VERSION ""

NS_ :

BS_:

BU_: VSIM TTPM TCM SGW SCCM RF_HUB PTS PCM ORC ITBM IRCM IC FTM FDCM ETM ESM ESC ECM DTCM DIAGNOST CBC ATMM ASCM AFLS 4 _ 0 C I w E 6 S A V Vector__XXX T

BO_ 999 BU_NET_CFG_PT: 8 RF_HUB
 SG_ BU_NET_CFG_STAT_PT : 0|2@1+ (1,0) [0|0] "" SGW,CBC
 SG_ BU_NetCfg_ACC : 2|1@1+ (1,0) [0|0] "" SGW,CBC
 SG_ BU_NetCfg_ADCM : 3|1@1+ (1,0) [0|0] "" SGW,CBC
 SG_ BU_NetCfg_AHLM : 4|1@1+ (1,0) [0|0] "" SGW,CBC
 SG_ BU_NetCfg_VSIM_C : 5|1@1+ (1,0) [0|0] "" SGW,CBC
 SG_ BU_NetCfg_ASCM : 6|1@1+ (1,0) [0|0] "" SGW,CBC
 SG_ BU_NetCfg_CBC_PT : 7|1@1+ (1,0) [0|0] "" SGW,CBC
 SG_ BU_NetCfg_DTCM : 8|1@1+ (1,0) [0|0] "" SGW,CBC
 SG_ BU_NetCfg_ECM : 9|1@1+ (1,0) [0|0] "" SGW,CBC
 SG_ BU_NetCfg_EPS : 10|1@1+ (1,0) [0|0] "" SGW,CBC
 SG_ BU_NetCfg_ESM : 11|1@1+ (1,0) [0|0] "" SGW,CBC
 SG_ BU_NetCfg_ESC : 12|1@1+ (1,0) [0|0] "" SGW,CBC
 SG_ BU_NetCfg_EPB : 13|1@1+ (1,0) [0|0] "" SGW,CBC
 SG_ BU_NetCfg_RF_HUB : 14|1@1+ (1,0) [0|0] "" SGW,CBC
 SG_ BU_NetCfg_IC : 15|1@1+ (1,0) [0|0] "" SGW,CBC
 SG_ BU_NetCfg_DASM : 16|1@1+ (1,0) [0|0] "" SGW,CBC
 SG_ BU_NetCfg_FDCM : 17|1@1+ (1,0) [0|0] "" SGW,CBC
 SG_ BU_NetCfg_EPPM : 18|1@1+ (1,0) [0|0] "" SGW,CBC
 SG_ BU_NetCfg_ORC : 19|1@1+ (1,0) [0|0] "" SGW,CBC
 SG_ BU_NetCfg_PTS : 20|1@1+ (1,0) [0|0] "" SGW,CBC
 SG_ BU_NetCfg_SCCM : 23|1@1+ (1,0) [0|0] "" SGW,CBC
 SG_ BU_NetCfg_ELSD : 24|1@1+ (1,0) [0|0] "" SGW,CBC
 SG_ BU_NetCfg_TCM : 25|1@1+ (1,0) [0|0] "" SGW,CBC
 SG_ BU_NetCfg_TPM : 26|1@1+ (1,0) [0|0] "" SGW,CBC
 SG_ BU_NetCfg_PASS_PT : 27|1@1+ (1,0) [0|0] "" SGW,CBC
 SG_ BU_NetCfg_AFLS : 28|1@1+ (1,0) [0|0] "" SGW,CBC
 SG_ BU_NetCfg_ITBM : 29|1@1+ (1,0) [0|0] "" SGW,CBC
 SG_ BU_NetCfg_OCM : 30|1@1+ (1,0) [0|0] "" SGW,CBC
 SG_ BU_NetCfg_HaLF : 31|1@1+ (1,0) [0|0] "" SGW,CBC
 SG_ BU_NetCfg_ANC : 39|1@1+ (1,0) [0|0] "" SGW,CBC
 SG_ BU_NetCfg_HCP : 38|1@1+ (1,0) [0|0] "" SGW,CBC
 SG_ BU_NetCfg_ESL : 37|1@1+ (1,0) [0|0] "" SGW,CBC
 SG_ BU_NetCfg_BSMO : 36|1@1+ (1,0) [0|0] "" SGW,CBC
 SG_ BU_NetCfg_SGW : 34|1@1+ (1,0) [0|0] "" SGW,CBC
 SG_ BU_NetCfg_DPDM : 33|1@1+ (1,0) [0|0] "" SGW,CBC
 SG_ BU_NetCfg_ASBS : 35|1@1+ (1,0) [0|0] "" SGW,CBC
 SG_ BU_NetCfg_ATMM : 32|1@1+ (1,0) [0|0] "" SGW,CBC
 SG_ BU_NetCfg_SWSM : 57|1@1+ (1,0) [0|0] "" SGW,CBC
 SG_ BU_NetCfg_MSBD : 56|1@1+ (1,0) [0|0] "" SGW,CBC

BO_ 1000 VehCfg1: 8 CBC
 SG_ VC_VehCfg1_Stat : 0|2@1+ (1,0) [0|0] "" TTPM,ATMM,IRCM,SGW,ITBM,FDCM,PCM,VSIM,TCM,SCCM,RF_HUB,PTS,ORC,IC,ETM,ESM,ESC,ECM,DTCM,ASCM,AFLS
 SG_ VC_MODEL_YEAR : 2|6@1+ (1,2000) [2000|2062] "model-year" TTPM,ATMM,IRCM,SGW,ITBM,FDCM,PCM,VSIM,TCM,SCCM,RF_HUB,PTS,ORC,IC,ETM,ESM,ESC,ECM,DTCM,ASCM,AFLS
 SG_ VC_VEH_LINE : 8|8@1+ (1,0) [0|0] "" TTPM,ATMM,IRCM,SGW,ITBM,FDCM,PCM,VSIM,TCM,SCCM,RF_HUB,PTS,ORC,IC,ETM,ESM,ESC,ECM,DTCM,ASCM,AFLS
 SG_ VC_COUNTRY : 16|5@1+ (1,0) [0|0] "" TTPM,ATMM,IRCM,SGW,ITBM,FDCM,PCM,VSIM,TCM,SCCM,RF_HUB,PTS,ORC,IC,ETM,ESM,ESC,ECM,DTCM,ASCM,AFLS
 SG_ VC_LHD_RHD : 21|2@1+ (1,0) [0|0] "" IRCM,SGW,RF_HUB,ORC,IC,ETM,DTCM
 SG_ VC_RemStPrsnt : 23|1@1+ (1,0) [0|0] "" SGW,TCM,RF_HUB,IC
 SG_ VC_XWD : 24|2@1+ (1,0) [0|0] "" ATMM,IRCM,SGW,PCM,TCM,RF_HUB,ESC,ECM,DTCM,ASCM
 SG_ VC_EmodePrsnt : 26|1@1+ (1,0) [0|0] "" SGW,RF_HUB
 SG_ VC_AUTO_HB : 27|1@1+ (1,0) [0|0] "" IRCM,SGW,RF_HUB
 SG_ VC_BODY_STYLE : 28|4@1+ (1,0) [0|0] "" TTPM,ATMM,IRCM,SGW,ITBM,FDCM,PCM,VSIM,TCM,SCCM,RF_HUB,PTS,ORC,IC,ETM,ESM,ESC,ECM,DTCM,ASCM,AFLS
 SG_ VC_MAX_VEH_SPD : 32|8@1+ (2,0) [0|506] "kph" SGW,RF_HUB
 SG_ VC_ShftrTyp : 40|4@1+ (1,0) [0|0] "" SGW,TCM,RF_HUB,IC
 SG_ VC_PTS_DispTyp : 44|3@1+ (1,0) [0|0] "" SGW,RF_HUB
 SG_ VC_PP_Prsnt : 47|1@1+ (1,0) [0|0] "" SGW,RF_HUB
 SG_ VC_SpecialPKG : 48|8@1+ (1,0) [1|254] "" SGW,RF_HUB
 SG_ VC_HdRstPrsnt : 56|1@1+ (1,0) [0|0] "" SGW,RF_HUB
 SG_ VC_SCR_Prsnt : 57|1@1+ (1,0) [0|0] "" SGW,PCM,RF_HUB,IC,ECM
 SG_ VC_PTS_Config : 58|2@1+ (1,0) [0|0] "" SGW,RF_HUB,IC
 SG_ VC_RVCM_Prsnt : 60|1@1+ (1,0) [0|0] "" SGW,RF_HUB
 SG_ VC_CHMCM_Prsnt : 61|1@1+ (1,0) [0|0] "" SGW,RF_HUB
 SG_ VC_HDC_Prsnt : 62|1@1+ (1,0) [0|0] "" IRCM,SGW,PCM,TCM,RF_HUB,IC,ESC
 SG_ VC_SSC_Prsnt : 63|1@1+ (1,0) [0|0] "" SGW,RF_HUB

BO_ 1001 VehCfg2: 8 CBC
 SG_ VC_VehCfg2_Stat : 0|2@1+ (1,0) [0|0] "" IRCM,SGW,PCM,TCM,SCCM,RF_HUB,ORC,IC,ESM,ESC,ECM,ASCM
 SG_ VC_PwrIvtrTyp : 2|2@1+ (1,0) [0|0] "" SGW,RF_HUB
 SG_ VC_ThatchamPrsnt : 4|1@1+ (1,0) [0|0] "" SGW,RF_HUB
 SG_ VC_RunFlatTirePrsnt : 5|1@1+ (1,0) [0|0] "" SGW,RF_HUB
 SG_ VC_MaseratiMd : 6|2@1+ (1,0) [0|0] "" SGW,RF_HUB
 SG_ VC_PADS_Prsnt : 8|1@1+ (1,0) [0|0] "" SGW,RF_HUB
 SG_ VC_RainSnsPrsnt : 9|1@1+ (1,0) [0|0] "" SGW,RF_HUB
 SG_ VC_SKIM_PRSNT : 10|1@1+ (1,0) [0|0] "" SGW,RF_HUB
 SG_ VC_AC_Prsnt : 11|1@1+ (1,0) [0|0] "" SGW,RF_HUB
 SG_ VC_CRUISE_PRSNT : 12|1@1+ (1,0) [0|0] "" IRCM,SGW,PCM,TCM,SCCM,RF_HUB,IC,ECM
 SG_ VC_FG_PRSNT : 13|1@1+ (1,0) [0|0] "" SGW,RF_HUB
 SG_ VC_FULL_SPARE : 14|1@1+ (1,0) [0|0] "" SGW,RF_HUB
 SG_ VC_OffRoad : 15|1@1+ (1,0) [0|0] "" SGW,RF_HUB
 SG_ VC_SpecialPKG_IC : 16|8@1+ (1,0) [0|0] "" SGW,RF_HUB,IC
 SG_ VC_ECO_Indicator : 24|1@1+ (1,0) [0|0] "" SGW,RF_HUB
 SG_ VC_DRVMD_Prsnt : 25|1@1+ (1,0) [0|0] "" SGW,RF_HUB
 SG_ VC_MemoryDRVMD_Prsnt : 26|1@1+ (1,0) [0|0] "" SGW,RF_HUB
 SG_ VC_ESCDrvMd_Prsnt : 27|1@1+ (1,0) [0|0] "" SGW,RF_HUB
 SG_ VC_EngPowerDrvMd_Prsnt : 28|1@1+ (1,0) [0|0] "" SGW,RF_HUB
 SG_ VC_SecPrkPrsnt : 29|1@1+ (1,0) [0|0] "" SGW,RF_HUB
 SG_ VC_ShftInd_Prsnt : 30|2@1+ (1,0) [0|0] "" SGW,RF_HUB
 SG_ VC_MaxLdPressRrTr : 32|8@1+ (1,0) [0|126] "psi" SGW,RF_HUB,IC
 SG_ VC_MaxLdPressFtTr : 40|8@1+ (1,0) [0|126] "psi" SGW,RF_HUB,IC
 SG_ VC_LgtLdPressRrTr : 48|8@1+ (1,0) [0|126] "psi" SGW,RF_HUB
 SG_ VC_LgtLdPressFtTr : 56|8@1+ (1,0) [0|126] "psi" SGW,RF_HUB

BO_ 1002 VehCfg3: 8 CBC
 SG_ VC_VehCfg3_Stat : 0|2@1+ (1,0) [0|0] "" IRCM,SGW,PCM,VSIM,TCM,SCCM,RF_HUB,PTS,ORC,IC,ESM,ESC,ECM,DTCM
 SG_ VC_POLICE : 2|1@1+ (1,0) [0|0] "" SGW,RF_HUB
 SG_ VC_PWR_LFT_GT : 3|1@1+ (1,0) [0|0] "" SGW,RF_HUB
 SG_ VC_PWR_RT_SLDR : 4|1@1+ (1,0) [0|0] "" SGW,RF_HUB
 SG_ VC_PWR_LT_SLDR : 5|1@1+ (1,0) [0|0] "" SGW,RF_HUB
 SG_ VC_RKE_PRSNT : 6|1@1+ (1,0) [0|0] "" SGW,RF_HUB
 SG_ VC_SunShade_Present : 7|1@1+ (1,0) [0|0] "" SGW,RF_HUB
 SG_ VC_TcaseTyp : 8|4@1+ (1,0) [0|0] "" SGW,RF_HUB,ESC,ECM,DTCM
 SG_ VC_WHL_BASE : 12|2@1+ (1,0) [0|0] "" IRCM,SGW,RF_HUB,IC
 SG_ VC_FOBIKsafeENBL : 14|1@1+ (1,0) [0|0] "" SGW,RF_HUB
 SG_ VC_ELV_Prsnt : 15|1@1+ (1,0) [0|0] "" SGW,RF_HUB
 SG_ VC_FUEL_CAP : 16|8@1+ (1,36) [36|290] "liters" SGW,VSIM,RF_HUB,IC
 SG_ VC_WIN_EXPR_FEAT : 24|2@1+ (1,0) [0|0] "" SGW,RF_HUB
 SG_ VC_ADJ_PDL_PRSNT : 26|1@1+ (1,0) [0|0] "" SGW,RF_HUB
 SG_ VC_AUTO_HL : 27|1@1+ (1,0) [0|0] "" SGW,RF_HUB
 SG_ VC_DrAlrPrsnt : 28|1@1+ (1,0) [0|0] "" SGW,RF_HUB
 SG_ VC_DualFuelSens : 29|1@1+ (1,0) [0|0] "" SGW,PCM,RF_HUB,IC,ECM
 SG_ VC_SRT_PRSNT : 30|1@1+ (1,0) [0|0] "" SGW,RF_HUB
 SG_ VC_DSBL_CLK_DISP : 31|1@1+ (1,0) [0|0] "" SGW,RF_HUB
 SG_ VC_ChassisType : 32|7@1+ (1,0) [0|126] "" SGW,RF_HUB,ORC,ESC,DTCM
 SG_ VC_TEMP_DISP : 39|1@1+ (1,0) [0|0] "" SGW,RF_HUB,IC
 SG_ VC_HVAC_Config : 40|4@1+ (1,0) [0|0] "" SGW,RF_HUB
 SG_ VC_VEH_BRAND : 44|4@1+ (1,0) [0|0] "" SGW,RF_HUB,PTS
 SG_ VC_CMP_DISP : 48|1@1+ (1,0) [0|0] "" SGW,RF_HUB,IC
 SG_ VC_IntEC_MIRR : 49|1@1+ (1,0) [0|0] "" SGW,RF_HUB
 SG_ VC_ESCL_PRSNT : 50|1@1+ (1,0) [0|0] "" SGW,RF_HUB
 SG_ VC_HID_HL : 51|1@1+ (1,0) [0|0] "" SGW,RF_HUB
 SG_ VC_SecLkPrsnt : 52|1@1+ (1,0) [0|0] "" SGW,RF_HUB
 SG_ VC_Liftgate_Trunk : 53|2@1+ (1,0) [0|0] "" SGW,RF_HUB
 SG_ VC_CMS : 55|1@1+ (1,0) [0|0] "" IRCM,SGW,RF_HUB,ESC
 SG_ VC_FCW : 56|1@1+ (1,0) [0|0] "" IRCM,SGW,RF_HUB,ESC
 SG_ VC_Base_TPM : 57|1@1+ (1,0) [0|0] "" SGW,RF_HUB,IC
 SG_ VC_Prem_TPM : 58|1@1+ (1,0) [0|0] "" SGW,RF_HUB,IC
 SG_ VC_PDDL_PRSNT : 59|1@1+ (1,0) [0|0] "" SGW,TCM,RF_HUB
 SG_ VC_SPORT_PRSNT : 60|1@1+ (1,0) [0|0] "" SGW,RF_HUB
 SG_ VC_AutoParkPrsnt : 61|1@1+ (1,0) [0|0] "" SGW,RF_HUB
 SG_ VC_PE_Prsnt : 62|1@1+ (1,0) [0|0] "" SGW,RF_HUB
 SG_ VC_KG_Prsnt : 63|1@1+ (1,0) [0|0] "" SGW,TCM,RF_HUB,IC

BO_ 1003 VehCfg4: 8 CBC
 SG_ VC_TCASE_HI_RATIO : 5|14@0+ (0.001,0) [0|16.382] "" SGW,TCM,RF_HUB,ESC
 SG_ VC_VehCfg4_Stat : 6|2@1+ (1,0) [0|0] "" IRCM,SGW,FDCM,PCM,TCM,RF_HUB,PTS,ORC,ESC,ECM,DTCM
 SG_ VC_AXLE_RATIO : 23|16@0+ (0.001,0) [0|65.534] "" IRCM,SGW,TCM,RF_HUB,ESC,DTCM
 SG_ VC_TCASE_LO_RATIO : 39|16@0+ (0.001,0) [0|65.534] "" SGW,TCM,RF_HUB,ESC
 SG_ VC_TIRE_CIRCUMF : 55|16@0+ (1,0) [0|65534] "mm" IRCM,SGW,TCM,RF_HUB,ORC,ESC,DTCM

BO_ 1004 VehCfgBu1: 8 RF_HUB
 SG_ VC_BU_VehCfg1_Stat : 0|2@1+ (1,0) [0|0] "" SGW,CBC
 SG_ VC_BU_MODEL_YEAR : 2|6@1+ (1,2000) [2000|2062] "model-year" SGW,CBC
 SG_ VC_BU_VEH_LINE : 8|8@1+ (1,0) [0|0] "" SGW,CBC
 SG_ VC_BU_COUNTRY : 16|5@1+ (1,0) [0|0] "" SGW,CBC
 SG_ VC_BU_LHD_RHD : 21|2@1+ (1,0) [0|0] "" SGW,CBC
 SG_ VC_BU_RemStPrsnt : 23|1@1+ (1,0) [0|0] "" SGW,CBC
 SG_ VC_BU_XWD : 24|2@1+ (1,0) [0|0] "" SGW,CBC
 SG_ VC_BU_EmodePrsnt : 26|1@1+ (1,0) [0|0] "" SGW,CBC
 SG_ VC_BU_AUTO_HB : 27|1@1+ (1,0) [0|0] "" SGW,CBC
 SG_ VC_BU_BODY_STYLE : 28|4@1+ (1,0) [0|0] "" SGW,CBC
 SG_ VC_BU_MAX_VEH_SPD : 32|8@1+ (2,0) [0|506] "kph" SGW,CBC
 SG_ VC_BU_ShftrTyp : 40|4@1+ (1,0) [0|0] "" SGW,CBC
 SG_ VC_BU_PTS_DispTyp : 44|3@1+ (1,0) [0|0] "" SGW,CBC
 SG_ VC_BU_PP_Prsnt : 47|1@1+ (1,0) [0|0] "" SGW,CBC
 SG_ VC_BU_SpecialPKG : 48|8@1+ (1,0) [1|254] "" SGW,CBC
 SG_ VC_BU_HdRstPrsnt : 56|1@1+ (1,0) [0|0] "" SGW,CBC
 SG_ VC_BU_SCR_Prsnt : 57|1@1+ (1,0) [0|0] "" SGW,CBC
 SG_ VC_BU_PTS_Config : 58|2@1+ (1,0) [0|0] "" SGW,CBC
 SG_ VC_BU_RVCM_Prsnt : 60|1@1+ (1,0) [0|0] "" SGW,CBC
 SG_ VC_BU_CHMCM_Prsnt : 61|1@1+ (1,0) [0|0] "" SGW,CBC
 SG_ VC_BU_HDC_Prsnt : 62|1@1+ (1,0) [0|0] "" SGW,CBC
 SG_ VC_BU_SSC_Prsnt : 63|1@1+ (1,0) [0|0] "" SGW,CBC

BO_ 1005 VehCfgBu2: 8 RF_HUB
 SG_ VC_BU_VehCfg2_Stat : 0|2@1+ (1,0) [0|0] "" SGW,CBC
 SG_ VC_BU_PwrIvtrTyp : 2|2@1+ (1,0) [0|0] "" SGW,CBC
 SG_ VC_BU_ThatchamPrsnt : 4|1@1+ (1,0) [0|0] "" SGW,CBC
 SG_ VC_BU_RunFlatTirePrsnt : 5|1@1+ (1,0) [0|0] "" SGW,CBC
 SG_ VC_BU_MaseratiMd : 6|2@1+ (1,0) [0|0] "" SGW,CBC
 SG_ VC_BU_PADS_Prsnt : 8|1@1+ (1,0) [0|0] "" SGW,CBC
 SG_ VC_BU_RainSnsPrsnt : 9|1@1+ (1,0) [0|0] "" SGW,CBC
 SG_ VC_BU_SKIM_PRSNT : 10|1@1+ (1,0) [0|0] "" SGW,CBC
 SG_ VC_BU_AC_Prsnt : 11|1@1+ (1,0) [0|0] "" SGW,CBC
 SG_ VC_BU_CRUISE_PRSNT : 12|1@1+ (1,0) [0|0] "" SGW,CBC
 SG_ VC_BU_FG_PRSNT : 13|1@1+ (1,0) [0|0] "" SGW,CBC
 SG_ VC_BU_FULL_SPARE : 14|1@1+ (1,0) [0|0] "" SGW,CBC
 SG_ VC_BU_OffRoad : 15|1@1+ (1,0) [0|0] "" SGW,CBC
 SG_ VC_BU_SpecialPKG_IC : 16|8@1+ (1,0) [0|0] "" SGW,CBC
 SG_ VC_BU_ECO_Indicator : 24|1@1+ (1,0) [0|0] "" SGW,CBC
 SG_ VC_BU_DRVMD_Prsnt : 25|1@1+ (1,0) [0|0] "" SGW,CBC
 SG_ VC_BU_MemoryDRVMD_Prsnt : 26|1@1+ (1,0) [0|0] "" SGW,CBC
 SG_ VC_BU_ESCDrvMd_Prsnt : 27|1@1+ (1,0) [0|0] "" SGW,CBC
 SG_ VC_BU_EngPowerDrvMd_Prsnt : 28|1@1+ (1,0) [0|0] "" SGW,CBC
 SG_ VC_BU_SecPrkPrsnt : 29|1@1+ (1,0) [0|0] "" SGW,CBC
 SG_ VC_BU_ShftInd_Prsnt : 30|2@1+ (1,0) [0|0] "" SGW,CBC
 SG_ VC_BU_MaxLdPressRrTr : 32|8@1+ (1,0) [0|126] "psi" SGW,CBC
 SG_ VC_BU_MaxLdPressFtTr : 40|8@1+ (1,0) [0|126] "psi" SGW,CBC
 SG_ VC_BU_LgtLdPressRrTr : 48|8@1+ (1,0) [0|126] "psi" SGW,CBC
 SG_ VC_BU_LgtLdPressFtTr : 56|8@1+ (1,0) [0|126] "psi" SGW,CBC

BO_ 1006 VehCfgBu3: 8 RF_HUB
 SG_ VC_BU_VehCfg3_Stat : 0|2@1+ (1,0) [0|0] "" SGW,CBC
 SG_ VC_BU_POLICE : 2|1@1+ (1,0) [0|0] "" SGW,CBC
 SG_ VC_BU_PWR_LFT_GT : 3|1@1+ (1,0) [0|0] "" SGW,CBC
 SG_ VC_BU_PWR_RT_SLDR : 4|1@1+ (1,0) [0|0] "" SGW,CBC
 SG_ VC_BU_PWR_LT_SLDR : 5|1@1+ (1,0) [0|0] "" SGW,CBC
 SG_ VC_BU_RKE_PRSNT : 6|1@1+ (1,0) [0|0] "" SGW,CBC
 SG_ VC_BU_SunShade_Present : 7|1@1+ (1,0) [0|0] "" SGW,CBC
 SG_ VC_BU_TcaseTyp : 8|4@1+ (1,0) [0|0] "" SGW,CBC
 SG_ VC_BU_WHL_BASE : 12|2@1+ (1,0) [0|0] "" SGW,CBC
 SG_ VC_BU_FOBIKsafeENBL : 14|1@1+ (1,0) [0|0] "" SGW,CBC
 SG_ VC_BU_ELV_PRSNT : 15|1@1+ (1,0) [0|0] "" SGW,CBC
 SG_ VC_BU_FUEL_CAP : 16|8@1+ (1,36) [36|290] "liters" SGW,CBC
 SG_ VC_BU_WIN_EXPR_FEAT : 24|2@1+ (1,0) [0|0] "" SGW,CBC
 SG_ VC_BU_ADJ_PDL_PRSNT : 26|1@1+ (1,0) [0|0] "" SGW,CBC
 SG_ VC_BU_AUTO_HL : 27|1@1+ (1,0) [0|0] "" SGW,CBC
 SG_ VC_BU_DrAlrPrsnt : 28|1@1+ (1,0) [0|0] "" SGW,CBC
 SG_ VC_BU_DualFuelSens : 29|1@1+ (1,0) [0|0] "" SGW,CBC
 SG_ VC_BU_SRT_PRSNT : 30|1@1+ (1,0) [0|0] "" SGW,CBC
 SG_ VC_BU_DSBL_CLK_DISP : 31|1@1+ (1,0) [0|0] "" SGW,CBC
 SG_ VC_BU_ChassisType : 32|7@1+ (1,0) [0|126] "" SGW,CBC
 SG_ VC_BU_TEMP_DISP : 39|1@1+ (1,0) [0|0] "" SGW,CBC
 SG_ VC_BU_HVAC_Config : 40|4@1+ (1,0) [0|0] "" SGW,CBC
 SG_ VC_BU_VEH_BRAND : 44|4@1+ (1,0) [0|0] "" SGW,CBC
 SG_ VC_BU_CMP_DISP : 48|1@1+ (1,0) [0|0] "" SGW,CBC
 SG_ VC_BU_IntEC_MIRR : 49|1@1+ (1,0) [0|0] "" SGW,CBC
 SG_ VC_BU_ESCL_Prsnt : 50|1@1+ (1,0) [0|0] "" SGW,CBC
 SG_ VC_BU_HID_HL : 51|1@1+ (1,0) [0|0] "" SGW,CBC
 SG_ VC_BU_SecLkPrsnt : 52|1@1+ (1,0) [0|0] "" SGW,CBC
 SG_ VC_BU_Liftgate_Trunk : 53|2@1+ (1,0) [0|0] "" SGW,CBC
 SG_ VC_BU_CMS : 55|1@1+ (1,0) [0|0] "" SGW,CBC
 SG_ VC_BU_FCW : 56|1@1+ (1,0) [0|0] "" SGW,CBC
 SG_ VC_BU_Base_TPM : 57|1@1+ (1,0) [0|0] "" SGW,CBC
 SG_ VC_BU_Prem_TPM : 58|1@1+ (1,0) [0|0] "" SGW,CBC
 SG_ VC_BU_PDDL_PRSNT : 59|1@1+ (1,0) [0|0] "" SGW,CBC
 SG_ VC_BU_SPORT_PRSNT : 60|1@1+ (1,0) [0|0] "" SGW,CBC
 SG_ VC_BU_AutoParkPrsnt : 61|1@1+ (1,0) [0|0] "" SGW,CBC
 SG_ VC_BU_PE_Prsnt : 62|1@1+ (1,0) [0|0] "" SGW,CBC
 SG_ VC_BU_KG_Prsnt : 63|1@1+ (1,0) [0|0] "" SGW,CBC

BO_ 1007 VehCfgBu4: 8 RF_HUB
 SG_ VC_BU_TCASE_HI_RATIO : 5|14@0+ (0.001,0) [0|16.382] "" SGW,CBC
 SG_ VC_BU_VehCfg4_Stat : 6|2@1+ (1,0) [0|0] "" SGW,CBC
 SG_ VC_BU_AXLE_RATIO : 23|16@0+ (0.001,0) [0|65.534] "" SGW,CBC
 SG_ VC_BU_TCASE_LO_RATIO : 39|16@0+ (0.001,0) [0|65.534] "" SGW,CBC
 SG_ VC_BU_TIRE_CIRCUMF : 55|16@0+ (1,0) [0|65534] "mm" SGW,CBC

BO_ 1008 EcuCfg1: 8 CBC
 SG_ EC_ECUCfg1_Stat : 0|2@1+ (1,0) [0|0] "" SGW,RF_HUB
 SG_ EC_CBC1A : 2|6@1+ (1,0) [0|0] "" SGW,RF_HUB
 SG_ EC_CBC1B : 15|24@0+ (1,0) [0|0] "" SGW,RF_HUB
 SG_ EC_CBC2 : 39|32@0+ (1,0) [0|0] "" SGW,RF_HUB

BO_ 1009 EcuCfg2: 8 CBC
 SG_ EC_ECUCfg2_Stat : 0|2@1+ (1,0) [0|0] "" SGW,RF_HUB
 SG_ EC_CBC3A : 2|6@1+ (1,0) [0|0] "" SGW,RF_HUB
 SG_ EC_CBC3B : 15|24@0+ (1,0) [0|0] "" SGW,RF_HUB
 SG_ EC_CBC4 : 39|32@0+ (1,0) [0|0] "" SGW,RF_HUB

BO_ 1010 EcuCfg3: 8 CBC
 SG_ EC_ECUCfg3_Stat : 0|2@1+ (1,0) [0|0] "" SGW,RF_HUB
 SG_ EC_AudTel1A : 2|6@1+ (1,0) [0|0] "" SGW,RF_HUB
 SG_ EC_AudTel1B : 15|24@0+ (1,0) [0|0] "" SGW,RF_HUB
 SG_ EC_AudTel2 : 39|32@0+ (1,0) [0|0] "" SGW,RF_HUB

BO_ 1011 EcuCfg4: 8 CBC
 SG_ EC_ECUCfg4_Stat : 0|2@1+ (1,0) [0|0] "" SGW,RF_HUB,IC
 SG_ EC_Cluster1A : 2|6@1+ (1,0) [0|0] "" SGW,RF_HUB,IC
 SG_ EC_Cluster1B : 15|24@0+ (1,0) [0|0] "" SGW,RF_HUB,IC
 SG_ EC_Cluster2 : 39|32@0+ (1,0) [0|0] "" SGW,RF_HUB,IC

BO_ 1012 EcuCfg5: 8 CBC
 SG_ EC_ECUCfg5_Stat : 0|2@1+ (1,0) [0|0] "" SGW,RF_HUB
 SG_ EC_WirelessA : 2|6@1+ (1,0) [0|0] "" SGW,RF_HUB
 SG_ EC_WirelessB : 15|16@0+ (1,0) [0|0] "" SGW,RF_HUB
 SG_ EC_Doors : 31|24@0+ (1,0) [0|0] "" SGW,RF_HUB
 SG_ EC_Memory : 55|16@0+ (1,0) [0|0] "" SGW,RF_HUB

BO_ 1013 EcuCfg6: 8 CBC
 SG_ EC_ECUCfg6_Stat : 0|2@1+ (1,0) [0|0] "" SGW,PCM,TCM,RF_HUB,PTS,ORC,ESC,ECM
 SG_ EC_BrakesA : 2|6@1+ (1,0) [0|0] "" SGW,RF_HUB,ESC
 SG_ EC_BrakesB : 8|8@1+ (1,0) [0|0] "" SGW,RF_HUB,ESC
 SG_ EC_Steering : 23|16@0+ (1,0) [0|0] "" SGW,RF_HUB,ESC
 SG_ EC_Powertrain : 39|16@0+ (1,0) [0|0] "" SGW,PCM,RF_HUB,ECM
 SG_ EC_Safety : 55|16@0+ (1,0) [0|0] "" SGW,RF_HUB,ORC

BO_ 1014 EcuCfg7: 8 CBC
 SG_ EC_ECUCfg7_Stat : 0|2@1+ (1,0) [0|0] "" SGW,RF_HUB
 SG_ EC_CBC5A : 2|6@1+ (1,0) [0|0] "" SGW,RF_HUB
 SG_ EC_CBC5B : 15|24@0+ (1,0) [0|0] "" SGW,RF_HUB
 SG_ EC_CBC6 : 39|32@0+ (1,0) [0|0] "" SGW,RF_HUB

BO_ 1015 EcuCfg8: 8 CBC
 SG_ EC_ECUCfg8_Stat : 0|2@1+ (1,0) [0|0] "" SGW,RF_HUB
 SG_ EC_CBC7A : 2|6@1+ (1,0) [0|0] "" SGW,RF_HUB
 SG_ EC_CBC7B : 15|24@0+ (1,0) [0|0] "" SGW,RF_HUB
 SG_ EC_CBC8 : 39|32@0+ (1,0) [0|0] "" SGW,RF_HUB

BO_ 1016 EcuBuCfg1: 8 RF_HUB
 SG_ EC_BU_ECUCfg1_Stat : 0|2@1+ (1,0) [0|0] "" SGW,CBC
 SG_ EC_BU_CBC1A : 2|6@1+ (1,0) [0|0] "" SGW,CBC
 SG_ EC_BU_CBC1B : 15|24@0+ (1,0) [0|0] "" SGW,CBC
 SG_ EC_BU_CBC2 : 39|32@0+ (1,0) [0|0] "" SGW,CBC

BO_ 1017 EcuBuCfg2: 8 RF_HUB
 SG_ EC_BU_ECUCfg2_Stat : 0|2@1+ (1,0) [0|0] "" SGW,CBC
 SG_ EC_BU_CBC3A : 2|6@1+ (1,0) [0|0] "" SGW,CBC
 SG_ EC_BU_CBC3B : 15|24@0+ (1,0) [0|0] "" SGW,CBC
 SG_ EC_BU_CBC4 : 39|32@0+ (1,0) [0|0] "" SGW,CBC

BO_ 1018 EcuBuCfg3: 8 RF_HUB
 SG_ EC_BU_ECUCfg3_Stat : 0|2@1+ (1,0) [0|0] "" SGW,CBC
 SG_ EC_BU_AudTel1A : 2|6@1+ (1,0) [0|0] "" SGW,CBC
 SG_ EC_BU_AudTel1B : 15|24@0+ (1,0) [0|0] "" SGW,CBC
 SG_ EC_BU_AudTel2 : 39|32@0+ (1,0) [0|0] "" SGW,CBC

BO_ 1019 EcuBuCfg4: 8 RF_HUB
 SG_ EC_BU_ECUCfg4_Stat : 0|2@1+ (1,0) [0|0] "" SGW,CBC
 SG_ EC_BU_Cluster1A : 2|6@1+ (1,0) [0|0] "" SGW,CBC
 SG_ EC_BU_Cluster1B : 15|24@0+ (1,0) [0|0] "" SGW,CBC
 SG_ EC_BU_Cluster2 : 39|32@0+ (1,0) [0|0] "" SGW,CBC

BO_ 1020 EcuBuCfg5: 8 RF_HUB
 SG_ EC_BU_ECUCfg5_Stat : 0|2@1+ (1,0) [0|0] "" SGW,CBC
 SG_ EC_BU_WirelessA : 2|6@1+ (1,0) [0|0] "" SGW,CBC
 SG_ EC_BU_WirelessB : 15|16@0+ (1,0) [0|0] "" SGW,CBC
 SG_ EC_BU_Doors : 31|24@0+ (1,0) [0|0] "" SGW,CBC
 SG_ EC_BU_Memory : 55|16@0+ (1,0) [0|0] "" SGW,CBC

BO_ 1021 EcuBuCfg6: 8 RF_HUB
 SG_ EC_BU_ECUCfg6_Stat : 0|2@1+ (1,0) [0|0] "" SGW,CBC
 SG_ EC_BU_BrakesA : 2|6@1+ (1,0) [0|0] "" SGW,CBC
 SG_ EC_BU_BrakesB : 8|8@1+ (1,0) [0|0] "" SGW,CBC
 SG_ EC_BU_Steering : 23|16@0+ (1,0) [0|0] "" SGW,CBC
 SG_ EC_BU_Powertrain : 39|16@0+ (1,0) [0|0] "" SGW,CBC
 SG_ EC_BU_Safety : 55|16@0+ (1,0) [0|0] "" SGW,CBC

BO_ 1022 EcuBuCfg7: 8 RF_HUB
 SG_ EC_BU_ECUCfg7_Stat : 0|2@1+ (1,0) [0|0] "" SGW,CBC
 SG_ EC_BU_CBC5A : 2|6@1+ (1,0) [0|0] "" SGW,CBC
 SG_ EC_BU_CBC5B : 15|24@0+ (1,0) [0|0] "" SGW,CBC
 SG_ EC_BU_CBC6 : 39|32@0+ (1,0) [0|0] "" SGW,CBC

BO_ 1023 EcuBuCfg8: 8 RF_HUB
 SG_ EC_BU_ECUCfg8_Stat : 0|2@1+ (1,0) [0|0] "" SGW,CBC
 SG_ EC_BU_CBC7A : 2|6@1+ (1,0) [0|0] "" SGW,CBC
 SG_ EC_BU_CBC7B : 15|24@0+ (1,0) [0|0] "" SGW,CBC
 SG_ EC_BU_CBC8 : 39|32@0+ (1,0) [0|0] "" SGW,CBC

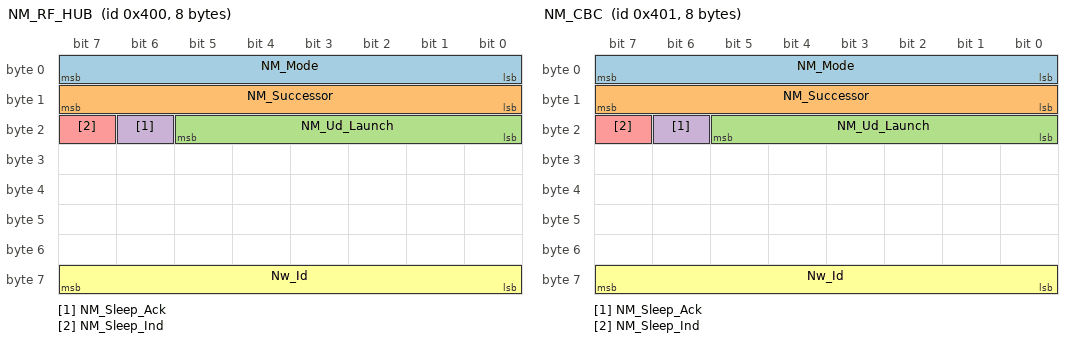
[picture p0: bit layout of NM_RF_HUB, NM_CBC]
BO_ 1024 NM_RF_HUB: 8 RF_HUB
 SG_ NM_Mode : 0|8@1+ (1,0) [0|0] "" TTPM,SGW,VSIM,SCCM,RF_HUB,IC,ESM,ESC,CBC,ASCM
 SG_ NM_Successor : 8|8@1+ (1,0) [0|63] "" TTPM,SGW,VSIM,SCCM,RF_HUB,IC,ESM,ESC,CBC,ASCM
 SG_ NM_Ud_Launch : 16|6@1+ (1,0) [0|0] "" TTPM,SGW,VSIM,SCCM,RF_HUB,IC,ESM,ESC,CBC,ASCM
 SG_ NM_Sleep_Ack : 22|1@1+ (1,0) [0|0] "" TTPM,SGW,VSIM,SCCM,RF_HUB,IC,ESM,ESC,CBC,ASCM
 SG_ NM_Sleep_Ind : 23|1@1+ (1,0) [0|0] "" TTPM,SGW,VSIM,SCCM,RF_HUB,IC,ESM,ESC,CBC,ASCM
 SG_ N : NaN|NaN@0+ (NaN,NaN) [NaN|NaN] "2" 4
 SG_ A : NaN|NaN@0+ (NaN,NaN) [NaN|NaN] "g" _
 SG_ W : NaN|NaN@0+ (NaN,NaN) [NaN|NaN] "4" 0
 SG_ Nw_Id : 56|8@1+ (1,0) [0|0] "" TTPM,SGW,VSIM,SCCM,RF_HUB,IC,ESM,ESC,CBC,ASCM

BO_ 1025 NM_CBC: 8 CBC
 SG_ NM_Mode : 0|8@1+ (1,0) [0|0] "" TTPM,SGW,VSIM,SCCM,RF_HUB,IC,ESM,ESC,CBC,ASCM
 SG_ NM_Successor : 8|8@1+ (1,0) [0|63] "" TTPM,SGW,VSIM,SCCM,RF_HUB,IC,ESM,ESC,CBC,ASCM
 SG_ NM_Ud_Launch : 16|6@1+ (1,0) [0|0] "" TTPM,SGW,VSIM,SCCM,RF_HUB,IC,ESM,ESC,CBC,ASCM
 SG_ NM_Sleep_Ack : 22|1@1+ (1,0) [0|0] "" TTPM,SGW,VSIM,SCCM,RF_HUB,IC,ESM,ESC,CBC,ASCM
 SG_ NM_Sleep_Ind : 23|1@1+ (1,0) [0|0] "" TTPM,SGW,VSIM,SCCM,RF_HUB,IC,ESM,ESC,CBC,ASCM
 SG_ N : NaN|NaN@0+ (NaN,NaN) [NaN|NaN] "2" 4
 SG_ A : NaN|NaN@0+ (NaN,NaN) [NaN|NaN] "g" _
 SG_ W : NaN|NaN@0+ (NaN,NaN) [NaN|NaN] "_" C
 SG_ Nw_Id : 56|8@1+ (1,0) [0|0] "" TTPM,SGW,VSIM,SCCM,RF_HUB,IC,ESM,ESC,CBC,ASCM

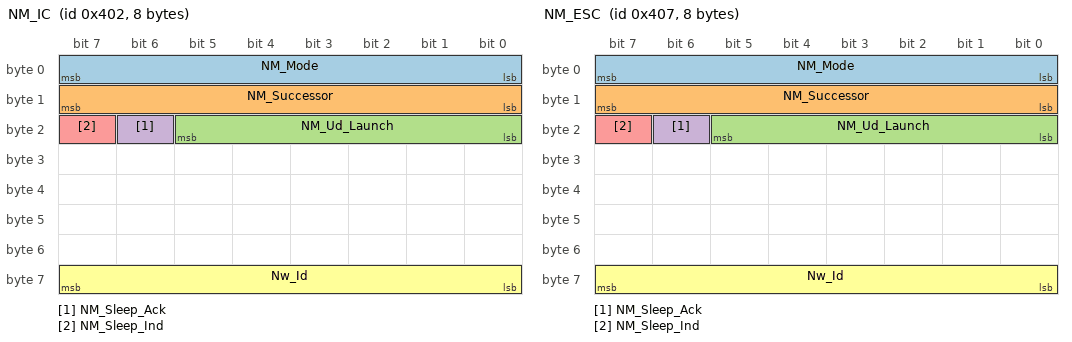
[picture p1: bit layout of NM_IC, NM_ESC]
BO_ 1026 NM_IC: 8 IC
 SG_ NM_Mode : 0|8@1+ (1,0) [0|0] "" TTPM,SGW,VSIM,SCCM,RF_HUB,IC,ESM,ESC,CBC,ASCM
 SG_ NM_Successor : 8|8@1+ (1,0) [0|63] "" TTPM,SGW,VSIM,SCCM,RF_HUB,IC,ESM,ESC,CBC,ASCM
 SG_ NM_Ud_Launch : 16|6@1+ (1,0) [0|0] "" TTPM,SGW,VSIM,SCCM,RF_HUB,IC,ESM,ESC,CBC,ASCM
 SG_ NM_Sleep_Ack : 22|1@1+ (1,0) [0|0] "" TTPM,SGW,VSIM,SCCM,RF_HUB,IC,ESM,ESC,CBC,ASCM
 SG_ NM_Sleep_Ind : 23|1@1+ (1,0) [0|0] "" TTPM,SGW,VSIM,SCCM,RF_HUB,IC,ESM,ESC,CBC,ASCM
 SG_ N : NaN|NaN@0+ (NaN,NaN) [NaN|NaN] "2" 4
 SG_ A : NaN|NaN@0+ (NaN,NaN) [NaN|NaN] "g" _
 SG_ W : NaN|NaN@0+ (NaN,NaN) [NaN|NaN] "_" I
 SG_ Nw_Id : 56|8@1+ (1,0) [0|0] "" TTPM,SGW,VSIM,SCCM,RF_HUB,IC,ESM,ESC,CBC,ASCM

BO_ 1031 NM_ESC: 8 ESC
 SG_ NM_Mode : 0|8@1+ (1,0) [0|0] "" TTPM,SGW,VSIM,SCCM,RF_HUB,IC,ESM,ESC,CBC,ASCM
 SG_ NM_Successor : 8|8@1+ (1,0) [0|63] "" TTPM,SGW,VSIM,SCCM,RF_HUB,IC,ESM,ESC,CBC,ASCM
 SG_ NM_Ud_Launch : 16|6@1+ (1,0) [0|0] "" TTPM,SGW,VSIM,SCCM,RF_HUB,IC,ESM,ESC,CBC,ASCM
 SG_ NM_Sleep_Ack : 22|1@1+ (1,0) [0|0] "" TTPM,SGW,VSIM,SCCM,RF_HUB,IC,ESM,ESC,CBC,ASCM
 SG_ NM_Sleep_Ind : 23|1@1+ (1,0) [0|0] "" TTPM,SGW,VSIM,SCCM,RF_HUB,IC,ESM,ESC,CBC,ASCM
 SG_ N : NaN|NaN@0+ (NaN,NaN) [NaN|NaN] "2" 4
 SG_ A : NaN|NaN@0+ (NaN,NaN) [NaN|NaN] "d" w
 SG_ W : NaN|NaN@0+ (NaN,NaN) [NaN|NaN] "_" E
 SG_ Nw_Id : 56|8@1+ (1,0) [0|0] "" TTPM,SGW,VSIM,SCCM,RF_HUB,IC,ESM,ESC,CBC,ASCM

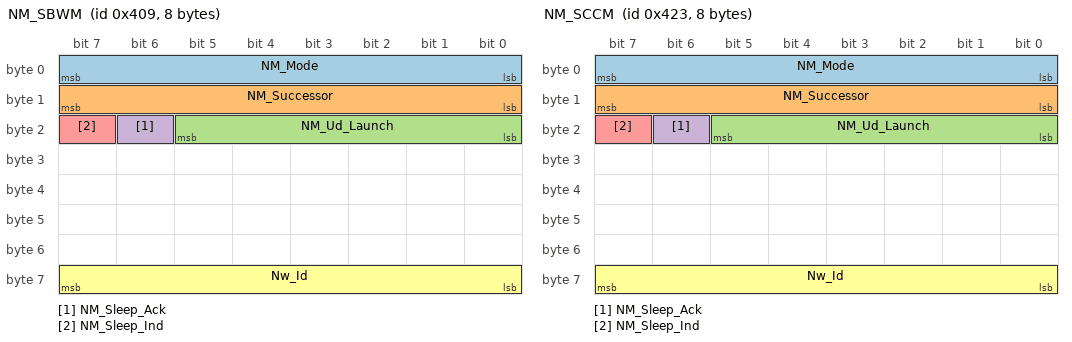
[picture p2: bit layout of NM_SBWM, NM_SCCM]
BO_ 1033 NM_SBWM: 8 ESM
 SG_ NM_Mode : 0|8@1+ (1,0) [0|0] "" TTPM,SGW,VSIM,SCCM,RF_HUB,IC,ESM,ESC,CBC,ASCM
 SG_ NM_Successor : 8|8@1+ (1,0) [0|63] "" TTPM,SGW,VSIM,SCCM,RF_HUB,IC,ESM,ESC,CBC,ASCM
 SG_ NM_Ud_Launch : 16|6@1+ (1,0) [0|0] "" TTPM,SGW,VSIM,SCCM,RF_HUB,IC,ESM,ESC,CBC,ASCM
 SG_ NM_Sleep_Ack : 22|1@1+ (1,0) [0|0] "" TTPM,SGW,VSIM,SCCM,RF_HUB,IC,ESM,ESC,CBC,ASCM
 SG_ NM_Sleep_Ind : 23|1@1+ (1,0) [0|0] "" TTPM,SGW,VSIM,SCCM,RF_HUB,IC,ESM,ESC,CBC,ASCM
 SG_ N : NaN|NaN@0+ (NaN,NaN) [NaN|NaN] "2" 4
 SG_ A : NaN|NaN@0+ (NaN,NaN) [NaN|NaN] "3" 6
 SG_ W : NaN|NaN@0+ (NaN,NaN) [NaN|NaN] "_" S
 SG_ Nw_Id : 56|8@1+ (1,0) [0|0] "" TTPM,SGW,VSIM,SCCM,RF_HUB,IC,ESM,ESC,CBC,ASCM

BO_ 1059 NM_SCCM: 8 SCCM
 SG_ NM_Mode : 0|8@1+ (1,0) [0|0] "" TTPM,SGW,VSIM,SCCM,RF_HUB,IC,ESM,ESC,CBC,ASCM
 SG_ NM_Successor : 8|8@1+ (1,0) [0|63] "" TTPM,SGW,VSIM,SCCM,RF_HUB,IC,ESM,ESC,CBC,ASCM
 SG_ NM_Ud_Launch : 16|6@1+ (1,0) [0|0] "" TTPM,SGW,VSIM,SCCM,RF_HUB,IC,ESM,ESC,CBC,ASCM
 SG_ NM_Sleep_Ack : 22|1@1+ (1,0) [0|0] "" TTPM,SGW,VSIM,SCCM,RF_HUB,IC,ESM,ESC,CBC,ASCM
 SG_ NM_Sleep_Ind : 23|1@1+ (1,0) [0|0] "" TTPM,SGW,VSIM,SCCM,RF_HUB,IC,ESM,ESC,CBC,ASCM
 SG_ N : NaN|NaN@0+ (NaN,NaN) [NaN|NaN] "2" 4
 SG_ A : NaN|NaN@0+ (NaN,NaN) [NaN|NaN] "S" w
 SG_ W : NaN|NaN@0+ (NaN,NaN) [NaN|NaN] "_" S
 SG_ Nw_Id : 56|8@1+ (1,0) [0|0] "" TTPM,SGW,VSIM,SCCM,RF_HUB,IC,ESM,ESC,CBC,ASCM

BO_ 1089 DG_RQ_GLOBAL_UDS: 8 DIAGNOST
 SG_ DG_RQ_GLOBAL_UDS : 7|64@0+ (1,0) [0|0] "" TTPM,ATMM,IRCM,ITBM,FDCM,PCM,VSIM,TCM,SCCM,RF_HUB,PTS,ORC,IC,ETM,ESM,ESC,ECM,DTCM,CBC,ASCM,AFLS

BO_ 1098 VehCfg5: 8 CBC
 SG_ VC_VehCfg5_Stat : 0|2@1+ (1,0) [0|0] "" IRCM,SGW,PCM,SCCM,RF_HUB,PTS,ORC,IC,ESC,ECM
 SG_ VC_LUCI_PRSNT : 2|1@1+ (1,0) [0|0] "" SGW,RF_HUB
 SG_ VC_RR_DuallyPrsnt : 3|1@1+ (1,0) [0|0] "" SGW,TCM,RF_HUB,PTS,IC,ESC
 SG_ VC_NonReg_TPIS : 4|1@1+ (1,0) [0|0] "" SGW,RF_HUB,IC
 SG_ VC_WTS_Prsnt : 5|1@1+ (1,0) [0|0] "" SGW,RF_HUB
 SG_ VC_AmbTempLct : 6|2@1+ (1,0) [0|0] "" SGW,RF_HUB
 SG_ VC_Strng_Rt_0 : 8|8@1+ (0.1,0) [0|25.4] "" SGW,RF_HUB,ESC
 SG_ VC_Strng_Rt_pls1 : 16|8@1+ (0.1,0) [0|25.4] "" SGW,RF_HUB,ESC
 SG_ VC_Strng_Rt_pls2 : 24|8@1+ (0.1,0) [0|25.4] "" SGW,RF_HUB,ESC
 SG_ VC_Strng_Rt_pls3 : 32|8@1+ (0.1,0) [0|25.4] "" SGW,RF_HUB,ESC
 SG_ VC_Strng_Rt_pls4 : 40|8@1+ (0.1,0) [0|25.4] "" SGW,RF_HUB,ESC
 SG_ VC_Strng_Rt_pls5 : 48|8@1+ (0.1,0) [0|25.4] "" SGW,RF_HUB,ESC
 SG_ VC_RearDoorLocks2DCM : 56|1@1+ (1,0) [0|0] "" SGW,RF_HUB
 SG_ VC_SpdLmt_PRSNT : 57|1@1+ (1,0) [0|0] "" SGW,PCM,SCCM,RF_HUB,ECM
 SG_ VC_SBR_Prsnt : 58|1@1+ (1,0) [0|0] "" SGW,RF_HUB
 SG_ VC_ChildDisp_Prsnt : 59|1@1+ (1,0) [0|0] "" SGW,RF_HUB
 SG_ VC_OffRoadPg : 60|1@1+ (1,0) [0|0] "" SGW,RF_HUB
 SG_ VC_AmbLtgPrsnt : 61|1@1+ (1,0) [0|0] "" SGW,RF_HUB
 SG_ VC_PPPA_Prsnt : 62|1@1+ (1,0) [0|0] "" SGW,PCM,RF_HUB,ECM
 SG_ VC_ParkStopPrsnt : 63|1@1+ (1,0) [0|0] "" SGW,RF_HUB,ESC

BO_ 1099 VehCfgBu5: 8 RF_HUB
 SG_ VC_BU_VehCfg5_Stat : 0|2@1+ (1,0) [0|0] "" SGW,CBC
 SG_ VC_BU_LUCI_PRSNT : 2|1@1+ (1,0) [0|0] "" SGW,CBC
 SG_ VC_BU_RR_DuallyPrsnt : 3|1@1+ (1,0) [0|0] "" SGW,CBC
 SG_ VC_BU_NonReg_TPIS : 4|1@1+ (1,0) [0|0] "" SGW,CBC
 SG_ VC_BU_WTS_Prsnt : 5|1@1+ (1,0) [0|0] "" SGW,CBC
 SG_ VC_BU_AmbTempLct : 6|2@1+ (1,0) [0|0] "" SGW,CBC
 SG_ VC_BU_Strng_Rt_0 : 8|8@1+ (0.1,0) [0|25.4] "" SGW,CBC
 SG_ VC_BU_Strng_Rt_pls1 : 16|8@1+ (0.1,0) [0|25.4] "" SGW,CBC
 SG_ VC_BU_Strng_Rt_pls2 : 24|8@1+ (0.1,0) [0|25.4] "" SGW,CBC
 SG_ VC_BU_Strng_Rt_pls3 : 32|8@1+ (0.1,0) [0|25.4] "" SGW,CBC
 SG_ VC_BU_Strng_Rt_pls4 : 40|8@1+ (0.1,0) [0|25.4] "" SGW,CBC
 SG_ VC_BU_Strng_Rt_pls5 : 48|8@1+ (0.1,0) [0|25.4] "" SGW,CBC
 SG_ VC_BU_RearDoorLocks2DCM : 56|1@1+ (1,0) [0|0] "" SGW,CBC
 SG_ VC_BU_SpdLmt_PRSNT : 57|1@1+ (1,0) [0|0] "" SGW,CBC
 SG_ VC_BU_SBR_Prsnt : 58|1@1+ (1,0) [0|0] "" SGW,CBC
 SG_ VC_BU_ChildDisp_Prsnt : 59|1@1+ (1,0) [0|0] "" SGW,CBC
 SG_ VC_BU_OffRoadPg : 60|1@1+ (1,0) [0|0] "" SGW,CBC
 SG_ VC_BU_AmbLtgPrsnt : 61|1@1+ (1,0) [0|0] "" SGW,CBC
 SG_ VC_BU_PPPA_Prsnt : 62|1@1+ (1,0) [0|0] "" SGW,CBC
 SG_ VC_BU_ParkStopPrsnt : 63|1@1+ (1,0) [0|0] "" SGW,CBC

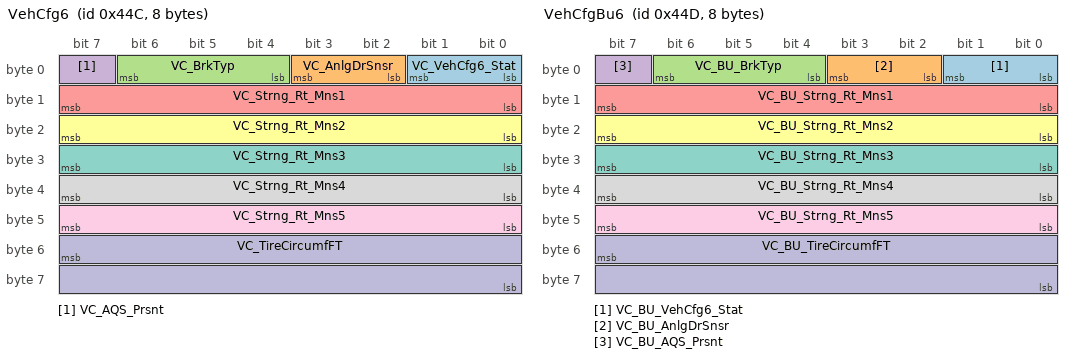
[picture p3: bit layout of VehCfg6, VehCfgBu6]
BO_ 1100 VehCfg6: 8 CBC
 SG_ VC_VehCfg6_Stat : 0|2@1+ (1,0) [0|0] "" IRCM,SGW,PCM,TCM,RF_HUB,ORC,IC,ESC,ECM
 SG_ VC_AnlgDrSnsr : 2|2@1+ (1,0) [0|0] "" SGW,RF_HUB
 SG_ VC_BrkTyp : 4|3@1+ (1,0) [0|0] "" SGW,TCM,RF_HUB
 SG_ VC_AQS_Prsnt : 7|1@1+ (1,0) [0|0] "" SGW,RF_HUB
 SG_ VC_Strng_Rt_Mns1 : 8|8@1+ (0.1,0) [0|25.4] "" SGW,RF_HUB,ESC
 SG_ VC_Strng_Rt_Mns2 : 16|8@1+ (0.1,0) [0|25.4] "" SGW,RF_HUB,ESC
 SG_ VC_Strng_Rt_Mns3 : 24|8@1+ (0.1,0) [0|25.4] "" SGW,RF_HUB,ESC
 SG_ VC_Strng_Rt_Mns4 : 32|8@1+ (0.1,0) [0|25.4] "" SGW,RF_HUB,ESC
 SG_ VC_Strng_Rt_Mns5 : 40|8@1+ (0.1,0) [0|25.4] "" SGW,RF_HUB,ESC
 SG_ VC_TireCircumfFT : 55|16@0+ (1,0) [0|65534] "mm" SGW,TCM,RF_HUB,ORC,ESC

BO_ 1101 VehCfgBu6: 8 RF_HUB
 SG_ VC_BU_VehCfg6_Stat : 0|2@1+ (1,0) [0|0] "" SGW,CBC
 SG_ VC_BU_AnlgDrSnsr : 2|2@1+ (1,0) [0|0] "" SGW,CBC
 SG_ VC_BU_BrkTyp : 4|3@1+ (1,0) [0|0] "" SGW,CBC
 SG_ VC_BU_AQS_Prsnt : 7|1@1+ (1,0) [0|0] "" SGW,CBC
 SG_ VC_BU_Strng_Rt_Mns1 : 8|8@1+ (0.1,0) [0|25.4] "" SGW,CBC
 SG_ VC_BU_Strng_Rt_Mns2 : 16|8@1+ (0.1,0) [0|25.4] "" SGW,CBC
 SG_ VC_BU_Strng_Rt_Mns3 : 24|8@1+ (0.1,0) [0|25.4] "" SGW,CBC
 SG_ VC_BU_Strng_Rt_Mns4 : 32|8@1+ (0.1,0) [0|25.4] "" SGW,CBC
 SG_ VC_BU_Strng_Rt_Mns5 : 40|8@1+ (0.1,0) [0|25.4] "" SGW,CBC
 SG_ VC_BU_TireCircumfFT : 55|16@0+ (1,0) [0|65534] "mm" SGW,CBC

BO_ 1216 D_RS_RF_HUB: 8 RF_HUB
 SG_ D_RS_RF_HUB : 7|64@0+ (1,0) [0|0] "" FTM,SGW,ETM,DIAGNOST

BO_ 1218 D_RS_IC: 8 IC
 SG_ D_RS_IC : 7|64@0+ (1,0) [0|0] "" FTM,SGW,ETM,DIAGNOST

BO_ 1220 D_RS_ORC: 8 ORC
 SG_ D_RS_ORC : 7|64@0+ (1,0) [0|0] "" FTM,SGW,ETM,DIAGNOST

BO_ 1223 D_RS_ESC: 8 ESC
 SG_ D_RS_ESC : 7|64@0+ (1,0) [0|0] "" FTM,SGW,ETM,DIAGNOST

BO_ 1225 D_RS_ESM: 8 ESM
 SG_ D_RS_ESM : 7|64@0+ (1,0) [0|0] "" FTM,SGW,ETM,DIAGNOST

BO_ 1235 D_RS_DASM: 8 IRCM
 SG_ D_RS_DASM : 7|64@0+ (1,0) [0|0] "" FTM,SGW,ETM,DIAGNOST

BO_ 1250 D_RS_PTS: 8 PTS
 SG_ D_RS_PTS : 7|64@0+ (1,0) [0|0] "" FTM,SGW,ETM

BO_ 1251 D_RS_SCCM: 8 SCCM
 SG_ D_RS_SCCM : 7|64@0+ (1,0) [0|0] "" FTM,SGW,ETM,DIAGNOST

BO_ 1284 D_RS_CBC: 8 CBC
 SG_ D_RS_CBC : 7|64@0+ (1,0) [0|0] "" FTM,SGW,ETM,DIAGNOST

BO_ 1408 ECU_APPL_RF_HUB: 8 RF_HUB
 SG_ ECU_APPL_RF_HUB : 7|64@0+ (1,0) [0|0] "" SGW,DIAGNOST

BO_ 1409 ECU_APPL_CBC: 8 CBC
 SG_ ECU_APPL_CBC : 7|64@0+ (1,0) [0|0] "" SGW,DIAGNOST

BO_ 1410 ECU_APPL_IC: 8 IC
 SG_ ECU_APPL_IC : 7|64@0+ (1,0) [0|0] "" SGW,DIAGNOST

BO_ 1412 ECU_APPL_ORC: 8 ORC
 SG_ ECU_APPL_ORC : 7|64@0+ (1,0) [0|0] "" SGW,DIAGNOST

BO_ 1415 ECU_APPL_ESC: 8 ESC
 SG_ ECU_APPL_ESC : 7|64@0+ (1,0) [0|0] "" SGW,DIAGNOST

BO_ 1417 ECU_APPL_ESM: 8 ESM
 SG_ ECU_APPL_ESM : 7|64@0+ (1,0) [0|0] "" SGW,DIAGNOST

BO_ 1427 ECU_APPL_DASM: 8 IRCM
 SG_ ECU_APPL_DASM : 7|64@0+ (1,0) [0|0] "" SGW,DIAGNOST

BO_ 1442 ECU_APPL_PTS: 8 PTS
 SG_ ECU_APPL_PTS : 7|64@0+ (1,0) [0|0] "" SGW,DIAGNOST

BO_ 1443 ECU_APPL_SCCM: 8 SCCM
 SG_ ECU_APPL_SCCM : 7|64@0+ (1,0) [0|0] "" SGW,DIAGNOST

BO_ 1464 ECU_APPL_ECM: 8 ECM
 SG_ ECU_APPL_ECM : 7|64@0+ (1,0) [0|0] "" SGW,DIAGNOST

BO_ 1465 ECU_APPL_TCM: 8 TCM
 SG_ ECU_APPL_TCM : 7|64@0+ (1,0) [0|0] "" SGW,DIAGNOST

BO_ 1536 SD_RS_RF_HUB: 8 RF_HUB
 SG_ SD_RS_RF_HUB : 7|64@0+ (1,0) [0|0] "" FTM,SGW,ETM,DIAGNOST

BO_ 1537 SD_RS_CBC: 8 CBC
 SG_ SD_RS_CBC : 7|64@0+ (1,0) [0|0] "" FTM,SGW,ETM,DIAGNOST

BO_ 1538 SD_RS_IC: 8 IC
 SG_ SD_RS_IC : 7|64@0+ (1,0) [0|0] "" FTM,SGW,ETM,DIAGNOST

BO_ 1540 SD_RS_ORC: 8 ORC
 SG_ SD_RS_ORC : 7|64@0+ (1,0) [0|0] "" FTM,SGW,ETM,DIAGNOST

BO_ 1543 SD_RS_ESC: 8 ESC
 SG_ SD_RS_ESC : 7|64@0+ (1,0) [0|0] "" FTM,SGW,ETM,DIAGNOST

BO_ 1545 SD_RS_ESM: 8 ESM
 SG_ SD_RS_ESM : 7|64@0+ (1,0) [0|0] "" FTM,SGW,ETM,DIAGNOST

BO_ 1555 SD_RS_DASM: 8 IRCM
 SG_ SD_RS_DASM : 7|64@0+ (1,0) [0|0] "" FTM,SGW,ETM,DIAGNOST

BO_ 1568 D_RQ_CBC: 8 DIAGNOST
 SG_ D_RQ_CBC : 7|64@0+ (1,0) [0|0] "" CBC

BO_ 1570 SD_RS_PTS: 8 PTS
 SG_ SD_RS_PTS : 7|64@0+ (1,0) [0|0] "" FTM,SGW,ETM,DIAGNOST

BO_ 1571 SD_RS_SCCM: 8 SCCM
 SG_ SD_RS_SCCM : 7|64@0+ (1,0) [0|0] "" FTM,SGW,ETM,DIAGNOST

BO_ 1592 SD_RS_ECM: 8 ECM
 SG_ SD_RS_ECM : 7|64@0+ (1,0) [0|0] "" FTM,SGW,ETM,DIAGNOST

BO_ 1593 SD_RS_TCM: 8 TCM
 SG_ SD_RS_TCM : 7|64@0+ (1,0) [0|0] "" FTM,SGW,ETM,DIAGNOST

BO_ 1728 APPL_ECU_RF_HUB: 8 DIAGNOST
 SG_ APPL_ECU_RF_HUB : 7|64@0+ (1,0) [0|0] "" RF_HUB

BO_ 1729 APPL_ECU_CBC: 8 DIAGNOST
 SG_ APPL_ECU_CBC : 7|64@0+ (1,0) [0|0] "" CBC

BO_ 1730 APPL_ECU_IC: 8 DIAGNOST
 SG_ APPL_ECU_IC : 7|64@0+ (1,0) [0|0] "" IC

BO_ 1732 APPL_ECU_ORC: 8 DIAGNOST
 SG_ APPL_ECU_ORC : 7|64@0+ (1,0) [0|0] "" ORC

BO_ 1735 APPL_ECU_ESC: 8 DIAGNOST
 SG_ APPL_ECU_ESC : 7|64@0+ (1,0) [0|0] "" ESC

BO_ 1737 APPL_ECU_ESM: 8 DIAGNOST
 SG_ APPL_ECU_ESM : 7|64@0+ (1,0) [0|0] "" ESM

BO_ 1747 APPL_ECU_DASM: 8 DIAGNOST
 SG_ APPL_ECU_DASM : 7|64@0+ (1,0) [0|0] "" IRCM

BO_ 1762 APPL_ECU_PTS: 8 DIAGNOST
 SG_ APPL_ECU_PTS : 7|64@0+ (1,0) [0|0] "" PTS

BO_ 1763 APPL_ECU_SCCM: 8 DIAGNOST
 SG_ APPL_ECU_SCCM : 7|64@0+ (1,0) [0|0] "" SCCM

BO_ 1784 APPL_ECU_ECM: 8 DIAGNOST
 SG_ APPL_ECU_ECM : 7|64@0+ (1,0) [0|0] "" PCM,ECM

BO_ 1785 APPL_ECU_TCM: 8 DIAGNOST
 SG_ APPL_ECU_TCM : 7|64@0+ (1,0) [0|0] "" TCM

BO_ 1856 D_RQ_RF_HUB: 8 DIAGNOST
 SG_ D_RQ_RF_HUB : 7|64@0+ (1,0) [0|0] "" RF_HUB

BO_ 1858 D_RQ_IC: 8 DIAGNOST
 SG_ D_RQ_IC : 7|64@0+ (1,0) [0|0] "" IC

BO_ 1860 D_RQ_ORC: 8 DIAGNOST
 SG_ D_RQ_ORC : 7|64@0+ (1,0) [0|0] "" ORC

BO_ 1863 D_RQ_ESC: 8 DIAGNOST
 SG_ D_RQ_ESC : 7|64@0+ (1,0) [0|0] "" ESC

BO_ 1865 D_RQ_ESM: 8 DIAGNOST
 SG_ D_RQ_ESM : 7|64@0+ (1,0) [0|0] "" ESM

BO_ 1875 D_RQ_DASM: 8 DIAGNOST
 SG_ D_RQ_DASM : 7|64@0+ (1,0) [0|0] "" IRCM,DIAGNOST

BO_ 1890 D_RQ_PTS: 8 DIAGNOST
 SG_ D_RQ_PTS : 7|64@0+ (1,0) [0|0] "" PTS

BO_ 1891 D_RQ_SCCM: 8 DIAGNOST
 SG_ D_RQ_SCCM : 7|64@0+ (1,0) [0|0] "" SCCM

BO_ 2015 DG_RQ_GLOBAL: 8 DIAGNOST
 SG_ DG_RQ_GLOBAL : 7|64@0+ (1,0) [0|0] "" PCM,ECM

BO_ 2016 D_RQ_ECM: 8 DIAGNOST
 SG_ D_RQ_ECM : 7|64@0+ (1,0) [0|0] "" PCM,ECM

BO_ 2017 D_RQ_TCM: 8 DIAGNOST
 SG_ D_RQ_TCM : 7|64@0+ (1,0) [0|0] "" TCM

BO_ 2024 D_RS_ECM: 8 ECM
 SG_ D_RS_ECM : 7|64@0+ (1,0) [0|0] "" FTM,SGW,ETM,DIAGNOST

BO_ 2025 D_RS_TCM: 8 TCM
 SG_ D_RS_TCM : 7|64@0+ (1,0) [0|0] "" FTM,SGW,ETM,DIAGNOST

BO_ 362 DTCM_A2: 8 DTCM
 SG_ CRC_DTCM_A2 : 56|8@1+ (1,0) [0|0] "" SGW,PCM,ECM
 SG_ DrvLnMinTrqMd : 7|1@1+ (1,0) [0|0] "" SGW,PCM,ECM
 SG_ DrvLnTrqRq : 0|9@0+ (2,0) [0|1020] "Nm" SGW,PCM,ECM
 SG_ MC_DTCM_A2 : 52|4@1+ (1,0) [0|15] "" SGW,PCM,ECM

BO_ 640 MEM_D_POS: 1 CBC
 SG_ Mem_D_Pos_Rq : 0|2@1+ (1,0) [0|0] "" SGW,IC
 SG_ Mem_D_Rc_Rq : 2|1@1+ (1,0) [0|0] "" SGW,IC
 SG_ Mem_D_Sv_Rq : 3|1@1+ (1,0) [0|0] "" SGW,IC

BO_ 752 MSM_A1: 2 CBC
 SG_ MEM_RC_STAT : 3|3@1+ (1,0) [0|0] "" SGW,IC
 SG_ MSMD_PDL_LKOUT : 8|3@1+ (1,0) [0|0] "" SGW,IC
 SG_ EASY_EXIT : 1|2@1+ (1,0) [0|0] "" SGW,IC
 SG_ RKE_MEM : 0|1@1+ (1,0) [0|0] "" SGW,IC

BO_ 847 RFHUB_A4: 1 RF_HUB
 SG_ RF_FobNum : 1|4@1+ (1,0) [0|0] "" SGW,CBC
 SG_ RFMemRq : 0|1@1+ (1,0) [0|0] "" SGW,CBC

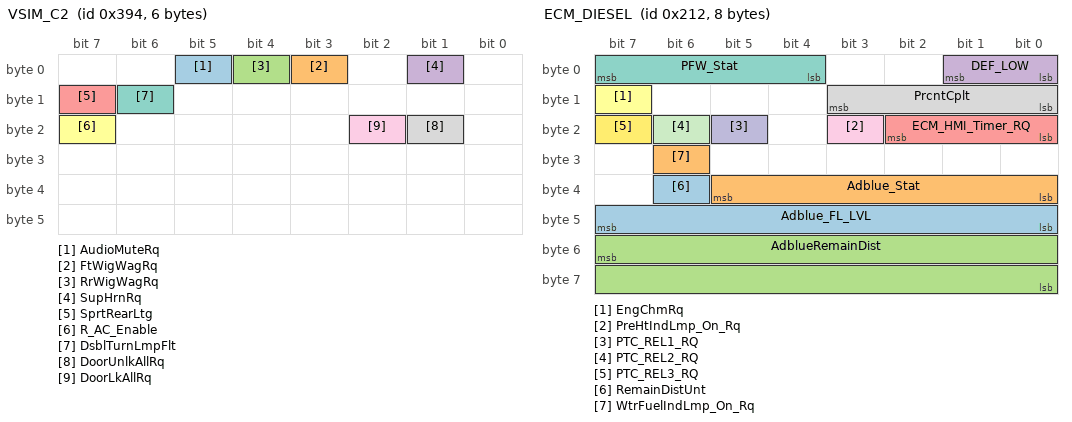
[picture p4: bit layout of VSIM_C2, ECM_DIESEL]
BO_ 916 VSIM_C2: 6 VSIM
 SG_ AudioMuteRq : 5|1@1+ (1,0) [0|0] "" SGW
 SG_ FtWigWagRq : 3|1@1+ (1,0) [0|0] "" SGW,CBC
 SG_ RrWigWagRq : 4|1@1+ (1,0) [0|0] "" SGW,CBC
 SG_ SupHrnRq : 1|1@1+ (1,0) [0|0] "" SGW,CBC
 SG_ SprtRearLtg : 15|1@1+ (1,0) [0|0] "" SGW
 SG_ R_AC_Enable : 23|1@1+ (1,0) [0|0] "" SGW,CBC
 SG_ DsblTurnLmpFlt : 14|1@1+ (1,0) [0|0] "" SGW
 SG_ DoorUnlkAllRq : 17|1@1+ (1,0) [0|0] "" SGW,CBC
 SG_ DoorLkAllRq : 18|1@1+ (1,0) [0|0] "" SGW,CBC

BO_ 1227 D_RS_DTCM: 8 DTCM
 SG_ D_RS_DTCM : 7|64@0+ (1,0) [0|0] "" FTM,SGW,ETM,DIAGNOST

BO_ 1265 D_RS_VSIM: 8 VSIM
 SG_ D_RS_VSIM : 7|64@0+ (1,0) [0|0] "" FTM,SGW,ETM,DIAGNOST

BO_ 1419 ECU_APPL_DTCM: 8 DTCM
 SG_ ECU_APPL_DTCM : 7|64@0+ (1,0) [0|0] "" SGW,DIAGNOST

BO_ 1457 ECU_APPL_VSIM: 8 VSIM
 SG_ ECU_APPL_VSIM : 7|64@0+ (1,0) [0|0] "" SGW,DIAGNOST

BO_ 1547 SD_RS_DTCM: 8 DTCM
 SG_ SD_RS_DTCM : 7|64@0+ (1,0) [0|0] "" FTM,SGW,ETM,DIAGNOST

BO_ 1585 SD_RS_VSIM: 8 VSIM
 SG_ SD_RS_VSIM : 7|64@0+ (1,0) [0|0] "" FTM,SGW,ETM,DIAGNOST

BO_ 1739 APPL_ECU_DTCM: 8 DIAGNOST
 SG_ APPL_ECU_DTCM : 7|64@0+ (1,0) [0|0] "" DTCM

BO_ 1777 APPL_ECU_VSIM: 8 DIAGNOST
 SG_ APPL_ECU_VSIM : 7|64@0+ (1,0) [0|0] "" VSIM

BO_ 1867 D_RQ_DTCM: 8 DIAGNOST
 SG_ D_RQ_DTCM : 7|64@0+ (1,0) [0|0] "" DTCM

BO_ 1905 D_RQ_VSIM: 8 DIAGNOST
 SG_ D_RQ_VSIM : 7|64@0+ (1,0) [0|0] "" VSIM

BO_ 806 AFLS_A1: 2 AFLS
 SG_ AFLS_ENBL : 0|1@1+ (1,0) [0|0] "" SGW,IC,CBC
 SG_ AFLS_Stat : 1|2@1+ (1,0) [0|0] "" SGW,IC

BO_ 1256 D_RS_AFLS: 8 AFLS
 SG_ D_RS_AFLS : 7|64@0+ (1,0) [0|0] "" FTM,SGW,ETM,DIAGNOST

BO_ 1448 ECU_APPL_AFLS: 8 AFLS
 SG_ ECU_APPL_AFLS : 7|64@0+ (1,0) [0|0] "" SGW,DIAGNOST

BO_ 1768 APPL_ECU_AFLS: 8 DIAGNOST
 SG_ APPL_ECU_AFLS : 7|64@0+ (1,0) [0|0] "" AFLS

BO_ 1896 D_RQ_AFLS: 8 DIAGNOST
 SG_ D_RQ_AFLS : 7|64@0+ (1,0) [0|0] "" AFLS

BO_ 530 ECM_DIESEL: 8 ECM
 SG_ Adblue_FL_LVL : 40|8@1+ (1,0) [0|100] "%" FTM,SGW,VSIM,IC,ETM
 SG_ Adblue_Stat : 32|6@1+ (1,0) [0|0] "" FTM,SGW,IC,ETM
 SG_ AdblueRemainDist : 55|16@0+ (1,0) [0|65534] "" SGW,IC
 SG_ DEF_LOW : 0|2@1+ (1,0) [0|0] "" FTM,SGW,IC
 SG_ ECM_HMI_Timer_RQ : 16|3@1+ (1,0) [0|0] "" SGW,IC
 SG_ EngChmRq : 15|1@1+ (1,0) [0|0] "" SGW,IC
 SG_ PFW_Stat : 4|4@1+ (1,0) [0|0] "" FTM,SGW,IC,ETM
 SG_ PrcntCplt : 8|4@1+ (10,0) [0|100] "%" FTM,SGW,IC
 SG_ PreHtIndLmp_On_Rq : 19|1@1+ (1,0) [0|0] "" FTM,SGW,IC,ETM
 SG_ PTC_REL1_RQ : 21|1@1+ (1,0) [0|0] "" SGW,CBC
 SG_ PTC_REL2_RQ : 22|1@1+ (1,0) [0|0] "" SGW,CBC
 SG_ PTC_REL3_RQ : 23|1@1+ (1,0) [0|0] "" SGW,CBC
 SG_ RemainDistUnt : 38|1@1+ (1,0) [0|0] "" SGW,IC
 SG_ WtrFuelIndLmp_On_Rq : 30|1@1+ (1,0) [0|0] "" FTM,SGW,IC,ETM

BO_ 625 DAS_A5: 8 IRCM
 SG_ DsrSpeed_KPH : 24|8@1+ (1,0) [0|250] "km/h" SGW,PCM,TCM
 SG_ FCWSetting : 3|2@1+ (1,0) [0|0] "" SGW,ORC,IC,CBC
 SG_ FCWState : 2|1@1+ (1,0) [0|0] "" SGW,ORC,IC,CBC

BO_ 671 PTS_StrCtrl: 8 PTS
 SG_ CRC_29Fh : 56|8@1+ (1,0) [0|0] "" SGW
 SG_ MC_29Fh : 52|4@1+ (1,0) [0|15] "" SGW

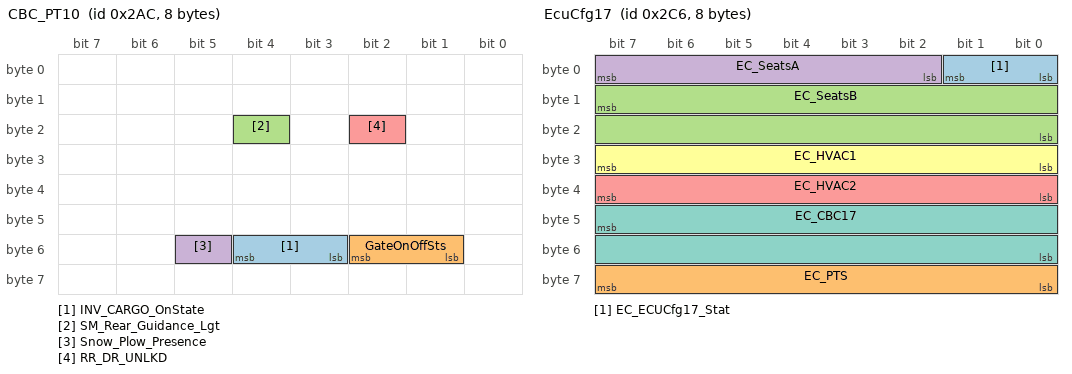
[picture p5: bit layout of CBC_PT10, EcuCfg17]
BO_ 684 CBC_PT10: 8 CBC
 SG_ INV_CARGO_OnState : 51|2@1+ (1,0) [0|0] "" SGW,IC
 SG_ GateOnOffSts : 49|2@1+ (1,0) [0|0] "" SGW
 SG_ SM_Rear_Guidance_Lgt : 20|1@1+ (1,0) [0|0] "" SGW,IC
 SG_ Snow_Plow_Presence : 53|1@1+ (1,0) [0|0] "" IRCM,SGW,PTS,IC
 SG_ RR_DR_UNLKD : 18|1@1+ (1,0) [0|0] "" SGW,VSIM

BO_ 705 GW_LIN_I_C5: 8 CBC
 SG_ VEH_INT_TEMP : 31|16@0+ (0.01,-40) [-40|85] "°C" SGW
 SG_ SwayBarBtnRq : 14|2@1+ (1,0) [0|0] "" SGW,FDCM

BO_ 709 EcuCfg16: 8 CBC
 SG_ EC_AudTel3B : 15|56@0+ (1,0) [0|0] "" SGW,RF_HUB
 SG_ EC_ECUCfg16_Stat : 0|2@1+ (1,0) [0|0] "" SGW,RF_HUB
 SG_ EC_AudTel3A : 2|6@1+ (1,0) [0|0] "" SGW,RF_HUB

BO_ 710 EcuCfg17: 8 CBC
 SG_ EC_ECUCfg17_Stat : 0|2@1+ (1,0) [0|0] "" SGW,RF_HUB,PTS
 SG_ EC_PTS : 56|8@1+ (1,0) [0|0] "" SGW,RF_HUB,PTS
 SG_ EC_SeatsB : 15|16@0+ (1,0) [0|0] "" SGW,RF_HUB
 SG_ EC_SeatsA : 2|6@1+ (1,0) [0|0] "" SGW,RF_HUB
 SG_ EC_HVAC2 : 32|8@1+ (1,0) [0|0] "" SGW,RF_HUB
 SG_ EC_HVAC1 : 24|8@1+ (1,0) [0|0] "" SGW,RF_HUB
 SG_ EC_CBC17 : 47|16@0+ (1,0) [0|0] "" SGW,RF_HUB

BO_ 714 EcuBuCfg16: 8 RF_HUB
 SG_ EC_BU_AudTel3B : 15|56@0+ (1,0) [0|0] "" SGW,CBC
 SG_ EC_BU_ECUCfg16_Stat : 0|2@1+ (1,0) [0|0] "" SGW,CBC
 SG_ EC_BU_AudTel3A : 2|6@1+ (1,0) [0|0] "" SGW,CBC

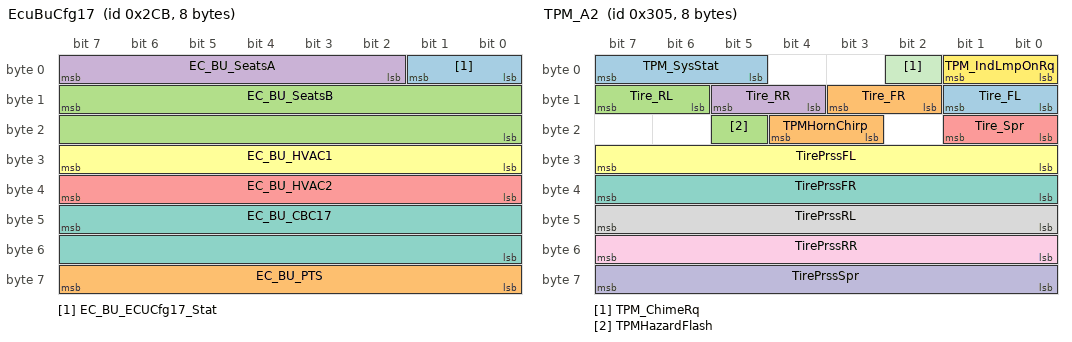
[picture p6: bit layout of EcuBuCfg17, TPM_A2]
BO_ 715 EcuBuCfg17: 8 RF_HUB
 SG_ EC_BU_ECUCfg17_Stat : 0|2@1+ (1,0) [0|0] "" SGW,CBC
 SG_ EC_BU_PTS : 56|8@1+ (1,0) [0|0] "" SGW,CBC
 SG_ EC_BU_SeatsB : 15|16@0+ (1,0) [0|0] "" SGW,CBC
 SG_ EC_BU_SeatsA : 2|6@1+ (1,0) [0|0] "" SGW,CBC
 SG_ EC_BU_HVAC2 : 32|8@1+ (1,0) [0|0] "" SGW,CBC
 SG_ EC_BU_HVAC1 : 24|8@1+ (1,0) [0|0] "" SGW,CBC
 SG_ EC_BU_CBC17 : 47|16@0+ (1,0) [0|0] "" SGW,CBC

BO_ 773 TPM_A2: 8 RF_HUB
 SG_ Tire_FL : 8|2@1+ (1,0) [0|0] "" FTM,SGW,ORC,IC,ETM
 SG_ Tire_FR : 10|2@1+ (1,0) [0|0] "" FTM,SGW,ORC,IC,ETM
 SG_ Tire_RL : 14|2@1+ (1,0) [0|0] "" FTM,SGW,ORC,IC,ETM
 SG_ Tire_RR : 12|2@1+ (1,0) [0|0] "" FTM,SGW,ORC,IC,ETM
 SG_ Tire_Spr : 16|2@1+ (1,0) [0|0] "" SGW,IC
 SG_ TirePrssFL : 24|8@1+ (1,0) [0|126] "psi" FTM,SGW,ORC,IC,ETM
 SG_ TirePrssFR : 32|8@1+ (1,0) [0|126] "psi" FTM,SGW,ORC,IC,ETM
 SG_ TirePrssRL : 40|8@1+ (1,0) [0|126] "psi" FTM,SGW,ORC,IC,ETM
 SG_ TirePrssRR : 48|8@1+ (1,0) [0|126] "psi" FTM,SGW,ORC,IC,ETM
 SG_ TirePrssSpr : 56|8@1+ (1,0) [0|126] "psi" SGW,IC,ETM
 SG_ TPM_ChimeRq : 2|1@1+ (1,0) [0|0] "" SGW,IC
 SG_ TPM_IndLmpOnRq : 0|2@1+ (1,0) [0|0] "" FTM,SGW,ORC,IC,ETM
 SG_ TPM_SysStat : 5|3@1+ (1,0) [0|0] "" SGW,IC
 SG_ TPMHornChirp : 19|2@1+ (1,0) [0|0] "" SGW,CBC
 SG_ TPMHazardFlash : 21|1@1+ (1,0) [0|0] "" SGW,IC,CBC

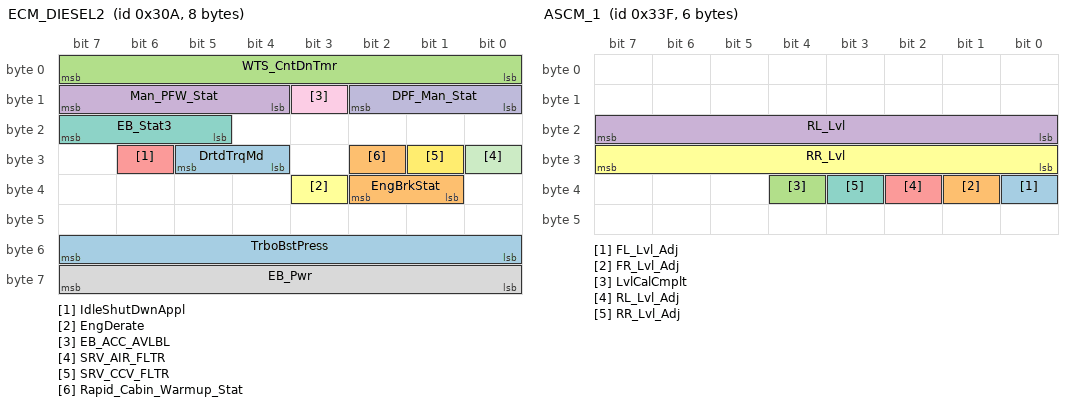
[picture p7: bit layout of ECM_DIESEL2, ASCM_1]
BO_ 778 ECM_DIESEL2: 8 ECM
 SG_ TrboBstPress : 48|8@1+ (1,0) [0|250] "kPaG" SGW,IC
 SG_ EngBrkStat : 33|2@1+ (1,0) [0|0] "" SGW,TCM
 SG_ WTS_CntDnTmr : 0|8@1+ (1,0) [0|254] "sec" SGW,IC
 SG_ Man_PFW_Stat : 12|4@1+ (1,0) [0|0] "" SGW,IC
 SG_ IdleShutDwnAppl : 30|1@1+ (1,0) [0|0] "" SGW,IC
 SG_ EngDerate : 35|1@1+ (1,0) [0|0] "" SGW,TCM
 SG_ EB_Stat3 : 21|3@1+ (1,0) [0|0] "" FTM,SGW,IC,CBC
 SG_ EB_Pwr : 56|8@1+ (1,0) [0|250] "kW" SGW,IC
 SG_ EB_ACC_AVLBL : 11|1@1+ (1,0) [0|0] "" IRCM,SGW
 SG_ DPF_Man_Stat : 8|3@1+ (1,0) [0|0] "" SGW,IC
 SG_ SRV_AIR_FLTR : 24|1@1+ (1,0) [0|0] "" SGW,IC
 SG_ SRV_CCV_FLTR : 25|1@1+ (1,0) [0|0] "" SGW,IC
 SG_ DrtdTrqMd : 28|2@1+ (1,0) [0|0] "" SGW,IC
 SG_ Rapid_Cabin_Warmup_Stat : 26|1@1+ (1,0) [0|0] "" SGW,IC

BO_ 831 ASCM_1: 6 ASCM
 SG_ FL_Lvl_Adj : 32|1@1+ (1,0) [0|0] "" IRCM,SGW,CBC
 SG_ FR_Lvl_Adj : 33|1@1+ (1,0) [0|0] "" IRCM,SGW,CBC
 SG_ LvlCalCmplt : 36|1@1+ (1,0) [0|0] "" IRCM,SGW
 SG_ RL_Lvl : 16|8@1+ (1,-100) [-100|153] "mm" IRCM,SGW,IC,CBC
 SG_ RL_Lvl_Adj : 34|1@1+ (1,0) [0|0] "" IRCM,SGW
 SG_ RR_Lvl : 24|8@1+ (1,-100) [-100|153] "mm" IRCM,SGW,IC,CBC
 SG_ RR_Lvl_Adj : 35|1@1+ (1,0) [0|0] "" IRCM,SGW

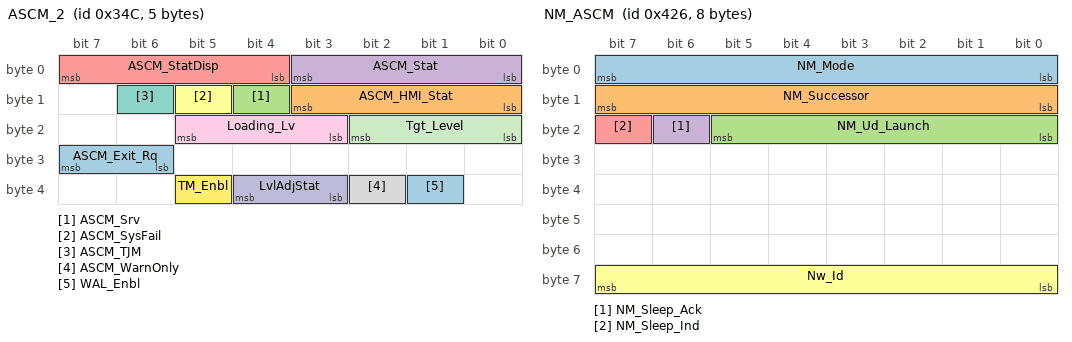
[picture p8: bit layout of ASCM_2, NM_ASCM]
BO_ 844 ASCM_2: 5 ASCM
 SG_ ASCM_Exit_Rq : 30|2@1+ (1,0) [0|0] "" SGW,IC,CBC
 SG_ ASCM_HMI_Stat : 8|4@1+ (1,0) [0|0] "" SGW,IC
 SG_ ASCM_Srv : 12|1@1+ (1,0) [0|0] "" SGW,ORC,IC,CBC
 SG_ ASCM_Stat : 0|4@1+ (1,0) [0|0] "" FTM,IRCM,SGW,ORC,IC,ESC,CBC
 SG_ ASCM_StatDisp : 4|4@1+ (1,0) [0|0] "" SGW,IC
 SG_ ASCM_SysFail : 13|1@1+ (1,0) [0|0] "" SGW,ORC,IC,CBC
 SG_ ASCM_TJM : 14|1@1+ (1,0) [0|0] "" SGW,IC,CBC
 SG_ ASCM_WarnOnly : 34|1@1+ (1,0) [0|0] "" SGW,IC,CBC
 SG_ Loading_Lv : 19|3@1+ (1,0) [0|0] "" SGW,IC,ESC
 SG_ LvlAdjStat : 35|2@1+ (1,0) [0|0] "" SGW,IC
 SG_ Tgt_Level : 16|3@1+ (1,0) [0|0] "" SGW,IC
 SG_ TM_Enbl : 37|1@1+ (1,0) [0|0] "" SGW,IC,CBC
 SG_ WAL_Enbl : 33|1@1+ (1,0) [0|0] "" SGW,IC,CBC

BO_ 1062 NM_ASCM: 8 ASCM
 SG_ NM_Mode : 0|8@1+ (1,0) [0|0] "" TTPM,SGW,VSIM,SCCM,RF_HUB,IC,ESM,ESC,CBC,ASCM
 SG_ NM_Successor : 8|8@1+ (1,0) [0|63] "" TTPM,SGW,VSIM,SCCM,RF_HUB,IC,ESM,ESC,CBC,ASCM
 SG_ NM_Ud_Launch : 16|6@1+ (1,0) [0|0] "" TTPM,SGW,VSIM,SCCM,RF_HUB,IC,ESM,ESC,CBC,ASCM
 SG_ NM_Sleep_Ack : 22|1@1+ (1,0) [0|0] "" TTPM,SGW,VSIM,SCCM,RF_HUB,IC,ESM,ESC,CBC,ASCM
 SG_ NM_Sleep_Ind : 23|1@1+ (1,0) [0|0] "" TTPM,SGW,VSIM,SCCM,RF_HUB,IC,ESM,ESC,CBC,ASCM
 SG_ N : NaN|NaN@0+ (NaN,NaN) [NaN|NaN] "2" 4
 SG_ A : NaN|NaN@0+ (NaN,NaN) [NaN|NaN] "g" _
 SG_ W : NaN|NaN@0+ (NaN,NaN) [NaN|NaN] "_" A
 SG_ Nw_Id : 56|8@1+ (1,0) [0|0] "" TTPM,SGW,VSIM,SCCM,RF_HUB,IC,ESM,ESC,CBC,ASCM

BO_ 1254 D_RS_ASCM: 8 ASCM
 SG_ D_RS_ASCM : 7|64@0+ (1,0) [0|0] "" FTM,SGW,ETM,DIAGNOST

BO_ 1446 ECU_APPL_ASCM: 8 ASCM
 SG_ ECU_APPL_ASCM : 7|64@0+ (1,0) [0|0] "" SGW,DIAGNOST

BO_ 1574 SD_RS_ASCM: 8 ASCM
 SG_ SD_RS_ASCM : 7|64@0+ (1,0) [0|0] "" FTM,SGW,ETM,DIAGNOST

BO_ 1576 SD_RS_AFLS: 8 AFLS
 SG_ SD_RS_AFLS : 7|64@0+ (1,0) [0|0] "" FTM,SGW,ETM,DIAGNOST

BO_ 1766 APPL_ECU_ASCM: 8 DIAGNOST
 SG_ APPL_ECU_ASCM : 7|64@0+ (1,0) [0|0] "" ASCM

BO_ 1894 D_RQ_ASCM: 8 DIAGNOST
 SG_ D_RQ_ASCM : 7|64@0+ (1,0) [0|0] "" ASCM

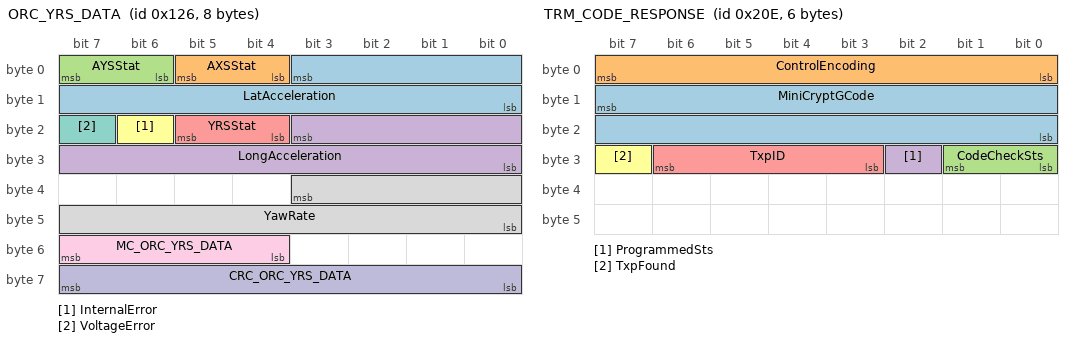
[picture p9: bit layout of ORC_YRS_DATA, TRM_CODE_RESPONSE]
BO_ 294 ORC_YRS_DATA: 8 ORC
 SG_ LatAcceleration : 3|12@0+ (0.02,-40.96) [-40.96|40.92] "m/s²" SGW,ETM,ESC
 SG_ AXSStat : 4|2@1+ (1,0) [0|0] "" SGW,ESC
 SG_ AYSStat : 6|2@1+ (1,0) [0|0] "" SGW,ESC
 SG_ LongAcceleration : 19|12@0+ (0.02,-40.96) [-40.96|40.92] "m/s²" SGW,ITBM,ETM,ESC
 SG_ YRSStat : 20|2@1+ (1,0) [0|0] "" SGW,ESC
 SG_ InternalError : 22|1@1+ (1,0) [0|0] "" SGW,ESC
 SG_ VoltageError : 23|1@1+ (1,0) [0|0] "" SGW,ESC
 SG_ YawRate : 35|12@0+ (0.08,-163.84) [-163.84|163.68] "°/s" SGW,ESC
 SG_ MC_ORC_YRS_DATA : 52|4@1+ (1,0) [0|15] "" SGW,ESC
 SG_ CRC_ORC_YRS_DATA : 56|8@1+ (1,0) [0|0] "" SGW,ESC

BO_ 516 IMMO_CODE_RESPONSE: 7 CBC
 SG_ ControlEncodingRsp : 0|8@1+ (1,0) [0|0] "" SGW,PCM,ECM
 SG_ MKKey1org21 : 8|8@1+ (1,0) [0|255] "" SGW,PCM,ECM
 SG_ MKKey2org22 : 16|8@1+ (1,0) [0|255] "" SGW,PCM,ECM
 SG_ MKKey_3 : 24|8@1+ (1,0) [0|255] "" SGW,PCM,ECM
 SG_ MKKey_4 : 32|8@1+ (1,0) [0|255] "" SGW,PCM,ECM
 SG_ MKKey_5 : 40|8@1+ (1,0) [0|255] "" SGW,PCM,ECM
 SG_ MKKey_6 : 48|8@1+ (1,0) [0|255] "" SGW,PCM,ECM

BO_ 517 IMMO_CODE_REQUEST: 7 ECM
 SG_ ControlEncodingRq : 0|8@1+ (1,0) [0|0] "" SGW,CBC
 SG_ rnd_1 : 8|8@1+ (1,0) [0|255] "" SGW,CBC
 SG_ rnd_2 : 16|8@1+ (1,0) [0|255] "" SGW,CBC
 SG_ rnd_3 : 24|8@1+ (1,0) [0|255] "" SGW,CBC
 SG_ rnd_4 : 32|8@1+ (1,0) [0|255] "" SGW,CBC
 SG_ f1_1 : 40|8@1+ (1,0) [0|255] "" SGW,CBC
 SG_ f1_2 : 48|8@1+ (1,0) [0|255] "" SGW,CBC

BO_ 524 BCM_CODE_TRM_REQUEST: 8 CBC
 SG_ ControlEncodingBCM : 0|8@1+ (1,0) [0|0] "" SGW,RF_HUB
 SG_ MiniCryptFCode : 15|16@0+ (1,0) [0|0] "" SGW,RF_HUB
 SG_ MiniCrypt_Rnd : 31|32@0+ (1,0) [0|0] "" SGW,RF_HUB
 SG_ TxpReadRequest : 62|1@1+ (1,0) [0|0] "" SGW,RF_HUB
 SG_ TxpAuthRequest : 63|1@1+ (1,0) [0|0] "" SGW,RF_HUB

BO_ 525 BCM_MINICRYPT_ACK: 1 CBC
 SG_ MinicryptReceptionSts : 7|1@1+ (1,0) [0|0] "" SGW,RF_HUB

BO_ 526 TRM_CODE_RESPONSE: 6 RF_HUB
 SG_ MiniCryptGCode : 15|16@0+ (1,0) [0|0] "" SGW,CBC
 SG_ ControlEncoding : 0|8@1+ (1,0) [0|0] "" SGW,CBC
 SG_ CodeCheckSts : 24|2@1+ (1,0) [0|0] "" SGW,CBC
 SG_ ProgrammedSts : 26|1@1+ (1,0) [0|0] "" SGW,CBC
 SG_ TxpID : 27|4@1+ (1,0) [0|0] "" SGW,CBC
 SG_ TxpFound : 31|1@1+ (1,0) [0|0] "" SGW,CBC

BO_ 527 TRM_MKP_KEY: 8 RF_HUB
 SG_ FrameNumber : 0|4@1+ (1,0) [0|0] "" SGW,CBC
 SG_ TotalFrameNumber : 4|4@1+ (1,0) [0|0] "" SGW,CBC
 SG_ DATA1 : 8|8@1+ (1,0) [0|0] "" SGW,CBC
 SG_ DATA2 : 16|8@1+ (1,0) [0|0] "" SGW,CBC
 SG_ DATA3 : 24|8@1+ (1,0) [0|0] "" SGW,CBC
 SG_ DATA4 : 32|8@1+ (1,0) [0|0] "" SGW,CBC
 SG_ DATA5 : 40|8@1+ (1,0) [0|0] "" SGW,CBC
 SG_ DATA6 : 48|8@1+ (1,0) [0|0] "" SGW,CBC
 SG_ DATA7 : 56|8@1+ (1,0) [0|0] "" SGW,CBC

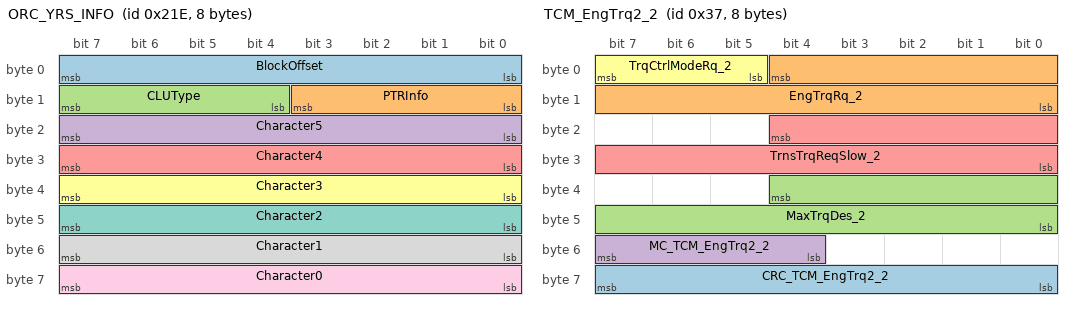
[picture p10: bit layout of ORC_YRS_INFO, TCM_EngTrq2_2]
BO_ 542 ORC_YRS_INFO: 8 ORC
 SG_ BlockOffset : 0|8@1+ (1,0) [0|0] "" SGW,ESC
 SG_ PTRInfo : 8|4@1+ (1,0) [0|0] "" SGW,ESC
 SG_ CLUType : 12|4@1+ (1,0) [0|0] "" SGW,ESC
 SG_ Character5 : 16|8@1+ (1,0) [0|0] "" SGW,ESC
 SG_ Character4 : 24|8@1+ (1,0) [0|0] "" SGW,ESC
 SG_ Character3 : 32|8@1+ (1,0) [0|0] "" SGW,ESC
 SG_ Character2 : 40|8@1+ (1,0) [0|0] "" SGW,ESC
 SG_ Character1 : 48|8@1+ (1,0) [0|0] "" SGW,ESC
 SG_ Character0 : 56|8@1+ (1,0) [0|0] "" SGW,ESC

BO_ 669 EPB_A1: 3 ESC
 SG_ MC_EPB_A1 : 12|4@1+ (1,0) [0|15] "" IRCM,SGW,PCM,TCM,PTS,ECM
 SG_ CRC_EPB_A1 : 16|8@1+ (1,0) [0|0] "" IRCM,SGW,PCM,TCM,PTS,ECM

BO_ 770 EPB_1: 8 ESC
 SG_ MC_EPB_1 : 52|4@1+ (1,0) [0|15] "" IRCM,SGW,IC
 SG_ CRC_EPB_1 : 56|8@1+ (1,0) [0|0] "" IRCM,SGW,IC

BO_ 782 IC_A5: 8 IC
 SG_ Gas_Range : 1|10@0+ (1,0) [0|1022] "km" FTM,SGW,ETM
 SG_ EngHour : 39|16@0+ (1,0) [0|65535] "Hours" SGW,VSIM
 SG_ CFG_Manual_DPF : 3|2@1+ (1,0) [0|0] "" SGW,ECM

BO_ 938 IC_TripData_1: 8 IC
 SG_ A_MPG : 1|10@0+ (0.1,0) [0|99.9] "MPG" FTM,SGW,ETM

BO_ 939 IC_TripData_2: 8 IC
 SG_ A_KMpL : 1|10@0+ (0.1,0) [0|99.9] "kmpl" FTM,SGW,ETM

BO_ 940 IC_TripData_3: 8 IC
 SG_ A_Total_Dist_Miles : 23|24@0+ (0.1,0) [0|9999.9] "Mile" FTM,SGW,ETM
 SG_ A_Total_Dist_Kilometers : 47|24@0+ (0.1,0) [0|16093.3] "km" FTM,SGW,ETM

BO_ 941 IC_TripData_4: 8 IC
 SG_ B_MPG : 1|10@0+ (0.1,0) [0|99.9] "MPG" FTM,SGW,ETM

BO_ 942 IC_TripData_5: 8 IC
 SG_ B_KMpL : 1|10@0+ (0.1,0) [0|99.9] "kmpl" FTM,SGW,ETM

BO_ 943 IC_TripData_6: 8 IC
 SG_ B_Total_Dist_Miles : 23|24@0+ (0.1,0) [0|9999.9] "Mile" FTM,SGW,ETM
 SG_ B_Total_Dist_Kilometers : 47|24@0+ (0.1,0) [0|16093.3] "km" FTM,SGW,ETM

BO_ 55 TCM_EngTrq2_2: 8 TCM
 SG_ CRC_TCM_EngTrq2_2 : 56|8@1+ (1,0) [0|0] "" SGW,ECM
 SG_ EngTrqRq_2 : 4|13@0+ (0.25,-500) [-500|1547.5] "Nm" SGW,ESC,ECM
 SG_ MaxTrqDes_2 : 36|13@0+ (0.25,-500) [-500|1547.5] "Nm" SGW,ECM
 SG_ MC_TCM_EngTrq2_2 : 52|4@1+ (1,0) [0|15] "" SGW,ECM
 SG_ TrnsTrqReqSlow_2 : 20|13@0+ (0.25,-500) [-500|1547.5] "Nm" FTM,SGW,ETM
 SG_ TrqCtrlModeRq_2 : 5|3@1+ (1,0) [0|0] "" SGW,ESC,ECM

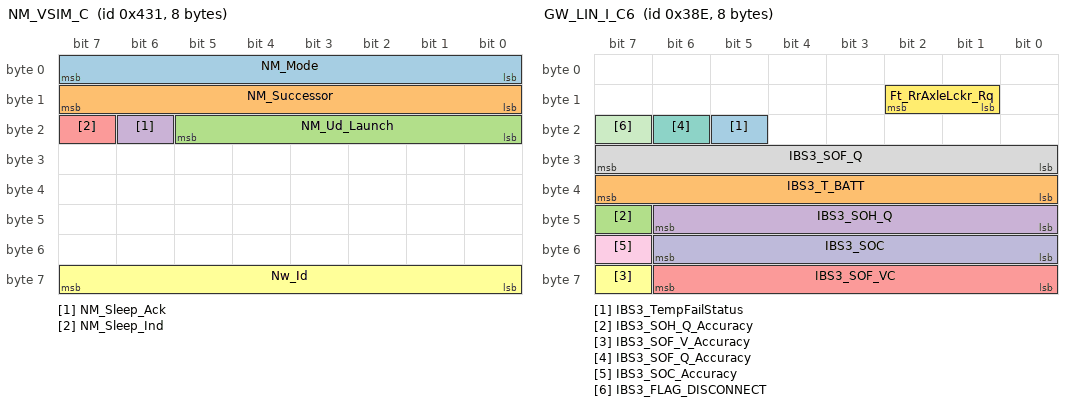
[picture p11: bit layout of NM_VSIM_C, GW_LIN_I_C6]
BO_ 1073 NM_VSIM_C: 8 VSIM
 SG_ NM_Mode : 0|8@1+ (1,0) [0|0] "" TTPM,SGW,VSIM,SCCM,RF_HUB,IC,ESM,ESC,CBC,ASCM
 SG_ NM_Successor : 8|8@1+ (1,0) [0|63] "" TTPM,SGW,VSIM,SCCM,RF_HUB,IC,ESM,ESC,CBC,ASCM
 SG_ NM_Ud_Launch : 16|6@1+ (1,0) [0|0] "" TTPM,SGW,VSIM,SCCM,RF_HUB,IC,ESM,ESC,CBC,ASCM
 SG_ NM_Sleep_Ack : 22|1@1+ (1,0) [0|0] "" TTPM,SGW,VSIM,SCCM,RF_HUB,IC,ESM,ESC,CBC,ASCM
 SG_ NM_Sleep_Ind : 23|1@1+ (1,0) [0|0] "" TTPM,SGW,VSIM,SCCM,RF_HUB,IC,ESM,ESC,CBC,ASCM
 SG_ N : NaN|NaN@0+ (NaN,NaN) [NaN|NaN] "2" 4
 SG_ A : NaN|NaN@0+ (NaN,NaN) [NaN|NaN] "g" _
 SG_ W : NaN|NaN@0+ (NaN,NaN) [NaN|NaN] "_" V
 SG_ Nw_Id : 56|8@1+ (1,0) [0|0] "" TTPM,SGW,VSIM,SCCM,RF_HUB,IC,ESM,ESC,CBC,ASCM

BO_ 973 IPC_LMPS: 8 IC
 SG_ WATER_IN_FUEL_STAT : 28|2@1+ (1,0) [0|0] "" SGW,CBC
 SG_ TIRE_PRESSURE_STAT : 12|2@1+ (1,0) [0|0] "" SGW,CBC
 SG_ STOP_START_STAT : 20|2@1+ (1,0) [0|0] "" SGW,CBC
 SG_ SERVICE_STAT : 34|2@1+ (1,0) [0|0] "" SGW,CBC
 SG_ SERVICE_ACC_STAT : 26|2@1+ (1,0) [0|0] "" SGW,CBC
 SG_ OVER_TEMP_STAT : 18|2@1+ (1,0) [0|0] "" SGW,CBC
 SG_ OIL_TEMP_STAT : 32|2@1+ (1,0) [0|0] "" SGW,CBC
 SG_ OIL_PRESSURE_STAT : 4|2@1+ (1,0) [0|0] "" SGW,CBC
 SG_ LANE_SENSE_STAT : 42|2@1+ (1,0) [0|0] "" SGW,CBC
 SG_ FOUR_WD_SERVICE_STAT : 40|2@1+ (1,0) [0|0] "" SGW,CBC
 SG_ FCW_SYSTEM_STAT : 24|2@1+ (1,0) [0|0] "" SGW,CBC
 SG_ ETC_CONTROL_STAT : 14|2@1+ (1,0) [0|0] "" SGW,CBC
 SG_ EPS_STAT : 22|2@1+ (1,0) [0|0] "" SGW,CBC
 SG_ EPB_WARN_STAT : 46|2@1+ (1,0) [0|0] "" SGW,CBC
 SG_ ENGINE_TEMP_STAT : 0|2@1+ (1,0) [0|0] "" SGW,CBC
 SG_ ENGINE_MIL_STAT : 10|2@1+ (1,0) [0|0] "" SGW,CBC
 SG_ ELEC_STAB_STAT : 16|2@1+ (1,0) [0|0] "" SGW,CBC
 SG_ DEF_STAT : 30|2@1+ (1,0) [0|0] "" SGW,CBC
 SG_ DAMPING_SYSTEM_STAT : 36|2@1+ (1,0) [0|0] "" SGW,CBC
 SG_ BRK_IND_STAT : 6|2@1+ (1,0) [0|0] "" SGW,CBC
 SG_ BRAKE_PAD_STAT : 38|2@1+ (1,0) [0|0] "" SGW,CBC
 SG_ BATTERY_CHARGE_STAT : 2|2@1+ (1,0) [0|0] "" SGW,CBC
 SG_ AWD_SERVICE_STAT : 44|2@1+ (1,0) [0|0] "" SGW,CBC
 SG_ ABS_IND_STAT : 8|2@1+ (1,0) [0|0] "" SGW,CBC
 SG_ WINDSHIELD_FLUID_STAT : 52|2@1+ (1,0) [0|0] "" SGW,CBC
 SG_ OIL_LEVEL_STAT : 56|2@1+ (1,0) [0|0] "" SGW,CBC
 SG_ FUEL_CAP_STAT : 50|2@1+ (1,0) [0|0] "" SGW,CBC
 SG_ COOLENT_LEVEL_STAT : 54|2@1+ (1,0) [0|0] "" SGW,CBC
 SG_ TORQUE_STAT : 60|2@1+ (1,0) [0|0] "" SGW,CBC
 SG_ ELECTRIC_WRENCH_STAT : 58|2@1+ (1,0) [0|0] "" SGW,CBC
 SG_ CATALYST_TEMP_STAT : 48|2@1+ (1,0) [0|0] "" SGW,CBC

BO_ 754 IC_A6: 8 IC
 SG_ Inst_Fuel_Econ : 49|10@0+ (0.05,0) [0|50] "kmpl" SGW,VSIM,CBC
 SG_ Avg_Fuel_Econ : 33|10@0+ (0.05,0) [0|50] "kmpl" SGW,CBC

BO_ 910 GW_LIN_I_C6: 8 CBC
 SG_ IBS3_TempFailStatus : 21|1@1+ (1,0) [0|0] "" SGW,PCM,ECM
 SG_ IBS3_T_BATT : 32|8@1+ (1,-40) [-40|105] "°C" FTM,SGW,PCM,ETM,ECM
 SG_ IBS3_SOH_Q_Accuracy : 47|1@1+ (1,0) [0|0] "" SGW
 SG_ IBS3_SOH_Q : 40|7@1+ (2,0) [0|252] "Ah" SGW
 SG_ IBS3_SOF_VC : 56|7@1+ (0.05,5) [5|11.3] "V" SGW
 SG_ IBS3_SOF_V_Accuracy : 63|1@1+ (1,0) [0|0] "" SGW
 SG_ IBS3_SOF_Q_Accuracy : 22|1@1+ (1,0) [0|0] "" SGW
 SG_ IBS3_SOF_Q : 24|8@1+ (1,0) [0|254] "Ah" SGW
 SG_ IBS3_SOC_Accuracy : 55|1@1+ (1,0) [0|0] "" SGW,ETM
 SG_ IBS3_SOC : 48|7@1+ (1,0) [0|100] "%" FTM,SGW,ORC,ETM
 SG_ IBS3_FLAG_DISCONNECT : 23|1@1+ (1,0) [0|0] "" SGW
 SG_ Ft_RrAxleLckr_Rq : 9|2@1+ (1,0) [0|0] "" SGW,FDCM

BO_ 579 GW_LIN_I_C4: 8 CBC
 SG_ AxleLckrOFF_SW : 6|2@1+ (1,0) [0|0] "" SGW,FDCM
 SG_ TGW_AUD_MD2_CAB_DR : 24|6@1+ (1,0) [0|0] "" SGW,IC
 SG_ Phone_Popup_setting_active : 55|1@1+ (1,0) [0|0] "" SGW,IC

BO_ 1151 D_RS_SGW: 8 SGW
 SG_ D_RS_SGW : 7|64@0+ (1,0) [0|0] "" FTM,ETM,DIAGNOST

BO_ 1150 D_RQ_SGW: 8 DIAGNOST
 SG_ D_RQ_SGW : 7|64@0+ (1,0) [0|0] "" SGW

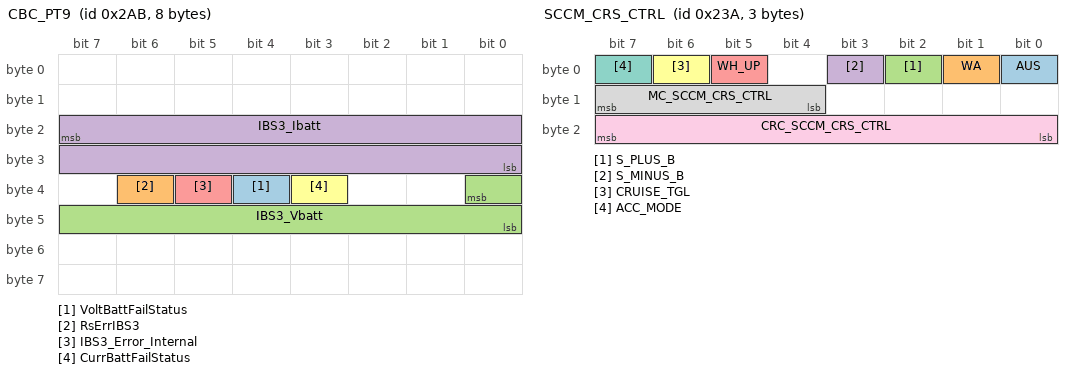
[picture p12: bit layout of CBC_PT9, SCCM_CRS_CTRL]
BO_ 683 CBC_PT9: 8 CBC
 SG_ VoltBattFailStatus : 36|1@1+ (1,0) [0|0] "" SGW,PCM,ECM
 SG_ RsErrIBS3 : 38|1@1+ (1,0) [0|0] "" SGW
 SG_ IBS3_Vbatt : 32|9@0+ (0.025,5) [5|17.75] "V" FTM,SGW,PCM,ORC,ETM,ECM,ASCM
 SG_ IBS3_Ibatt : 23|16@0+ (0.02,-1000) [-1000|310.68] "A" FTM,SGW,ETM
 SG_ IBS3_Error_Internal : 37|1@1+ (1,0) [0|0] "" SGW
 SG_ CurrBattFailStatus : 35|1@1+ (1,0) [0|0] "" SGW

BO_ 685 CBC_CFG2: 8 CBC
 SG_ Cfg_Aux_PTO : 16|3@1+ (1,0) [0|0] "" SGW
 SG_ CBC_AUX4_Type : 3|1@1+ (1,0) [0|0] "" SGW,IC
 SG_ CBC_AUX4_PWRMD : 8|1@1+ (1,0) [0|0] "" SGW,IC
 SG_ CBC_AUX4_HLEnbl : 13|1@1+ (1,0) [0|0] "" SGW,IC
 SG_ CBC_AUX3_Type : 2|1@1+ (1,0) [0|0] "" SGW,IC
 SG_ CBC_AUX3_PWRMD : 7|1@1+ (1,0) [0|0] "" SGW,IC
 SG_ CBC_AUX3_HLEnbl : 12|1@1+ (1,0) [0|0] "" SGW,IC
 SG_ CBC_AUX2_Type : 1|1@1+ (1,0) [0|0] "" SGW,IC
 SG_ CBC_AUX2_PWRMD : 6|1@1+ (1,0) [0|0] "" SGW,IC
 SG_ CBC_AUX2_HLEnbl : 11|1@1+ (1,0) [0|0] "" SGW,IC
 SG_ CBC_AUX1_Type : 0|1@1+ (1,0) [0|0] "" SGW,IC
 SG_ CBC_AUX1_PWRMD : 5|1@1+ (1,0) [0|0] "" SGW,IC
 SG_ CBC_AUX1_HLEnbl : 10|1@1+ (1,0) [0|0] "" SGW,IC
 SG_ CBC_AUX5_Type : 4|1@1+ (1,0) [0|0] "" SGW,IC
 SG_ CBC_AUX5_PWRMD : 9|1@1+ (1,0) [0|0] "" SGW,IC
 SG_ CBC_AUX5_HLEnbl : 14|1@1+ (1,0) [0|0] "" SGW,IC
 SG_ CBC_AUX6_Type : 39|1@1+ (1,0) [0|0] "" SGW,IC
 SG_ CBC_AUX6_PWRMD : 23|1@1+ (1,0) [0|0] "" SGW,IC
 SG_ CBC_AUX6_HLEnbl : 38|1@1+ (1,0) [0|0] "" SGW,IC

BO_ 881 ASBS_1: 8 FDCM
 SG_ SwayBarEVICDisplay : 4|4@1+ (1,0) [0|0] "" SGW,IC
 SG_ SwayBar_Sts : 0|2@1+ (1,0) [0|0] "" SGW
 SG_ SwayBar_LEDRq : 8|2@1+ (1,0) [0|0] "" SGW,CBC

BO_ 739 ECM_CNG1: 8 ECM
 SG_ CNG_GaLvl : 0|8@1+ (1,0) [0|100] "%" SGW,ETM
 SG_ CNG_LO : 8|1@1+ (1,0) [0|0] "" SGW,ETM
 SG_ EngRunFuelTyp : 9|3@1+ (1,0) [0|0] "" SGW,ETM

BO_ 570 SCCM_CRS_CTRL: 3 SCCM
 SG_ AUS : 0|1@1+ (1,0) [0|0] "" IRCM,SGW,PCM,ESC,ECM
 SG_ WA : 1|1@1+ (1,0) [0|0] "" IRCM,SGW,PCM,ECM
 SG_ S_PLUS_B : 2|1@1+ (1,0) [0|0] "" IRCM,SGW,PCM,VSIM,ESC,ECM
 SG_ S_MINUS_B : 3|1@1+ (1,0) [0|0] "" IRCM,SGW,PCM,VSIM,ESC,ECM
 SG_ WH_UP : 5|1@1+ (1,0) [0|0] "" IRCM,SGW,PCM,ESC,ECM
 SG_ CRUISE_TGL : 6|1@1+ (1,0) [0|0] "" IRCM,SGW,PCM,VSIM,ESC,ECM
 SG_ ACC_MODE : 7|1@1+ (1,0) [0|0] "" IRCM,SGW,PCM,ESC,ECM
 SG_ MC_SCCM_CRS_CTRL : 12|4@1+ (1,0) [0|15] "" IRCM,SGW,PCM,ESC,ECM
 SG_ CRC_SCCM_CRS_CTRL : 16|8@1+ (1,0) [0|0] "" IRCM,SGW,PCM,ESC,ECM

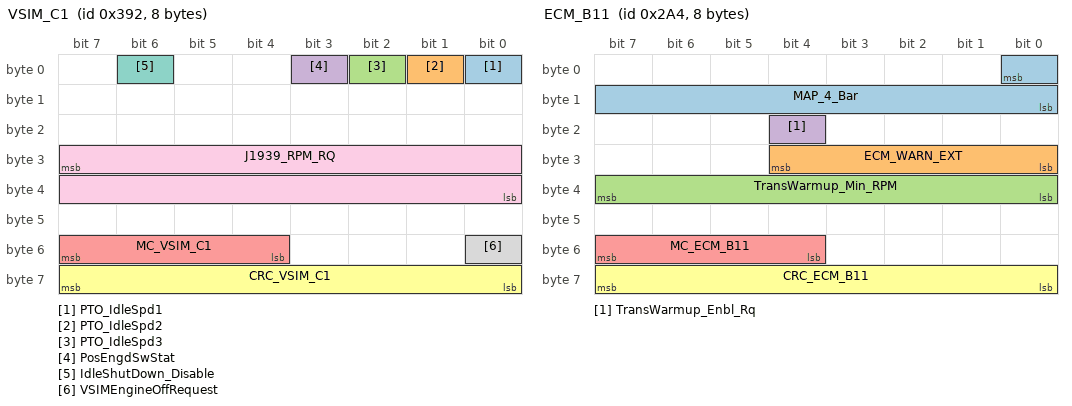
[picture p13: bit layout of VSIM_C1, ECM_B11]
BO_ 914 VSIM_C1: 8 VSIM
 SG_ PTO_IdleSpd1 : 0|1@1+ (1,0) [0|0] "" SGW,ECM
 SG_ PTO_IdleSpd2 : 1|1@1+ (1,0) [0|0] "" SGW,ECM
 SG_ PTO_IdleSpd3 : 2|1@1+ (1,0) [0|0] "" SGW,ECM
 SG_ PosEngdSwStat : 3|1@1+ (1,0) [0|0] "" SGW,TCM,ECM
 SG_ MC_VSIM_C1 : 52|4@1+ (1,0) [0|15] "" SGW,PCM,TCM,ECM
 SG_ CRC_VSIM_C1 : 56|8@1+ (1,0) [0|0] "" SGW,PCM,TCM,ECM
 SG_ IdleShutDown_Disable : 6|1@1+ (1,0) [0|0] "" SGW,ECM
 SG_ VSIMEngineOffRequest : 48|1@1+ (1,0) [0|0] "" SGW,RF_HUB
 SG_ J1939_RPM_RQ : 31|16@0+ (1,0) [0|0] "" SGW,ECM

BO_ 676 ECM_B11: 8 ECM
 SG_ MAP_4_Bar : 0|9@0+ (0.8,0) [0|408] "kPa" FTM,SGW,ORC,ETM
 SG_ ECM_WARN_EXT : 24|5@1+ (1,0) [0|0] "" SGW,IC
 SG_ TransWarmup_Min_RPM : 32|8@1+ (25,0) [0|6350] "rpm" SGW,TCM
 SG_ TransWarmup_Enbl_Rq : 20|1@1+ (1,0) [0|0] "" SGW,TCM
 SG_ MC_ECM_B11 : 52|4@1+ (1,0) [0|15] "" SGW,TCM
 SG_ CRC_ECM_B11 : 56|8@1+ (1,0) [0|0] "" SGW,TCM

BO_ 2047 WAKE_SGW: 1 SGW
 SG_ WAKE_SGW_Signal : 0|8@1+ (1,0) [0|0] "" Vector__XXX

BO_ 963 VehCfgCSM3_BU: 8 RF_HUB
 SG_ VC_BU_VehCfgCSO3_Stat : 0|2@1+ (1,0) [0|0] "" SGW,CBC
 SG_ VC_BU_TIRE_FILL_ALERT_CSO : 60|1@1+ (1,0) [0|0] "" SGW,CBC
 SG_ VC_BU_POWER_SIDE_STEP_CSO : 61|1@1+ (1,0) [0|0] "" SGW,CBC
 SG_ VC_BU_TRAILER_LENGTH_BLIND_SPOT_ : 62|1@1+ (1,0) [0|0] "" SGW,CBC
 SG_ VC_BU_TSI_CSO : 59|1@1+ (1,0) [0|0] "" SGW,CBC
 SG_ VC_BU_TRUNK_UNLOCK_ENABLE_CSO : 55|1@1+ (1,0) [0|0] "" SGW,CBC
 SG_ VC_BU_SPEED_THRESHOLD_CSO : 52|1@1+ (1,0) [0|0] "" SGW,CBC
 SG_ VC_BU_SEIU_RPM_CSO : 6|1@1+ (1,0) [0|0] "" SGW,CBC
 SG_ VC_BU_SEIU_INPUT_WIRE_CSO : 5|1@1+ (1,0) [0|0] "" SGW,CBC
 SG_ VC_BU_RVC_CVPM_SGRID_CSO : 50|1@1+ (1,0) [0|0] "" SGW,CBC
 SG_ VC_BU_RVC_CVPM_DGRID_CSO : 49|1@1+ (1,0) [0|0] "" SGW,CBC
 SG_ VC_BU_RR_CARGO_GUIDE_LGT_CSO : 3|1@1+ (1,0) [0|0] "" SGW,CBC
 SG_ VC_BU_PEB_CSO : 51|1@1+ (1,0) [0|0] "" SGW,CBC
 SG_ VC_BU_LKA_WARNING_CSO : 56|1@1+ (1,0) [0|0] "" SGW,CBC
 SG_ VC_BU_LKA_STRN_CSO : 58|1@1+ (1,0) [0|0] "" SGW,CBC
 SG_ VC_BU_LKA_SENS_CSO : 57|1@1+ (1,0) [0|0] "" SGW,CBC
 SG_ VC_BU_FFC_GRIDLINES_CSO : 48|1@1+ (1,0) [0|0] "" SGW,CBC
 SG_ VC_BU_EXTERNAL_LIGHT_SENSOR_CSO : 53|1@1+ (1,0) [0|0] "" SGW,CBC
 SG_ VC_BU_BUZZER_VOLUME_LEVEL_CSO : 54|1@1+ (1,0) [0|0] "" SGW,CBC
 SG_ VC_BU_BACKUP_ALARM_CSO : 2|1@1+ (1,0) [0|0] "" SGW,CBC
 SG_ VC_BU_AUTO_STOP_START_CSO : 63|1@1+ (1,0) [0|0] "" SGW,CBC
 SG_ VC_BU_AL_OR_PLUS_CSO : 41|1@1+ (1,0) [0|0] "" SGW,CBC
 SG_ VC_BU_AL_FFC_OR_PLUS_CSO : 40|1@1+ (1,0) [0|0] "" SGW,CBC
 SG_ VC_BU_TSR_WARNING_MODE_CSO : 42|1@1+ (1,0) [0|0] "" SGW,CBC
 SG_ VC_BU_RR_PK_LOOSE_SHIP_CSO : 9|1@1+ (1,0) [0|0] "" SGW,CBC
 SG_ VC_BU_HWRSS_CSO : 4|1@1+ (1,0) [0|0] "" SGW,CBC
 SG_ VC_BU_FT_PK_LOOSE_SHIP_CSO : 8|1@1+ (1,0) [0|0] "" SGW,CBC
 SG_ VC_BU_CHMSL_DYN_CNTR_CSO : 7|1@1+ (1,0) [0|0] "" SGW,CBC
 SG_ VC_BU_TSR_WARNING_MODE_OFFSET_CS : 43|1@1+ (1,0) [0|0] "" SGW,CBC

BO_ 962 VehCfgCSM3: 8 CBC
 SG_ VC_VehCfgCSO3_Stat : 0|2@1+ (1,0) [0|0] "" SGW,RF_HUB,IC
 SG_ VC_TRAILER_LENGTH_BLIND_SPOT_CSO : 62|1@1+ (1,0) [0|0] "" SGW,RF_HUB
 SG_ VC_TIRE_FILL_ALERT_CSO : 60|1@1+ (1,0) [0|0] "" SGW,RF_HUB
 SG_ VC_POWER_SIDE_STEP_CSO : 61|1@1+ (1,0) [0|0] "" SGW,RF_HUB
 SG_ VC_TSI_CSO : 59|1@1+ (1,0) [0|0] "" SGW,RF_HUB
 SG_ VC_TRUNK_UNLOCK_ENABLE_CSO : 55|1@1+ (1,0) [0|0] "" SGW,RF_HUB
 SG_ VC_SPEED_THRESHOLD_CSO : 52|1@1+ (1,0) [0|0] "" SGW,RF_HUB
 SG_ VC_SEIU_RPM_CSO : 6|1@1+ (1,0) [0|0] "" SGW,RF_HUB,IC
 SG_ VC_SEIU_INPUT_WIRE_CSO : 5|1@1+ (1,0) [0|0] "" SGW,RF_HUB,IC
 SG_ VC_RVC_CVPM_SGRID_CSO : 50|1@1+ (1,0) [0|0] "" SGW,RF_HUB
 SG_ VC_RVC_CVPM_DGRID_CSO : 49|1@1+ (1,0) [0|0] "" SGW,RF_HUB
 SG_ VC_RR_CARGO_GUIDE_LGT_CSO : 3|1@1+ (1,0) [0|0] "" SGW,RF_HUB,IC
 SG_ VC_PEB_CSO : 51|1@1+ (1,0) [0|0] "" SGW,RF_HUB
 SG_ VC_LKA_WARNING_CSO : 56|1@1+ (1,0) [0|0] "" SGW,RF_HUB
 SG_ VC_LKA_STRN_CSO : 58|1@1+ (1,0) [0|0] "" SGW,RF_HUB
 SG_ VC_LKA_SENS_CSO : 57|1@1+ (1,0) [0|0] "" SGW,RF_HUB
 SG_ VC_FFC_GRIDLINES_CSO : 48|1@1+ (1,0) [0|0] "" SGW,RF_HUB
 SG_ VC_EXTERNAL_LIGHT_SENSOR_CSO : 53|1@1+ (1,0) [0|0] "" SGW,RF_HUB
 SG_ VC_BUZZER_VOLUME_LEVEL_CSO : 54|1@1+ (1,0) [0|0] "" SGW,RF_HUB
 SG_ VC_BACKUP_ALARM_CSO : 2|1@1+ (1,0) [0|0] "" SGW,RF_HUB,IC
 SG_ VC_AUTO_STOP_START_CSO : 63|1@1+ (1,0) [0|0] "" SGW,RF_HUB
 SG_ VC_AL_OR_PLUS_CSO : 41|1@1+ (1,0) [0|0] "" SGW,RF_HUB
 SG_ VC_AL_FFC_OR_PLUS_CSO : 40|1@1+ (1,0) [0|0] "" SGW,RF_HUB
 SG_ VC_TSR_WARNING_MODE_OFFSET_CSO : 43|1@1+ (1,0) [0|0] "" SGW,RF_HUB
 SG_ VC_TSR_WARNING_MODE_CSO : 42|1@1+ (1,0) [0|0] "" SGW,RF_HUB
 SG_ VC_RR_PK_LOOSE_SHIP_CSO : 9|1@1+ (1,0) [0|0] "" SGW,RF_HUB
 SG_ VC_HWRSS_CSO : 4|1@1+ (1,0) [0|0] "" SGW,RF_HUB,IC
 SG_ VC_FT_PK_LOOSE_SHIP_CSO : 8|1@1+ (1,0) [0|0] "" SGW,RF_HUB
 SG_ VC_CHMSL_DYN_CNTR_CSO : 7|1@1+ (1,0) [0|0] "" SGW,RF_HUB

BO_ 907 VehCfgBu8: 8 RF_HUB
 SG_ VC_BU_VehCfg8_Stat : 0|2@1+ (1,0) [0|0] "" SGW,CBC
 SG_ VC_BU_Steering_Cfactor : 2|2@1+ (1,0) [0|0] "" SGW,CBC
 SG_ VC_BU_Trans_Brake_PRSNT : 8|1@1+ (1,0) [0|0] "" SGW,CBC
 SG_ VC_BU_LineLock_PRSNT : 4|1@1+ (1,0) [0|0] "" SGW,CBC
 SG_ VC_BU_HighOctane_PRSNT : 7|1@1+ (1,0) [0|0] "" SGW,CBC
 SG_ VC_BU_CHILLER_PRSNT : 6|1@1+ (1,0) [0|0] "" SGW,CBC
 SG_ VC_BU_ARC_PRSNT : 5|1@1+ (1,0) [0|0] "" SGW,CBC
 SG_ VC_BU_Speedometer_Tolerance : 9|4@1+ (1,0) [0|0] "" SGW,CBC
 SG_ VC_BU_Increasing_Speed_Constant : 13|3@1+ (1,0) [0|0] "" SGW,CBC
 SG_ VC_BU_WHL_BASE_LENGTH : 56|4@1+ (1,0) [0|0] "" SGW,CBC
 SG_ VC_BU_OHC_TYPE : 60|2@1+ (1,0) [0|0] "" SGW,CBC
 SG_ VC_BU_SBL_FBL_CORNERING_PRSNT : 17|2@1+ (1,0) [0|0] "" SGW,CBC
 SG_ VC_BU_PPPAHardBtn : 24|1@1+ (1,0) [0|0] "" SGW,CBC
 SG_ VC_BU_PEB_PRSNT : 62|1@1+ (1,0) [0|0] "" SGW,CBC
 SG_ VC_BU_OFFroad_Camera : 23|1@1+ (1,0) [0|0] "" SGW,CBC
 SG_ VC_BU_OFFRoadModePrsnt : 22|1@1+ (1,0) [0|0] "" SGW,CBC
 SG_ VC_BU_DBL_PRSNT : 20|1@1+ (1,0) [0|0] "" SGW,CBC
 SG_ VC_BU_BEAM_SHAPING_PRSNT : 19|1@1+ (1,0) [0|0] "" SGW,CBC
 SG_ VC_BU_AVAC_PRSNT : 21|1@1+ (1,0) [0|0] "" SGW,CBC
 SG_ VC_BU_OvertakingBan : 16|1@1+ (1,0) [0|0] "" SGW,CBC
 SG_ VC_BU_TrailerTPM_Prsnt : 52|1@1+ (1,0) [0|0] "" SGW,CBC
 SG_ VC_BU_TFA_Prsnt : 51|1@1+ (1,0) [0|0] "" SGW,CBC
 SG_ VC_BU_TACHO_TYPE : 54|2@1+ (1,0) [0|0] "" SGW,CBC
 SG_ VC_BU_STFA_Prsnt : 53|1@1+ (1,0) [0|0] "" SGW,CBC
 SG_ VC_BU_MARKET_HEADLAMP : 49|2@1+ (1,0) [0|0] "" SGW,CBC
 SG_ VC_BU_Dgtl_CHMSL_Cam_Prsnt : 25|1@1+ (1,0) [0|0] "" SGW,CBC
 SG_ VC_BU_WRSS_Prsnt : 29|1@1+ (1,0) [0|0] "" SGW,CBC
 SG_ VC_BU_Trlr_Rev_Guidance_Prsnt : 48|1@1+ (1,0) [0|0] "" SGW,CBC
 SG_ VC_BU_Box_Delete : 30|1@1+ (1,0) [0|0] "" SGW,CBC
 SG_ VC_BU_Aux_Trailer_Cam_Prsnt : 40|1@1+ (1,0) [0|0] "" SGW,CBC

BO_ 906 VehCfg8: 8 CBC
 SG_ VC_VehCfg8_Stat : 0|2@1+ (1,0) [0|0] "" ATMM,IRCM,SGW,PCM,RF_HUB,PTS,IC,ESC,ECM,AFLS
 SG_ VC_Steering_Cfactor : 2|2@1+ (1,0) [0|0] "" IRCM,SGW,RF_HUB,AFLS
 SG_ VC_Trans_Brake_PRSNT : 8|1@1+ (1,0) [0|0] "" SGW,RF_HUB
 SG_ VC_LineLock_PRSNT : 4|1@1+ (1,0) [0|0] "" SGW,RF_HUB
 SG_ VC_HighOctane_PRSNT : 7|1@1+ (1,0) [0|0] "" SGW,RF_HUB
 SG_ VC_CHILLER_PRSNT : 6|1@1+ (1,0) [0|0] "" SGW,RF_HUB
 SG_ VC_ARC_PRSNT : 5|1@1+ (1,0) [0|0] "" SGW,RF_HUB
 SG_ VC_Speedometer_Tolerance : 9|4@1+ (1,0) [0|0] "" IRCM,SGW,PCM,RF_HUB,IC,ECM
 SG_ VC_Increasing_Speed_Constant : 13|3@1+ (1,0) [0|0] "" IRCM,SGW,PCM,RF_HUB,IC,ECM
 SG_ VC_WHL_BASE_LENGTH : 56|4@1+ (1,0) [0|0] "" ATMM,IRCM,SGW,RF_HUB,PTS,AFLS
 SG_ VC_OHC_TYPE : 60|2@1+ (1,0) [0|0] "" SGW,RF_HUB
 SG_ VC_SBL_FBL_CORNERING_PRSNT : 17|2@1+ (1,0) [0|0] "" SGW,RF_HUB
 SG_ VC_PPPAHardBtn : 24|1@1+ (1,0) [0|0] "" SGW,RF_HUB
 SG_ VC_PEB_PRSNT : 62|1@1+ (1,0) [0|0] "" SGW,RF_HUB
 SG_ VC_OvertakingBan : 16|1@1+ (1,0) [0|0] "" SGW,RF_HUB
 SG_ VC_OFFroad_Camera : 23|1@1+ (1,0) [0|0] "" SGW,RF_HUB
 SG_ VC_OFFRoadModePrsnt : 22|1@1+ (1,0) [0|0] "" SGW,RF_HUB
 SG_ VC_DBL_PRSNT : 20|1@1+ (1,0) [0|0] "" SGW,RF_HUB
 SG_ VC_BEAM_SHAPING_PRSNT : 19|1@1+ (1,0) [0|0] "" SGW,RF_HUB
 SG_ VC_AVAC_PRSNT : 21|1@1+ (1,0) [0|0] "" SGW,RF_HUB
 SG_ VC_TrailerTPM_Prsnt : 52|1@1+ (1,0) [0|0] "" SGW,RF_HUB,IC
 SG_ VC_TFA_Prsnt : 51|1@1+ (1,0) [0|0] "" SGW,RF_HUB
 SG_ VC_TACHO_TYPE : 54|2@1+ (1,0) [0|0] "" SGW,PCM,RF_HUB,IC,ECM
 SG_ VC_STFA_Prsnt : 53|1@1+ (1,0) [0|0] "" SGW,RF_HUB
 SG_ VC_MARKET_HEADLAMP : 49|2@1+ (1,0) [0|0] "" SGW,RF_HUB
 SG_ VC_Dgtl_CHMSL_Cam_Prsnt : 25|1@1+ (1,0) [0|0] "" SGW,RF_HUB
 SG_ VC_WRSS_Prsnt : 29|1@1+ (1,0) [0|0] "" SGW,PCM,RF_HUB,ECM
 SG_ VC_Trlr_Rev_Guidance_Prsnt : 48|1@1+ (1,0) [0|0] "" SGW,RF_HUB
 SG_ VC_Box_Delete : 30|1@1+ (1,0) [0|0] "" SGW,RF_HUB
 SG_ VC_Aux_Trailer_Cam_Prsnt : 40|1@1+ (1,0) [0|0] "" SGW,RF_HUB

BO_ 1556 SD_RS_ITBM: 8 ITBM
 SG_ SD_RS_ITBM : 7|64@0+ (1,0) [0|0] "" FTM,SGW,ETM,DIAGNOST

BO_ 1590 SD_RS_ATMM: 8 ATMM
 SG_ SD_RS_ATMM : 7|64@0+ (1,0) [0|0] "" FTM,SGW,ETM,DIAGNOST

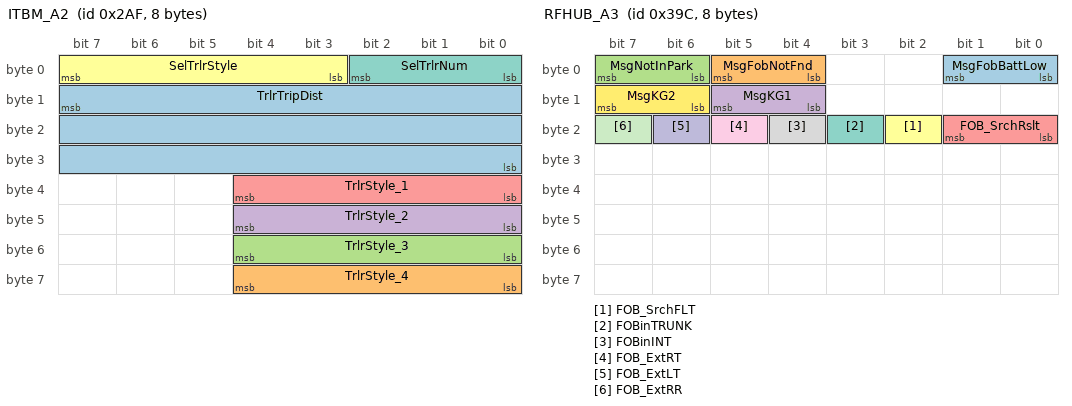
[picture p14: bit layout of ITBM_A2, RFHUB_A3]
BO_ 687 ITBM_A2: 8 ITBM
 SG_ TrlrTripDist : 15|24@0+ (0.1,0) [0|1677720] "km" SGW,IC
 SG_ TrlrStyle_4 : 56|5@1+ (1,0) [0|0] "" SGW,CBC
 SG_ TrlrStyle_3 : 48|5@1+ (1,0) [0|0] "" SGW,CBC
 SG_ TrlrStyle_2 : 40|5@1+ (1,0) [0|0] "" SGW,CBC
 SG_ TrlrStyle_1 : 32|5@1+ (1,0) [0|0] "" SGW,CBC
 SG_ SelTrlrStyle : 3|5@1+ (1,0) [0|0] "" SGW,IC,CBC
 SG_ SelTrlrNum : 0|3@1+ (1,0) [0|0] "" SGW,IC,CBC

BO_ 1428 ECU_APPL_ITBM: 8 ITBM
 SG_ ECU_APPL_ITBM : 7|64@0+ (1,0) [0|0] "" SGW,DIAGNOST

BO_ 1462 ECU_APPL_ATMM: 8 ATMM
 SG_ ECU_APPL_ATMM : 7|64@0+ (1,0) [0|0] "" SGW,DIAGNOST

BO_ 629 DAS_A6: 8 IRCM
 SG_ IRCM_AHB_On : 47|1@1+ (1,0) [0|0] "" SGW,CBC

BO_ 1236 D_RS_ITBM: 8 ITBM
 SG_ D_RS_ITBM : 7|64@0+ (1,0) [0|0] "" FTM,SGW,ETM,DIAGNOST

BO_ 1270 D_RS_ATMM: 8 ATMM
 SG_ D_RS_ATMM : 7|64@0+ (1,0) [0|0] "" FTM,SGW,ETM,DIAGNOST

BO_ 1876 D_RQ_ITBM: 8 DIAGNOST
 SG_ D_RQ_ITBM : 7|64@0+ (1,0) [0|0] "" ITBM

BO_ 1910 D_RQ_ATMM: 8 DIAGNOST
 SG_ D_RQ_ATMM : 7|64@0+ (1,0) [0|0] "" ATMM

BO_ 875 ATMM_1: 2 ATMM
 SG_ ATMM_PopUpRqst : 6|2@1+ (1,0) [0|0] "" SGW,IC

BO_ 1748 APPL_ECU_ITBM: 8 DIAGNOST
 SG_ APPL_ECU_ITBM : 7|64@0+ (1,0) [0|0] "" ITBM

BO_ 1782 APPL_ECU_ATMM: 8 DIAGNOST
 SG_ APPL_ECU_ATMM : 7|64@0+ (1,0) [0|0] "" ATMM

BO_ 924 RFHUB_A3: 8 RF_HUB
 SG_ MsgFobBattLow : 0|2@1+ (1,0) [0|0] "" SGW,IC
 SG_ MsgFobNotFnd : 4|2@1+ (1,0) [0|0] "" SGW,IC
 SG_ MsgNotInPark : 6|2@1+ (1,0) [0|0] "" SGW,IC
 SG_ MsgKG1 : 12|2@1+ (1,0) [0|0] "" SGW,IC
 SG_ FOB_SrchRslt : 16|2@1+ (1,0) [0|0] "" SGW,CBC
 SG_ FOB_SrchFLT : 18|1@1+ (1,0) [0|0] "" SGW,CBC
 SG_ FOBinTRUNK : 19|1@1+ (1,0) [0|0] "" SGW
 SG_ FOBinINT : 20|1@1+ (1,0) [0|0] "" SGW,CBC
 SG_ FOB_ExtRT : 21|1@1+ (1,0) [0|0] "" SGW,CBC
 SG_ FOB_ExtLT : 22|1@1+ (1,0) [0|0] "" SGW,CBC
 SG_ FOB_ExtRR : 23|1@1+ (1,0) [0|0] "" SGW,CBC
 SG_ MsgKG2 : 14|2@1+ (1,0) [0|0] "" SGW,IC

BO_ 818 HVAC_INFO: 8 CBC
 SG_ A2D_DRV_TEMP_DR_POS : 1|10@0+ (0.00489237,0) [0|5] "V" SGW,PCM,ECM
 SG_ Blower_Speed : 32|9@0+ (1,0) [0|350] "Hz" SGW,PCM,ECM
 SG_ Blower_Diagnostics : 49|10@0+ (0.1,0) [0|100] "%" SGW,PCM,ECM

BO_ 650 GW_I_C2: 8 CBC
 SG_ Radio_Theme : 48|8@1+ (1,0) [0|0] "" SGW,IC
 SG_ CSOPSSAutoStowSts : 58|1@1+ (1,0) [0|0] "" SGW,IC

BO_ 181 ECM_ENG_TRQ2: 8 ECM
 SG_ TrqRq_SlowFast : 2|11@0+ (1,-500) [-500|1546] "Nm" SGW,TCM
 SG_ EngRPM_Tach : 23|16@0+ (1,0) [0|65534] "RPM" SGW,IC
 SG_ CRC_ECM_ENG_TRQ2 : 56|8@1+ (1,0) [0|0] "" SGW,TCM
 SG_ MC_ECM_ENG_TRQ2 : 52|4@1+ (1,0) [0|15] "" SGW,TCM

BO_ 179 TCM_ENG_SPD: 8 TCM
 SG_ TargetTime : 1|10@0+ (10,0) [0|10230] "ms" SGW,ECM
 SG_ MC_TCM_ENG_SPD : 52|4@1+ (1,0) [0|15] "" SGW,ECM
 SG_ CRC_TCM_ENG_SPD : 56|8@1+ (1,0) [0|0] "" SGW,ECM
 SG_ TransLosses : 33|10@0+ (1,-500) [-500|500] "Nm" SGW,ECM
 SG_ OutputSpeed_2 : 23|16@0+ (1,0) [0|65534] "rpm" SGW,ECM

BO_ 774 TPM_A3: 4 RF_HUB
 SG_ Tire_RR2 : 0|2@1+ (1,0) [0|0] "" SGW,IC
 SG_ Tire_RL2 : 2|2@1+ (1,0) [0|0] "" SGW,IC
 SG_ TirePrssRR2 : 16|8@1+ (1,0) [0|126] "psi" SGW,ORC,IC,ETM
 SG_ TirePrssRL2 : 8|8@1+ (1,0) [0|126] "psi" SGW,ORC,IC,ETM

BO_ 960 TCM_500: 4 TCM
 SG_ TrqC_Temp : 0|8@1+ (1,-50) [-50|204] "°C" SGW,ECM

BO_ 1548 SD_RS_FDCM: 8 FDCM
 SG_ SD_RS_FDCM : 7|64@0+ (1,0) [0|0] "" FTM,SGW,ETM,DIAGNOST

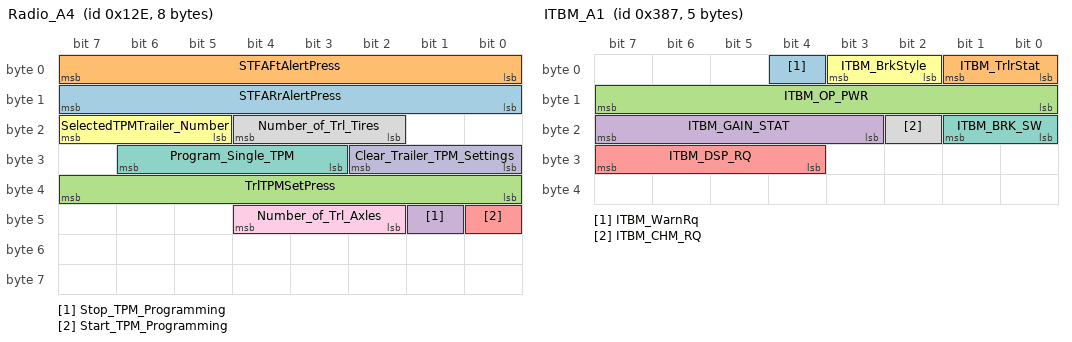
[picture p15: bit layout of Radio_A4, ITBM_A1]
BO_ 302 Radio_A4: 8 CBC
 SG_ STFARrAlertPress : 8|8@1+ (1,0) [0|126] "psi" SGW,RF_HUB
 SG_ STFAFtAlertPress : 0|8@1+ (1,0) [0|126] "psi" SGW,RF_HUB
 SG_ TrlTPMSetPress : 32|8@1+ (1,0) [0|254] "" TTPM,SGW
 SG_ Stop_TPM_Programming : 41|1@1+ (1,0) [0|0] "" TTPM,SGW
 SG_ Start_TPM_Programming : 40|1@1+ (1,0) [0|0] "" TTPM,SGW
 SG_ SelectedTPMTrailer_Number : 21|3@1+ (1,0) [0|0] "" TTPM,SGW
 SG_ Program_Single_TPM : 27|4@1+ (1,0) [0|0] "" TTPM,SGW
 SG_ Number_of_Trl_Tires : 18|3@1+ (1,0) [0|0] "" TTPM,SGW
 SG_ Number_of_Trl_Axles : 42|3@1+ (1,0) [0|0] "" TTPM,SGW
 SG_ Clear_Trailer_TPM_Settings : 24|3@1+ (1,0) [0|0] "" TTPM,SGW

BO_ 903 ITBM_A1: 5 ITBM
 SG_ ITBM_WarnRq : 4|1@1+ (1,0) [0|0] "" SGW,IC
 SG_ ITBM_TrlrStat : 0|2@1+ (1,0) [0|0] "" FTM,IRCM,SGW,PCM,PTS,IC,ECM,CBC
 SG_ ITBM_OP_PWR : 8|8@1+ (0.5,0) [0|100] "%" SGW,ORC,IC
 SG_ ITBM_GAIN_STAT : 19|5@1+ (0.5,0) [0|10] "" FTM,IRCM,SGW,ORC,IC
 SG_ ITBM_DSP_RQ : 28|4@1+ (1,0) [0|0] "" SGW,PCM,ORC,IC,ECM
 SG_ ITBM_BrkStyle : 2|2@1+ (1,0) [0|0] "" FTM,IRCM,SGW,ORC,IC,CBC
 SG_ ITBM_BRK_SW : 16|2@1+ (1,0) [0|0] "" IRCM,SGW,IC,ETM,CBC
 SG_ ITBM_CHM_RQ : 18|1@1+ (1,0) [0|0] "" SGW,IC

BO_ 1420 ECU_APPL_FDCM: 8 FDCM
 SG_ ECU_APPL_FDCM : 7|64@0+ (1,0) [0|0] "" SGW,DIAGNOST

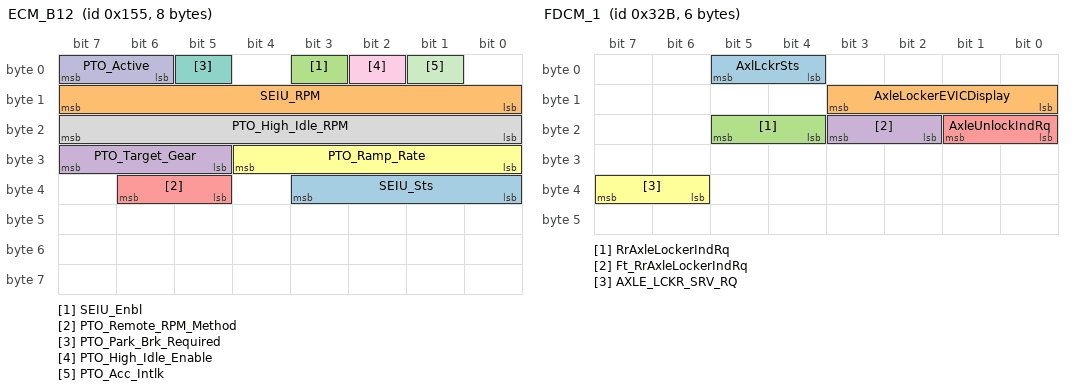
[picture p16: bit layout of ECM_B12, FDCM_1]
BO_ 341 ECM_B12: 8 ECM
 SG_ SEIU_Sts : 32|4@1+ (1,0) [0|0] "" SGW,IC
 SG_ SEIU_RPM : 8|8@1+ (25,600) [600|6950] "rpm" SGW,IC
 SG_ SEIU_Enbl : 3|1@1+ (1,0) [0|0] "" SGW,IC
 SG_ PTO_Target_Gear : 29|3@1+ (1,0) [0|0] "" SGW,TCM,IC
 SG_ PTO_Remote_RPM_Method : 37|2@1+ (1,0) [0|0] "" SGW,IC
 SG_ PTO_Ramp_Rate : 24|5@1+ (1,0) [0|0] "rpm" SGW,IC
 SG_ PTO_Park_Brk_Required : 5|1@1+ (1,0) [0|0] "" SGW,IC
 SG_ PTO_High_Idle_RPM : 16|8@1+ (25,600) [600|6950] "rpm" SGW,IC
 SG_ PTO_High_Idle_Enable : 2|1@1+ (1,0) [0|0] "" SGW,IC
 SG_ PTO_Active : 6|2@1+ (1,0) [0|0] "" IRCM,SGW,VSIM,CBC
 SG_ PTO_Acc_Intlk : 1|1@1+ (1,0) [0|0] "" SGW,IC

BO_ 1271 D_RS_VGT: 8 ECM
 SG_ D_RS_VGT : 7|64@0+ (1,0) [0|0] "" FTM,SGW,ETM

BO_ 1228 D_RS_FDCM: 8 FDCM
 SG_ D_RS_FDCM : 7|64@0+ (1,0) [0|0] "" FTM,SGW,ETM,DIAGNOST

BO_ 1911 D_RQ_VGT: 8 SGW
 SG_ D_RQ_VGT : 7|64@0+ (1,0) [0|0] "" PCM,ECM

BO_ 1868 D_RQ_FDCM: 8 DIAGNOST
 SG_ D_RQ_FDCM : 7|64@0+ (1,0) [0|0] "" FDCM

BO_ 564 CBC_PT7: 8 CBC
 SG_ AM_ECM_Trace : 22|2@1+ (1,0) [0|0] "" SGW,PCM,ECM

BO_ 664 ASCM_3: 8 ASCM
 SG_ BDL_Enbl : 4|1@1+ (1,0) [0|0] "" SGW,IC,CBC
 SG_ ASCM_HMI_Stat2 : 0|4@1+ (1,0) [0|0] "" SGW

BO_ 1740 APPL_ECU_FDCM: 8 DIAGNOST
 SG_ APPL_ECU_FDCM : 7|64@0+ (1,0) [0|0] "" FDCM

BO_ 703 ECM_B7: 8 ECM
 SG_ DrvAway_Alert : 7|1@1+ (1,0) [0|0] "" SGW,ORC,IC
 SG_ DrvAway_Inhibit : 15|1@1+ (1,0) [0|0] "" SGW,PTS,IC

BO_ 811 FDCM_1: 6 FDCM
 SG_ AxlLckrSts : 4|2@1+ (1,0) [0|0] "" SGW,ESC
 SG_ AxleLockerEVICDisplay : 8|4@1+ (1,0) [0|0] "" SGW,IC
 SG_ RrAxleLockerIndRq : 20|2@1+ (1,0) [0|0] "" SGW,CBC
 SG_ Ft_RrAxleLockerIndRq : 18|2@1+ (1,0) [0|0] "" SGW,CBC
 SG_ AxleUnlockIndRq : 16|2@1+ (1,0) [0|0] "" SGW,CBC
 SG_ AXLE_LCKR_SRV_RQ : 38|2@1+ (1,0) [0|0] "" SGW,IC

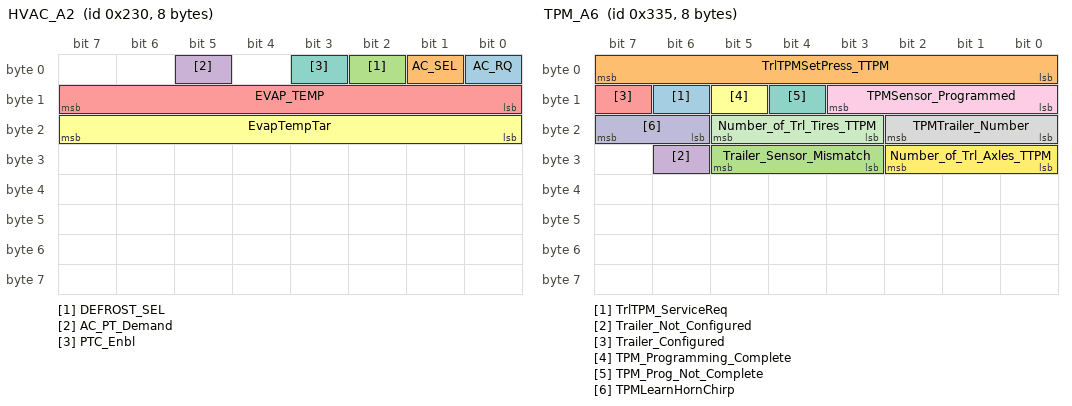
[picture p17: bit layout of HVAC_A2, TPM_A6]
BO_ 560 HVAC_A2: 8 CBC
 SG_ AC_RQ : 0|1@1+ (1,0) [0|0] "" SGW,PCM,ECM
 SG_ AC_SEL : 1|1@1+ (1,0) [0|0] "" SGW,PCM,VSIM,ECM
 SG_ DEFROST_SEL : 2|1@1+ (1,0) [0|0] "" SGW,PCM,ECM
 SG_ AC_PT_Demand : 5|1@1+ (1,0) [0|0] "" SGW,PCM,ECM
 SG_ EVAP_TEMP : 8|8@1+ (0.5,-20) [-20|107] "°C" SGW,PCM,ECM
 SG_ EvapTempTar : 16|8@1+ (0.5,-20) [-20|107] "°C" SGW,PCM,ECM
 SG_ PTC_Enbl : 3|1@1+ (1,0) [0|0] "" SGW,PCM,ECM

BO_ 821 TPM_A6: 8 TTPM
 SG_ TrlTPM_ServiceReq : 14|1@1+ (1,0) [0|0] "" SGW,IC
 SG_ TrlTPMSetPress_TTPM : 0|8@1+ (1,0) [0|254] "psi" SGW,IC
 SG_ Trailer_Sensor_Mismatch : 27|3@1+ (1,0) [0|0] "" SGW,IC
 SG_ Trailer_Not_Configured : 30|1@1+ (1,0) [0|0] "" SGW,IC,CBC
 SG_ Trailer_Configured : 15|1@1+ (1,0) [0|0] "" SGW,IC,CBC
 SG_ TPM_Programming_Complete : 13|1@1+ (1,0) [0|0] "" SGW,CBC
 SG_ TPM_Prog_Not_Complete : 12|1@1+ (1,0) [0|0] "" SGW,CBC
 SG_ TPMTrailer_Number : 16|3@1+ (1,0) [0|0] "" SGW,IC,CBC
 SG_ TPMSensor_Programmed : 8|4@1+ (1,0) [0|0] "" SGW,CBC
 SG_ TPMLearnHornChirp : 22|2@1+ (1,0) [0|0] "" SGW,CBC
 SG_ Number_of_Trl_Tires_TTPM : 19|3@1+ (1,0) [0|0] "" SGW,IC
 SG_ Number_of_Trl_Axles_TTPM : 24|3@1+ (1,0) [0|0] "" SGW,IC

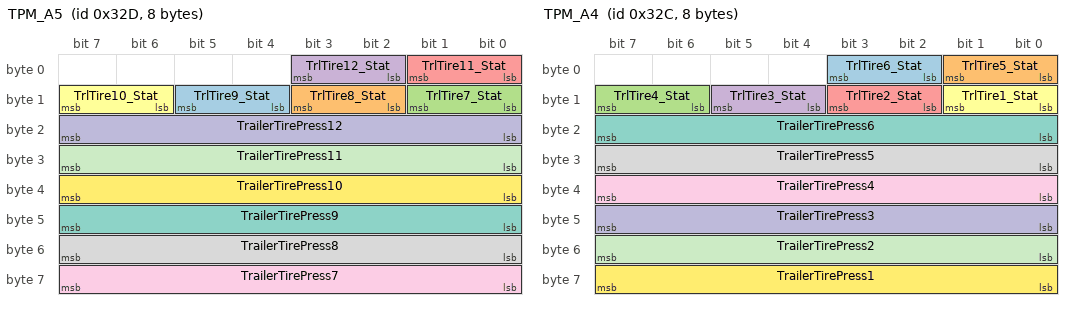
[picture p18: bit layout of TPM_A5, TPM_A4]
BO_ 813 TPM_A5: 8 TTPM
 SG_ TrlTire9_Stat : 12|2@1+ (1,0) [0|0] "" SGW,IC
 SG_ TrlTire8_Stat : 10|2@1+ (1,0) [0|0] "" SGW,IC
 SG_ TrlTire7_Stat : 8|2@1+ (1,0) [0|0] "" SGW,IC
 SG_ TrlTire12_Stat : 2|2@1+ (1,0) [0|0] "" SGW,IC
 SG_ TrlTire11_Stat : 0|2@1+ (1,0) [0|0] "" SGW,IC
 SG_ TrlTire10_Stat : 14|2@1+ (1,0) [0|0] "" SGW,IC
 SG_ TrailerTirePress9 : 40|8@1+ (1,0) [0|254] "psi" SGW,ORC,IC
 SG_ TrailerTirePress8 : 48|8@1+ (1,0) [0|254] "psi" SGW,ORC,IC
 SG_ TrailerTirePress7 : 56|8@1+ (1,0) [0|254] "psi" SGW,ORC,IC
 SG_ TrailerTirePress12 : 16|8@1+ (1,0) [0|254] "psi" SGW,ORC,IC
 SG_ TrailerTirePress11 : 24|8@1+ (1,0) [0|254] "psi" SGW,ORC,IC
 SG_ TrailerTirePress10 : 32|8@1+ (1,0) [0|254] "psi" SGW,ORC,IC

BO_ 812 TPM_A4: 8 TTPM
 SG_ TrlTire6_Stat : 2|2@1+ (1,0) [0|0] "" SGW,IC
 SG_ TrlTire5_Stat : 0|2@1+ (1,0) [0|0] "" SGW,IC
 SG_ TrlTire4_Stat : 14|2@1+ (1,0) [0|0] "" SGW,IC
 SG_ TrlTire3_Stat : 12|2@1+ (1,0) [0|0] "" SGW,IC
 SG_ TrlTire2_Stat : 10|2@1+ (1,0) [0|0] "" SGW,IC
 SG_ TrlTire1_Stat : 8|2@1+ (1,0) [0|0] "" SGW,IC
 SG_ TrailerTirePress6 : 16|8@1+ (1,0) [0|254] "psi" SGW,ORC,IC
 SG_ TrailerTirePress5 : 24|8@1+ (1,0) [0|254] "psi" SGW,ORC,IC
 SG_ TrailerTirePress4 : 32|8@1+ (1,0) [0|254] "psi" SGW,ORC,IC
 SG_ TrailerTirePress3 : 40|8@1+ (1,0) [0|254] "psi" SGW,ORC,IC
 SG_ TrailerTirePress2 : 48|8@1+ (1,0) [0|254] "psi" SGW,ORC,IC
 SG_ TrailerTirePress1 : 56|8@1+ (1,0) [0|254] "psi" SGW,ORC,IC

BO_ 1560 SD_RS_TTPM: 8 TTPM
 SG_ SD_RS_TTPM : 7|64@0+ (1,0) [0|0] "" SGW,DIAGNOST

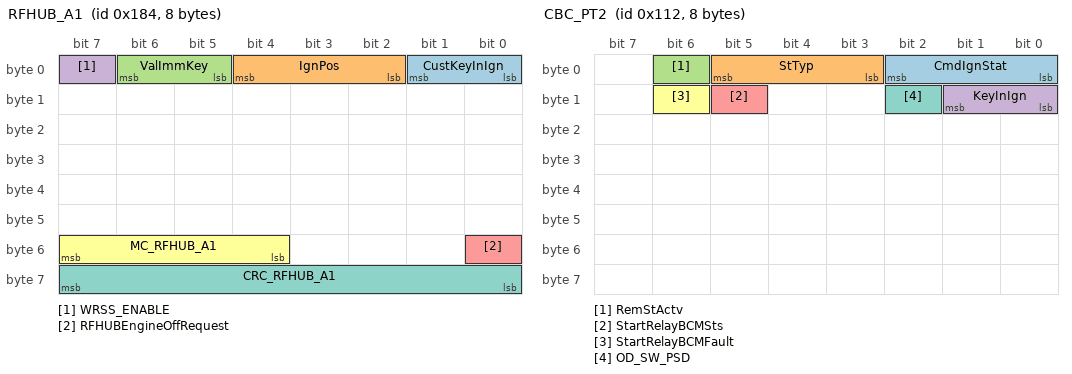
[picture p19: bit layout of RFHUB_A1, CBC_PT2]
BO_ 388 RFHUB_A1: 8 RF_HUB
 SG_ CustKeyInIgn : 0|2@1+ (1,0) [0|0] "" SGW,ETM,CBC
 SG_ IgnPos : 2|3@1+ (1,0) [0|0] "" SGW,ETM,CBC
 SG_ ValImmKey : 5|2@1+ (1,0) [0|0] "" SGW
 SG_ WRSS_ENABLE : 7|1@1+ (1,0) [0|0] "" SGW,IC
 SG_ RFHUBEngineOffRequest : 48|1@1+ (1,0) [0|0] "" SGW,IC,CBC
 SG_ MC_RFHUB_A1 : 52|4@1+ (1,0) [0|15] "" SGW,CBC
 SG_ CRC_RFHUB_A1 : 56|8@1+ (1,0) [0|0] "" SGW,CBC

BO_ 1048 NM_TTPM: 8 TTPM
 SG_ NM_Mode : 0|8@1+ (1,0) [0|0] "" TTPM,SGW,VSIM,SCCM,RF_HUB,IC,ESM,ESC,CBC,ASCM
 SG_ NM_Successor : 8|8@1+ (1,0) [0|63] "" TTPM,SGW,VSIM,SCCM,RF_HUB,IC,ESM,ESC,CBC,ASCM
 SG_ NM_Ud_Launch : 16|6@1+ (1,0) [0|0] "" TTPM,SGW,VSIM,SCCM,RF_HUB,IC,ESM,ESC,CBC,ASCM
 SG_ NM_Sleep_Ack : 22|1@1+ (1,0) [0|0] "" TTPM,SGW,VSIM,SCCM,RF_HUB,IC,ESM,ESC,CBC,ASCM
 SG_ NM_Sleep_Ind : 23|1@1+ (1,0) [0|0] "" TTPM,SGW,VSIM,SCCM,RF_HUB,IC,ESM,ESC,CBC,ASCM
 SG_ N : NaN|NaN@0+ (NaN,NaN) [NaN|NaN] "2" 4
 SG_ A : NaN|NaN@0+ (NaN,NaN) [NaN|NaN] "g" _
 SG_ W : NaN|NaN@0+ (NaN,NaN) [NaN|NaN] "_" T
 SG_ Nw_Id : 56|8@1+ (1,0) [0|0] "" TTPM,SGW,VSIM,SCCM,RF_HUB,IC,ESM,ESC,CBC,ASCM

BO_ 1432 ECU_APPL_TTPM: 8 TTPM
 SG_ ECU_APPL_TTPM : 7|64@0+ (1,0) [0|0] "" SGW,DIAGNOST

BO_ 1240 D_RS_TTPM: 8 TTPM
 SG_ D_RS_TTPM : 7|64@0+ (1,0) [0|0] "" SGW,DIAGNOST

BO_ 1880 D_RQ_TTPM: 8 DIAGNOST
 SG_ D_RQ_TTPM : 7|64@0+ (1,0) [0|0] "" TTPM

BO_ 1874 D_RQ_DCU: 8 DIAGNOST
 SG_ D_RQ_DCU : 7|64@0+ (1,0) [0|0] "" PCM,ECM

BO_ 274 CBC_PT2: 8 CBC
 SG_ CmdIgnStat : 0|3@1+ (1,0) [0|0] "" TTPM,ATMM,IRCM,SGW,ITBM,FDCM,PCM,VSIM,TCM,SCCM,RF_HUB,PTS,ORC,IC,ETM,ESM,ESC,ECM,DTCM,ASCM,AFLS
 SG_ StTyp : 3|3@1+ (1,0) [0|0] "" SGW,RF_HUB,DTCM
 SG_ RemStActv : 6|1@1+ (1,0) [0|0] "" SGW,PCM,TCM,RF_HUB,IC,ECM,DTCM
 SG_ KeyInIgn : 8|2@1+ (1,0) [0|0] "" SGW,RF_HUB,IC
 SG_ StartRelayBCMSts : 13|1@1+ (1,0) [0|0] "" SGW,PCM,ECM
 SG_ StartRelayBCMFault : 14|1@1+ (1,0) [0|0] "" SGW,PCM,ECM
 SG_ OD_SW_PSD : 10|1@1+ (1,0) [0|0] "" SGW,PCM,TCM

BO_ 1752 APPL_ECU_TTPM: 8 DIAGNOST
 SG_ APPL_ECU_TTPM : 7|64@0+ (1,0) [0|0] "" TTPM

BO_TX_BU_ 1089 : SGW,DIAGNOST;
BO_TX_BU_ 1464 : PCM,ECM;
BO_TX_BU_ 1568 : FTM,SGW,ETM,DIAGNOST;
BO_TX_BU_ 1592 : PCM,ECM;
BO_TX_BU_ 1728 : SGW,DIAGNOST;
BO_TX_BU_ 1729 : SGW,DIAGNOST;
BO_TX_BU_ 1730 : SGW,DIAGNOST;
BO_TX_BU_ 1732 : SGW,DIAGNOST;
BO_TX_BU_ 1735 : SGW,DIAGNOST;
BO_TX_BU_ 1737 : SGW,DIAGNOST;
BO_TX_BU_ 1747 : SGW,DIAGNOST;
BO_TX_BU_ 1762 : SGW,DIAGNOST;
BO_TX_BU_ 1763 : SGW,DIAGNOST;
BO_TX_BU_ 1784 : SGW,DIAGNOST;
BO_TX_BU_ 1785 : SGW,DIAGNOST;
BO_TX_BU_ 1856 : FTM,SGW,ETM,DIAGNOST;
BO_TX_BU_ 1858 : FTM,SGW,ETM,DIAGNOST;
BO_TX_BU_ 1860 : FTM,SGW,ETM,DIAGNOST;
BO_TX_BU_ 1863 : FTM,SGW,ETM,DIAGNOST;
BO_TX_BU_ 1865 : FTM,SGW,ETM,DIAGNOST;
BO_TX_BU_ 1875 : FTM,SGW,PCM,ETM,ECM,DIAGNOST;
BO_TX_BU_ 1890 : FTM,SGW,ETM,DIAGNOST;
BO_TX_BU_ 1891 : FTM,SGW,ETM,DIAGNOST;
BO_TX_BU_ 2015 : SGW,DIAGNOST;
BO_TX_BU_ 2016 : FTM,SGW,ETM,DIAGNOST;
BO_TX_BU_ 2017 : FTM,SGW,ETM,DIAGNOST;
BO_TX_BU_ 2024 : PCM,ECM;
BO_TX_BU_ 2025 : PCM,TCM;
BO_TX_BU_ 1739 : SGW,DIAGNOST;
BO_TX_BU_ 1777 : SGW,DIAGNOST;
BO_TX_BU_ 1867 : FTM,SGW,ETM,DIAGNOST;
BO_TX_BU_ 1905 : FTM,SGW,ETM,DIAGNOST;
BO_TX_BU_ 1768 : SGW,DIAGNOST;
BO_TX_BU_ 1896 : FTM,SGW,ETM,DIAGNOST;
BO_TX_BU_ 530 : PCM,ECM;
BO_TX_BU_ 778 : PCM,ECM;
BO_TX_BU_ 1766 : SGW,DIAGNOST;
BO_TX_BU_ 1894 : FTM,SGW,ETM,DIAGNOST;
BO_TX_BU_ 517 : PCM,ECM;
BO_TX_BU_ 55 : PCM,TCM;
BO_TX_BU_ 1150 : FTM,SGW,ETM,DIAGNOST;
BO_TX_BU_ 676 : PCM,ECM;
BO_TX_BU_ 1876 : FTM,SGW,ETM,DIAGNOST;
BO_TX_BU_ 1910 : FTM,SGW,ETM,DIAGNOST;
BO_TX_BU_ 1748 : SGW,DIAGNOST;
BO_TX_BU_ 1782 : SGW,DIAGNOST;
BO_TX_BU_ 181 : PCM,ECM;
BO_TX_BU_ 179 : PCM,TCM;
BO_TX_BU_ 341 : PCM,ECM;
BO_TX_BU_ 1271 : PCM,ECM;
BO_TX_BU_ 1911 : ETM,FTM,SGW;
BO_TX_BU_ 1868 : FTM,SGW,ETM,DIAGNOST;
BO_TX_BU_ 1740 : SGW,DIAGNOST;
BO_TX_BU_ 1880 : SGW,DIAGNOST;
BO_TX_BU_ 1874 : SGW,DIAGNOST;
BO_TX_BU_ 1752 : SGW,DIAGNOST;
CM_ SG_ 999 BU_NET_CFG_STAT_PT "Backup for network configuration status";
CM_ SG_ 999 BU_NetCfg_ACC "Backup for Active Cruise Control (1=present)";
CM_ SG_ 999 BU_NetCfg_ADCM "Backup for Active Damping Control Module (1=present)";
CM_ SG_ 999 BU_NetCfg_AHLM "Backup for Automatic Headlamp Leveling Module (1=present)";
CM_ SG_ 999 BU_NetCfg_VSIM_C "Backup for Vehicle System Interface Module (1=present)";
CM_ SG_ 999 BU_NetCfg_ASCM "Backup for Air Suspension Control Module (1=present)";
CM_ SG_ 999 BU_NetCfg_CBC_PT "Backup for Common Body Controller PT Bus (1=present)";
CM_ SG_ 999 BU_NetCfg_DTCM "Backup for Drivetrain Control Module (1=present)";
CM_ SG_ 999 BU_NetCfg_ECM "Backup for Engine Control Module (1=present)";
CM_ SG_ 999 BU_NetCfg_EPS "Backup for Electric Power Steering (1=present)";
CM_ SG_ 999 BU_NetCfg_ESM "Backup for Electronic Shift Module (1=present)";
CM_ SG_ 999 BU_NetCfg_ESC "Backup for Electronic Stability Module / Anti-Lock Brake (1=present)";
CM_ SG_ 999 BU_NetCfg_EPB "Backup for Electric Park Brake Module (1=present)";
CM_ SG_ 999 BU_NetCfg_RF_HUB "Backup for RF HUB Node (1=present)";
CM_ SG_ 999 BU_NetCfg_IC "Backup for Instrument Cluster (1=present)";
CM_ SG_ 999 BU_NetCfg_DASM "Backup for Driver Assistance System Module (1=present)";
CM_ SG_ 999 BU_NetCfg_FDCM "Backup for Final Drive Control Module (1=present)";
CM_ SG_ 999 BU_NetCfg_EPPM "Backup for  Elect. Pedestrian protection module (1=present)";
CM_ SG_ 999 BU_NetCfg_ORC "Backup for Occupant Restraint Controller (1=present)";
CM_ SG_ 999 BU_NetCfg_PTS "Backup for Parktronics System (1=present)";
CM_ SG_ 999 BU_NetCfg_SCCM "Backup for Steering Column Control Module (1=present)";
CM_ SG_ 999 BU_NetCfg_ELSD "Backup for Electric Limited Slip Differential (1=present)";
CM_ SG_ 999 BU_NetCfg_TCM "Backup for Automatic Transmission Controller (1=present)";
CM_ SG_ 999 BU_NetCfg_TPM "Backup for Tire Pressure Monitor (1=present)";
CM_ SG_ 999 BU_NetCfg_PASS_PT "Backup for Personal Assistant Safety System Module PT Bus (1=present)";
CM_ SG_ 999 BU_NetCfg_AFLS "Backup for Advanced Front Lighting System (1=present)";
CM_ SG_ 999 BU_NetCfg_ITBM "Backup for Integrated Trailer Brake Module (1=present)";
CM_ SG_ 999 BU_NetCfg_OCM "Backup for Occupant Classification Module (1=present)";
CM_ SG_ 999 BU_NetCfg_HaLF "Backup for Haptic Lane Feedback module (1=present)";
CM_ SG_ 999 BU_NetCfg_ANC "Backup for Active Noise Cancellation (1=present)";
CM_ SG_ 999 BU_NetCfg_HCP "Backup for Hybrid Control Processor (1=present)";
CM_ SG_ 999 BU_NetCfg_ESL "Backup for Electric Steering Lock (1=present)";
CM_ SG_ 999 BU_NetCfg_BSMO "Backup for Brake System Module - OBD (1=present)";
CM_ SG_ 999 BU_NetCfg_SGW "Backup for Security GateWay (1=present)";
CM_ SG_ 999 BU_NetCfg_DPDM "Backup for Driver Presence Detection Module (1=present)";
CM_ SG_ 999 BU_NetCfg_ASBS "Automatic Sway Bar System Module (Present = 1, Not Present = 0)";
CM_ SG_ 999 BU_NetCfg_ATMM "Backup Active Tuned Mass Module (Present = 1, Not Present = 0)";
CM_ SG_ 999 BU_NetCfg_SWSM "Steering wheel sensor module (HOD)";
CM_ SG_ 999 BU_NetCfg_MSBD "Motorized Seatbelt Module (1=present)";
CM_ SG_ 1000 VC_VehCfg1_Stat "Configuration messages status 1";
CM_ SG_ 1000 VC_MODEL_YEAR "Model year";
CM_ SG_ 1000 VC_VEH_LINE "Vehicle line";
CM_ SG_ 1000 VC_COUNTRY "Country Code";
CM_ SG_ 1000 VC_LHD_RHD "Left/right hand drive";
CM_ SG_ 1000 VC_RemStPrsnt "Remote start present; present = [1]";
CM_ SG_ 1000 VC_XWD "Drive configuration";
CM_ SG_ 1000 VC_EmodePrsnt "E-Mode feature present; True = [1]";
CM_ SG_ 1000 VC_AUTO_HB "Auto Highbeam feature present; present = [1]";
CM_ SG_ 1000 VC_BODY_STYLE "Body style";
CM_ SG_ 1000 VC_MAX_VEH_SPD "Maximum vehicle speed";
CM_ SG_ 1000 VC_ShftrTyp "Shifter type";
CM_ SG_ 1000 VC_PTS_DispTyp "PTS display type and location";
CM_ SG_ 1000 VC_PP_Prsnt "Performance Pages Present (1=present)";
CM_ SG_ 1000 VC_SpecialPKG "Special sales code package";
CM_ SG_ 1000 VC_HdRstPrsnt "Headrest present; present = [1]";
CM_ SG_ 1000 VC_SCR_Prsnt "Urea/SCR system present; present = [1]";
CM_ SG_ 1000 VC_PTS_Config "Parktronics system configuration";
CM_ SG_ 1000 VC_RVCM_Prsnt "Rear view camera (1=present)";
CM_ SG_ 1000 VC_CHMCM_Prsnt "CHMSL camera (1=present)";
CM_ SG_ 1000 VC_HDC_Prsnt "Hill descent feature is present; present = [1]";
CM_ SG_ 1000 VC_SSC_Prsnt "Select speed control feature is present; present = [1]";
CM_ SG_ 1001 VC_VehCfg2_Stat "Configuration messages status 2";
CM_ SG_ 1001 VC_PwrIvtrTyp "Power inverter type";
CM_ SG_ 1001 VC_ThatchamPrsnt "Thatcham present; present = [1]";
CM_ SG_ 1001 VC_RunFlatTirePrsnt "Run flat tires present; present = [1]";
CM_ SG_ 1001 VC_MaseratiMd "Maserati vehicle mode";
CM_ SG_ 1001 VC_PADS_Prsnt "Pass. airbag disable switch present; present = [1]";
CM_ SG_ 1001 VC_RainSnsPrsnt "Rain sensor present; present = [1]";
CM_ SG_ 1001 VC_SKIM_PRSNT "SKIM system present; present = [1]";
CM_ SG_ 1001 VC_AC_Prsnt "Vehicle is equipped with air conditioning; present = [1]";
CM_ SG_ 1001 VC_CRUISE_PRSNT "Cruise feature is present; present = [1]";
CM_ SG_ 1001 VC_FG_PRSNT "Flipper glass present; present = [1]";
CM_ SG_ 1001 VC_FULL_SPARE "Full size spare; present = [1]";
CM_ SG_ 1001 VC_OffRoad "Off road capable; present = [1]";
CM_ SG_ 1001 VC_SpecialPKG_IC "Special sales code package";
CM_ SG_ 1001 VC_ECO_Indicator "ECO Indicator present on vehicle; True = [1]";
CM_ SG_ 1001 VC_DRVMD_Prsnt "Drive mode feature configuration (1 = Present)";
CM_ SG_ 1001 VC_MemoryDRVMD_Prsnt "Memory drive mode sub-feature configuration (1 = Present)";
CM_ SG_ 1001 VC_ESCDrvMd_Prsnt "ESC drive mode sub-feature configuration (1 = Present)";
CM_ SG_ 1001 VC_EngPowerDrvMd_Prsnt "ECM drive mode sub-feature configuration (1 = Present)";
CM_ SG_ 1001 VC_SecPrkPrsnt "Secure park feature present; present = [1]";
CM_ SG_ 1001 VC_ShftInd_Prsnt "Configuration for performance & gear shift indication";
CM_ SG_ 1001 VC_MaxLdPressRrTr "Max Load Inflation Pressure Rear Tire";
CM_ SG_ 1001 VC_MaxLdPressFtTr "Max Load Inflation Pressure Front Tire";
CM_ SG_ 1001 VC_LgtLdPressRrTr "Light Load Inflation Pressure Rear Tire";
CM_ SG_ 1001 VC_LgtLdPressFtTr "Light Load Inflation Pressure Front Tire";
CM_ SG_ 1002 VC_VehCfg3_Stat "Configuration messages status 3";
CM_ SG_ 1002 VC_POLICE "Police lighting feature; present = [1]";
CM_ SG_ 1002 VC_PWR_LFT_GT "Power lift gate present; present = [1]";
CM_ SG_ 1002 VC_PWR_RT_SLDR "Power right sliding door present; present = [1]";
CM_ SG_ 1002 VC_PWR_LT_SLDR "Power left sliding door present; present = [1]";
CM_ SG_ 1002 VC_RKE_PRSNT "RKE system present; present = [1]";
CM_ SG_ 1002 VC_SunShade_Present "Vehicle equipped w/SunShade (1=present)";
CM_ SG_ 1002 VC_TcaseTyp "Tcase type";
CM_ SG_ 1002 VC_WHL_BASE "Wheel base";
CM_ SG_ 1002 VC_FOBIKsafeENBL "Feature FOBIK safe is enabled; present = [1]";
CM_ SG_ 1002 VC_ELV_Prsnt "ELV system present; enabled=[1], disabled=[0]";
CM_ SG_ 1002 VC_FUEL_CAP "Fuel capacity";
CM_ SG_ 1002 VC_WIN_EXPR_FEAT "Window express feature configuration";
CM_ SG_ 1002 VC_ADJ_PDL_PRSNT "Adjustable pedal system present (non-memory); present = [1]";
CM_ SG_ 1002 VC_AUTO_HL "Auto headlamp feature present; present = [1]";
CM_ SG_ 1002 VC_DrAlrPrsnt "Door alert feature present; present = [1]";
CM_ SG_ 1002 VC_DualFuelSens "Vehicle equipped with two fuel sending units; present = [1]";
CM_ SG_ 1002 VC_SRT_PRSNT "Vehicle is an SRT; present = [1]";
CM_ SG_ 1002 VC_DSBL_CLK_DISP "Disable display of radio clock; 1 = clock display disabled";
CM_ SG_ 1002 VC_ChassisType "Chassis type (including suspension, brakes, and tires)";
CM_ SG_ 1002 VC_TEMP_DISP "Display outside temperature present; present = [1]";
CM_ SG_ 1002 VC_HVAC_Config "HVAC Configuration";
CM_ SG_ 1002 VC_VEH_BRAND "Vehicle brand type";
CM_ SG_ 1002 VC_CMP_DISP "Display compass heading present; present = [1]";
CM_ SG_ 1002 VC_IntEC_MIRR "Vehicle is equipped with an interior EC mirror; present = [1]";
CM_ SG_ 1002 VC_ESCL_PRSNT "ESCL system present; enabled=[1], disabled=[0]";
CM_ SG_ 1002 VC_HID_HL "High intensity discharge head lamps; present = [1]";
CM_ SG_ 1002 VC_SecLkPrsnt "Secondary Lock Present; [1] = True";
CM_ SG_ 1002 VC_Liftgate_Trunk "Liftgate or trunk";
CM_ SG_ 1002 VC_CMS "Collision Mitigation System present; present = [1]";
CM_ SG_ 1002 VC_FCW "Forward Collision Warning present; present = [1]";
CM_ SG_ 1002 VC_Base_TPM "Base TPM system present; present = [1]";
CM_ SG_ 1002 VC_Prem_TPM "Premium TPM system present; present = [1]";
CM_ SG_ 1002 VC_PDDL_PRSNT "Paddle shift feature is present; present = [1]";
CM_ SG_ 1002 VC_SPORT_PRSNT "Sport mode is present; present = [1]";
CM_ SG_ 1002 VC_AutoParkPrsnt "Automatic transmission parking feature is present; present = [1]";
CM_ SG_ 1002 VC_PE_Prsnt "Feature passive entry is present; present = [1]";
CM_ SG_ 1002 VC_KG_Prsnt "Feature keyless go is present; present = [1]";
CM_ SG_ 1003 VC_TCASE_HI_RATIO "Transfer case high ratio";
CM_ SG_ 1003 VC_VehCfg4_Stat "Configuration messages status 4";
CM_ SG_ 1003 VC_AXLE_RATIO "Axle ratio";
CM_ SG_ 1003 VC_TCASE_LO_RATIO "Transfer case low range reduction ratio";
CM_ SG_ 1003 VC_TIRE_CIRCUMF "Dynamic tire circumference (all or rear)";
CM_ SG_ 1004 VC_BU_VehCfg1_Stat "Backup for Configuration messages status 1";
CM_ SG_ 1004 VC_BU_MODEL_YEAR "Backup for Model year";
CM_ SG_ 1004 VC_BU_VEH_LINE "Backup for Vehicle line";
CM_ SG_ 1004 VC_BU_COUNTRY "Backup for Country Code";
CM_ SG_ 1004 VC_BU_LHD_RHD "Backup for Left/right hand drive";
CM_ SG_ 1004 VC_BU_RemStPrsnt "Backup for Remote start present; present = [1]";
CM_ SG_ 1004 VC_BU_XWD "Backup for Drive configuration";
CM_ SG_ 1004 VC_BU_EmodePrsnt "Backup for E-Mode feature present; True = [1]";
CM_ SG_ 1004 VC_BU_AUTO_HB "Backup for Auto Highbeam feature present; present = [1]";
CM_ SG_ 1004 VC_BU_BODY_STYLE "Backup for Body style";
CM_ SG_ 1004 VC_BU_MAX_VEH_SPD "Backup for Maximum vehicle speed";
CM_ SG_ 1004 VC_BU_ShftrTyp "Shifter type";
CM_ SG_ 1004 VC_BU_PTS_DispTyp "PTS display type and location";
CM_ SG_ 1004 VC_BU_PP_Prsnt "Backup for Performance Pages Present (1=present)";
CM_ SG_ 1004 VC_BU_SpecialPKG "Special sales code package";
CM_ SG_ 1004 VC_BU_HdRstPrsnt "Backup for headrest present; present = [1]";
CM_ SG_ 1004 VC_BU_SCR_Prsnt "Backup for Urea/SCR system present; present = [1]";
CM_ SG_ 1004 VC_BU_PTS_Config "Backup for Parktronics system configuration";
CM_ SG_ 1004 VC_BU_RVCM_Prsnt "Backup for rear view camera (1=present)";
CM_ SG_ 1004 VC_BU_CHMCM_Prsnt "Backup for CHMSL camera (1=present)";
CM_ SG_ 1004 VC_BU_HDC_Prsnt "Backup for Hill descent feature is present; present = [1]";
CM_ SG_ 1004 VC_BU_SSC_Prsnt "Backup for Select speed control feature is present; present = [1]";
CM_ SG_ 1005 VC_BU_VehCfg2_Stat "Backup for Configuration messages status 2";
CM_ SG_ 1005 VC_BU_PwrIvtrTyp "Backup for power inverter type";
CM_ SG_ 1005 VC_BU_ThatchamPrsnt "Backup for thatcham present; present = [1]";
CM_ SG_ 1005 VC_BU_RunFlatTirePrsnt "Backup for run flat tires present; present = [1]";
CM_ SG_ 1005 VC_BU_MaseratiMd "Backup for Maserati vehicle mode";
CM_ SG_ 1005 VC_BU_PADS_Prsnt "Backup for Pass. airbag disable switch present; present = [1]";
CM_ SG_ 1005 VC_BU_RainSnsPrsnt "Backup for Rain sensor present; present = [1]";
CM_ SG_ 1005 VC_BU_SKIM_PRSNT "Backup for SKIM system present; present = [1]";
CM_ SG_ 1005 VC_BU_AC_Prsnt "Backup for Vehicle is equipped with air conditioning; present = [1]";
CM_ SG_ 1005 VC_BU_CRUISE_PRSNT "Backup for Cruise feature is present; present = [1]";
CM_ SG_ 1005 VC_BU_FG_PRSNT "Backup for Flipper glass present; present = [1]";
CM_ SG_ 1005 VC_BU_FULL_SPARE "Backup for Full size spare; present = [1]";
CM_ SG_ 1005 VC_BU_OffRoad "Backup for Off road capable; present = [1]";
CM_ SG_ 1005 VC_BU_SpecialPKG_IC "Special sales code package";
CM_ SG_ 1005 VC_BU_ECO_Indicator "Backup for ECO Indicator present on vehicle; True = [1]";
CM_ SG_ 1005 VC_BU_DRVMD_Prsnt "Backup for drive mode feature configuration (1 = Present)";
CM_ SG_ 1005 VC_BU_MemoryDRVMD_Prsnt "Backup for memory drive mode sub-feature configuration (1 = Present)";
CM_ SG_ 1005 VC_BU_ESCDrvMd_Prsnt "Backup for ESC drive mode sub-feature configuration (1 = Present)";
CM_ SG_ 1005 VC_BU_EngPowerDrvMd_Prsnt "Backup for ECM drive mode sub-feature configuration (1 = Present)";
CM_ SG_ 1005 VC_BU_SecPrkPrsnt "Backup for secure park feature present; present = [1]";
CM_ SG_ 1005 VC_BU_ShftInd_Prsnt "Backup for configuration for performance & gear shift indication";
CM_ SG_ 1005 VC_BU_MaxLdPressRrTr "Backup for Max Load Inflation Pressure Rear Tire";
CM_ SG_ 1005 VC_BU_MaxLdPressFtTr "Backup for Max Load Inflation Pressure Front Tire";
CM_ SG_ 1005 VC_BU_LgtLdPressRrTr "Backup for Light Load Inflation Pressure Rear Tire";
CM_ SG_ 1005 VC_BU_LgtLdPressFtTr "Backup for Light Load Inflation Pressure Front Tire";
CM_ SG_ 1006 VC_BU_VehCfg3_Stat "Backup for Configuration messages status 3";
CM_ SG_ 1006 VC_BU_POLICE "Backup for Police lighting feature; present = [1]";
CM_ SG_ 1006 VC_BU_PWR_LFT_GT "Backup for Power lift gate present; present = [1]";
CM_ SG_ 1006 VC_BU_PWR_RT_SLDR "Backup for Power right sliding door present; present = [1]";
CM_ SG_ 1006 VC_BU_PWR_LT_SLDR "Backup for Power left sliding door present; present = [1]";
CM_ SG_ 1006 VC_BU_RKE_PRSNT "Backup for RKE system present; present = [1]";
CM_ SG_ 1006 VC_BU_SunShade_Present "Backup for Vehicle equipped w/SunShade (1=present)";
CM_ SG_ 1006 VC_BU_TcaseTyp "Backup for Tcase type";
CM_ SG_ 1006 VC_BU_WHL_BASE "Backup for Wheel base";
CM_ SG_ 1006 VC_BU_FOBIKsafeENBL "Backup for FOBIK safe feature; present = [1]";
CM_ SG_ 1006 VC_BU_ELV_PRSNT "Backup for ELV system present; enabled=[1], disabled=[0]";
CM_ SG_ 1006 VC_BU_FUEL_CAP "Backup for Fuel capacity";
CM_ SG_ 1006 VC_BU_WIN_EXPR_FEAT "Backup for Window express feature configuration";
CM_ SG_ 1006 VC_BU_ADJ_PDL_PRSNT "Backup for Adjustable pedal system present (non-memory); present = [1]";
CM_ SG_ 1006 VC_BU_AUTO_HL "Backup for Auto headlamp feature present; present = [1]";
CM_ SG_ 1006 VC_BU_DrAlrPrsnt "Backup for Door alert feature present; present = [1]";
CM_ SG_ 1006 VC_BU_DualFuelSens "Backup for Vehicle equipped with two fuel sending units; present = [1]";
CM_ SG_ 1006 VC_BU_SRT_PRSNT "Backup for Vehicle is an SRT; present = [1]";
CM_ SG_ 1006 VC_BU_DSBL_CLK_DISP "Backup of Disable display of radio clock; 1 = clock display disabled";
CM_ SG_ 1006 VC_BU_ChassisType "Backup for chassis type (including suspension, brakes, and tires)";
CM_ SG_ 1006 VC_BU_TEMP_DISP "Backup for display outside temperature present; present = [1]";
CM_ SG_ 1006 VC_BU_HVAC_Config "Backup for HVAC Configuration";
CM_ SG_ 1006 VC_BU_VEH_BRAND "Backup for Vehicle brand type";
CM_ SG_ 1006 VC_BU_CMP_DISP "Backup for display compass heading present; present = [1]";
CM_ SG_ 1006 VC_BU_IntEC_MIRR "Backup for vehicle is equipped with an interior EC mirror; present = [1]";
CM_ SG_ 1006 VC_BU_ESCL_Prsnt "Backup for ESCL system present; enabled=[1], disabled=[0]";
CM_ SG_ 1006 VC_BU_HID_HL "Backup for High intensity discharge head lamps; present = [1]";
CM_ SG_ 1006 VC_BU_SecLkPrsnt "Backup for Secondary Lock Present; [1] = True";
CM_ SG_ 1006 VC_BU_Liftgate_Trunk "Backup for Liftgate or trunk";
CM_ SG_ 1006 VC_BU_CMS "Backup for Collision Mitigation System present; present = [1]";
CM_ SG_ 1006 VC_BU_FCW "Backup for Forward Collision Warning present; present = [1]";
CM_ SG_ 1006 VC_BU_Base_TPM "Backup for Base TPM system present; present = [1]";
CM_ SG_ 1006 VC_BU_Prem_TPM "Backup for Premium TPM system present; present = [1]";
CM_ SG_ 1006 VC_BU_PDDL_PRSNT "backup for Paddle shift feature is present; present = [1]";
CM_ SG_ 1006 VC_BU_SPORT_PRSNT "Backup for Sport mode is present; present = [1]";
CM_ SG_ 1006 VC_BU_AutoParkPrsnt "Backup for automatic transmission parking feature is present; present = [1]";
CM_ SG_ 1006 VC_BU_PE_Prsnt "Backup for passive entry is present; present = [1]";
CM_ SG_ 1006 VC_BU_KG_Prsnt "Backup for keyless go is present; present = [1]";
CM_ SG_ 1007 VC_BU_TCASE_HI_RATIO "Backup for Transfer case high ratio";
CM_ SG_ 1007 VC_BU_VehCfg4_Stat "Backup for Configuration messages status 4";
CM_ SG_ 1007 VC_BU_AXLE_RATIO "Backup for Axle ratio";
CM_ SG_ 1007 VC_BU_TCASE_LO_RATIO "Backup for Transfer case low range reduction ratio";
CM_ SG_ 1007 VC_BU_TIRE_CIRCUMF "Backup for Dynamic tire circumference (all or rear)";
CM_ SG_ 1008 EC_ECUCfg1_Stat "ECU Configuration messages status 1";
CM_ SG_ 1008 EC_CBC1A "CBC ecu configuration 1A";
CM_ SG_ 1008 EC_CBC1B "CBC ecu configuration 1B";
CM_ SG_ 1008 EC_CBC2 "CBC ecu configuration 2";
CM_ SG_ 1009 EC_ECUCfg2_Stat "ECU Configuration messages status 2";
CM_ SG_ 1009 EC_CBC3A "CBC ecu configuration 3A";
CM_ SG_ 1009 EC_CBC3B "CBC ecu configuration 3B";
CM_ SG_ 1009 EC_CBC4 "CBC ecu configuration 4";
CM_ SG_ 1010 EC_ECUCfg3_Stat "ECU Configuration messages status 3";
CM_ SG_ 1010 EC_AudTel1A "Audio and telematics ecu configuration 1A";
CM_ SG_ 1010 EC_AudTel1B "Audio and telematics ecu configuration 1B";
CM_ SG_ 1010 EC_AudTel2 "Audio and telematics ecu configuration 2";
CM_ SG_ 1011 EC_ECUCfg4_Stat "ECU Configuration messages status 4";
CM_ SG_ 1011 EC_Cluster1A "Instrument cluster ecu configuration 1A";
CM_ SG_ 1011 EC_Cluster1B "Instrument cluster ecu configuration 1B";
CM_ SG_ 1011 EC_Cluster2 "Instrument cluster ecu configuration 2";
CM_ SG_ 1012 EC_ECUCfg5_Stat "ECU Configuration messages status 5";
CM_ SG_ 1012 EC_WirelessA "Wireless ecu configurationA";
CM_ SG_ 1012 EC_WirelessB "Wireless ecu configurationB";
CM_ SG_ 1012 EC_Doors "Doors ecu configuration";
CM_ SG_ 1012 EC_Memory "Memory ecu configuration";
CM_ SG_ 1013 EC_ECUCfg6_Stat "ECU Configuration messages status 6";
CM_ SG_ 1013 EC_BrakesA "Brake system ecu configurationA";
CM_ SG_ 1013 EC_BrakesB "Brake system ecu configurationB";
CM_ SG_ 1013 EC_Steering "Steering ecu configuration";
CM_ SG_ 1013 EC_Powertrain "Powertrain ecu configuration";
CM_ SG_ 1013 EC_Safety "Safety ecu configuration";
CM_ SG_ 1014 EC_ECUCfg7_Stat "ECU Configuration messages status 7";
CM_ SG_ 1014 EC_CBC5A "CBC ecu configuration 5A";
CM_ SG_ 1014 EC_CBC5B "CBC ecu configuration 5B";
CM_ SG_ 1014 EC_CBC6 "CBC ecu configuration 6";
CM_ SG_ 1015 EC_ECUCfg8_Stat "ECU Configuration messages status 8";
CM_ SG_ 1015 EC_CBC7A "CBC ecu configuration 7A";
CM_ SG_ 1015 EC_CBC7B "CBC ecu configuration 7B";
CM_ SG_ 1015 EC_CBC8 "CBC ecu configuration 8";
CM_ SG_ 1016 EC_BU_ECUCfg1_Stat "Backup for ECU Configuration messages status 1";
CM_ SG_ 1016 EC_BU_CBC1A "Backup for CBC ecu configuration 1A";
CM_ SG_ 1016 EC_BU_CBC1B "Backup for CBC ecu configuration 1B";
CM_ SG_ 1016 EC_BU_CBC2 "Backup for CBC ecu configuration 2";
CM_ SG_ 1017 EC_BU_ECUCfg2_Stat "Backup for ECU Configuration messages status 2";
CM_ SG_ 1017 EC_BU_CBC3A "Backup for CBC ecu configuration 3A";
CM_ SG_ 1017 EC_BU_CBC3B "Backup for CBC ecu configuration 3B";
CM_ SG_ 1017 EC_BU_CBC4 "Backup for CBC ecu configuration 4";
CM_ SG_ 1018 EC_BU_ECUCfg3_Stat "Backup for ECU Configuration messages status 3";
CM_ SG_ 1018 EC_BU_AudTel1A "Backup for Audio and telematics ecu configuration 1A";
CM_ SG_ 1018 EC_BU_AudTel1B "Backup for Audio and telematics ecu configuration 1B";
CM_ SG_ 1018 EC_BU_AudTel2 "Backup for Audio and telematics ecu configuration 2";
CM_ SG_ 1019 EC_BU_ECUCfg4_Stat "Backup for ECU Configuration messages status 4";
CM_ SG_ 1019 EC_BU_Cluster1A "Backup for Instrument cluster ecu configuration 1A";
CM_ SG_ 1019 EC_BU_Cluster1B "Backup for Instrument cluster ecu configuration 1B";
CM_ SG_ 1019 EC_BU_Cluster2 "Backup for Instrument cluster ecu configuration 2";
CM_ SG_ 1020 EC_BU_ECUCfg5_Stat "Backup for ECU Configuration messages status 5";
CM_ SG_ 1020 EC_BU_WirelessA "Backup for Wireless ecu configurationA";
CM_ SG_ 1020 EC_BU_WirelessB "Backup for Wireless ecu configurationB";
CM_ SG_ 1020 EC_BU_Doors "Backup for Doors ecu configuration";
CM_ SG_ 1020 EC_BU_Memory "Backup for Memory ecu configuration";
CM_ SG_ 1021 EC_BU_ECUCfg6_Stat "Backup for ECU Configuration messages status 6";
CM_ SG_ 1021 EC_BU_BrakesA "Backup for Brake system ecu configurationA";
CM_ SG_ 1021 EC_BU_BrakesB "Backup for Brake system ecu configurationB";
CM_ SG_ 1021 EC_BU_Steering "Backup for steering ecu configuration";
CM_ SG_ 1021 EC_BU_Powertrain "Backup for Powertrain ecu configuration";
CM_ SG_ 1021 EC_BU_Safety "Backup for Safety ecu configuration";
CM_ SG_ 1022 EC_BU_ECUCfg7_Stat "Backup for ECU Configuration messages status 7";
CM_ SG_ 1022 EC_BU_CBC5A "Backup for CBC ecu configuration 5A";
CM_ SG_ 1022 EC_BU_CBC5B "Backup for CBC ecu configuration 5B";
CM_ SG_ 1022 EC_BU_CBC6 "Backup for CBC ecu configuration 6";
CM_ SG_ 1023 EC_BU_ECUCfg8_Stat "Backup for ECU Configuration messages status 8";
CM_ SG_ 1023 EC_BU_CBC7A "Backup for CBC ecu configuration 7A";
CM_ SG_ 1023 EC_BU_CBC7B "Backup for CBC ecu configuration 7B";
CM_ SG_ 1023 EC_BU_CBC8 "Backup for CBC ecu configuration 8";
CM_ SG_ 1024 NM_Mode "Network management mode";
CM_ SG_ 1024 NM_Successor "Network management logical successor";
CM_ SG_ 1024 NM_Ud_Launch "Network management userdata launch type";
CM_ SG_ 1024 NM_Sleep_Ack "Network management sleep acknowledge; True = [1]";
CM_ SG_ 1024 NM_Sleep_Ind "Network management sleep indication; True = [1]";
CM_ SG_ 1024 Nw_Id "Network identification no.";
CM_ SG_ 1025 NM_Mode "Network management mode";
CM_ SG_ 1025 NM_Successor "Network management logical successor";
CM_ SG_ 1025 NM_Ud_Launch "Network management userdata launch type";
CM_ SG_ 1025 NM_Sleep_Ack "Network management sleep acknowledge; True = [1]";
CM_ SG_ 1025 NM_Sleep_Ind "Network management sleep indication; True = [1]";
CM_ SG_ 1025 Nw_Id "Network identification no.";
CM_ SG_ 1026 NM_Mode "Network management mode";
CM_ SG_ 1026 NM_Successor "Network management logical successor";
CM_ SG_ 1026 NM_Ud_Launch "Network management userdata launch type";
CM_ SG_ 1026 NM_Sleep_Ack "Network management sleep acknowledge; True = [1]";
CM_ SG_ 1026 NM_Sleep_Ind "Network management sleep indication; True = [1]";
CM_ SG_ 1026 Nw_Id "Network identification no.";
CM_ SG_ 1031 NM_Mode "Network management mode";
CM_ SG_ 1031 NM_Successor "Network management logical successor";
CM_ SG_ 1031 NM_Ud_Launch "Network management userdata launch type";
CM_ SG_ 1031 NM_Sleep_Ack "Network management sleep acknowledge; True = [1]";
CM_ SG_ 1031 NM_Sleep_Ind "Network management sleep indication; True = [1]";
CM_ SG_ 1031 Nw_Id "Network identification no.";
CM_ SG_ 1033 NM_Mode "Network management mode";
CM_ SG_ 1033 NM_Successor "Network management logical successor";
CM_ SG_ 1033 NM_Ud_Launch "Network management userdata launch type";
CM_ SG_ 1033 NM_Sleep_Ack "Network management sleep acknowledge; True = [1]";
CM_ SG_ 1033 NM_Sleep_Ind "Network management sleep indication; True = [1]";
CM_ SG_ 1033 Nw_Id "Network identification no.";
CM_ SG_ 1059 NM_Mode "Network management mode";
CM_ SG_ 1059 NM_Successor "Network management logical successor";
CM_ SG_ 1059 NM_Ud_Launch "Network management userdata launch type";
CM_ SG_ 1059 NM_Sleep_Ack "Network management sleep acknowledge; True = [1]";
CM_ SG_ 1059 NM_Sleep_Ind "Network management sleep indication; True = [1]";
CM_ SG_ 1059 Nw_Id "Network identification no.";
CM_ SG_ 1089 DG_RQ_GLOBAL_UDS "Diagnostic-Request";
CM_ SG_ 1098 VC_VehCfg5_Stat "Configuration messages status 5";
CM_ SG_ 1098 VC_LUCI_PRSNT "Luci feature present; present = [1]";
CM_ SG_ 1098 VC_RR_DuallyPrsnt "Vehicle is equipped with rear duals; present = [1]";
CM_ SG_ 1098 VC_NonReg_TPIS "Non-regulated tire pressure indicator system; True = 1";
CM_ SG_ 1098 VC_WTS_Prsnt "Wait to start feature is present; present = [1]";
CM_ SG_ 1098 VC_AmbTempLct "Ambient temperature sensor location";
CM_ SG_ 1098 VC_Strng_Rt_0 "Steering Ratio at zero";
CM_ SG_ 1098 VC_Strng_Rt_pls1 "Steering Ratio at positve angle 1";
CM_ SG_ 1098 VC_Strng_Rt_pls2 "Steering Ratio at positve angle 2";
CM_ SG_ 1098 VC_Strng_Rt_pls3 "Steering Ratio at positve angle 3";
CM_ SG_ 1098 VC_Strng_Rt_pls4 "Steering Ratio at positve angle 4";
CM_ SG_ 1098 VC_Strng_Rt_pls5 "Steering Ratio at positve angle 5";
CM_ SG_ 1098 VC_RearDoorLocks2DCM "Rear door lock switch present; present = [1]";
CM_ SG_ 1098 VC_SpdLmt_PRSNT "Speed limiter is present; present = [1]";
CM_ SG_ 1098 VC_SBR_Prsnt "Seat belt reminder module is present; True = 1";
CM_ SG_ 1098 VC_ChildDisp_Prsnt "Child display feature is present; True = 1";
CM_ SG_ 1098 VC_OffRoadPg "Off road pages present; True = [1]";
CM_ SG_ 1098 VC_AmbLtgPrsnt "Ambient lighting feature is present; True = [1]";
CM_ SG_ 1098 VC_PPPA_Prsnt "Semi automatic parking system present; present = [1]";
CM_ SG_ 1098 VC_ParkStopPrsnt "Park with stop is present; True = 1";
CM_ SG_ 1099 VC_BU_VehCfg5_Stat "Backup for Configuration messages status 5";
CM_ SG_ 1099 VC_BU_LUCI_PRSNT "Backup for Luci feature present; present = [1]";
CM_ SG_ 1099 VC_BU_RR_DuallyPrsnt "Backup for vehicle is equipped with rear duals; present = [1]";
CM_ SG_ 1099 VC_BU_NonReg_TPIS "Backup for non-regulated tire pressure indicator system; True = 1";
CM_ SG_ 1099 VC_BU_WTS_Prsnt "Backup for wait to start feature is present; present = [1]";
CM_ SG_ 1099 VC_BU_AmbTempLct "Backup for ambient temperature sensor location";
CM_ SG_ 1099 VC_BU_Strng_Rt_0 "Backup for Steering Ratio at zero";
CM_ SG_ 1099 VC_BU_Strng_Rt_pls1 "Backup for Steering Ratio at positve angle 1";
CM_ SG_ 1099 VC_BU_Strng_Rt_pls2 "Backup for Steering Ratio at positve angle 2";
CM_ SG_ 1099 VC_BU_Strng_Rt_pls3 "Backup for Steering Ratio at positve angle 3";
CM_ SG_ 1099 VC_BU_Strng_Rt_pls4 "Backup for Steering Ratio at positve angle 4";
CM_ SG_ 1099 VC_BU_Strng_Rt_pls5 "Backup for Steering Ratio at positve angle 5";
CM_ SG_ 1099 VC_BU_RearDoorLocks2DCM "Backup for Rear door lock switch present; present = [1]";
CM_ SG_ 1099 VC_BU_SpdLmt_PRSNT "Backup for Speed limiter is present; present = [1]";
CM_ SG_ 1099 VC_BU_SBR_Prsnt "Backup for seat belt reminder module is present; True = 1";
CM_ SG_ 1099 VC_BU_ChildDisp_Prsnt "Backup for child display feature is present; True = 1";
CM_ SG_ 1099 VC_BU_OffRoadPg "Backup for off road pages present; True = [1]";
CM_ SG_ 1099 VC_BU_AmbLtgPrsnt "Backup for ambient lighting feature is present; True = 1";
CM_ SG_ 1099 VC_BU_PPPA_Prsnt "Backup for semi automatic parking system present; True = 1";
CM_ SG_ 1099 VC_BU_ParkStopPrsnt "Backup for park with stop is present; True = 1";
CM_ SG_ 1100 VC_VehCfg6_Stat "Configuration messages status 6";
CM_ SG_ 1100 VC_AnlgDrSnsr "Analog door sensor configuration";
CM_ SG_ 1100 VC_BrkTyp "Brake type configuration (M156/7)";
CM_ SG_ 1100 VC_AQS_Prsnt "Air quality sensor present; present = [1]";
CM_ SG_ 1100 VC_Strng_Rt_Mns1 "Steering Ratio at negative angle 1";
CM_ SG_ 1100 VC_Strng_Rt_Mns2 "Steering Ratio at negative angle 2";
CM_ SG_ 1100 VC_Strng_Rt_Mns3 "Steering Ratio at negative angle 3";
CM_ SG_ 1100 VC_Strng_Rt_Mns4 "Steering Ratio at negative angle 4";
CM_ SG_ 1100 VC_Strng_Rt_Mns5 "Steering Ratio at negative angle 5";
CM_ SG_ 1100 VC_TireCircumfFT "Dynamic tire circumference - front only";
CM_ SG_ 1101 VC_BU_VehCfg6_Stat "Backup for Configuration messages status 6";
CM_ SG_ 1101 VC_BU_AnlgDrSnsr "Analog door sensor configuration backup";
CM_ SG_ 1101 VC_BU_BrkTyp "Backup for brake type configuration (M156/7)";
CM_ SG_ 1101 VC_BU_AQS_Prsnt "Backup for air quality sensor present; present = [1]";
CM_ SG_ 1101 VC_BU_Strng_Rt_Mns1 "Backup for Steering Ratio at negative angle 1";
CM_ SG_ 1101 VC_BU_Strng_Rt_Mns2 "Backup for Steering Ratio at negative angle 2";
CM_ SG_ 1101 VC_BU_Strng_Rt_Mns3 "Backup for Steering Ratio at negative angle 3";
CM_ SG_ 1101 VC_BU_Strng_Rt_Mns4 "Backup for Steering Ratio at negative angle 4";
CM_ SG_ 1101 VC_BU_Strng_Rt_Mns5 "Backup for Steering Ratio at negative angle 5";
CM_ SG_ 1101 VC_BU_TireCircumfFT "Backup for Dynamic tire circumference - front only";
CM_ SG_ 1216 D_RS_RF_HUB "Diagnostic-Response";
CM_ SG_ 1218 D_RS_IC "Diagnostic-Response";
CM_ SG_ 1220 D_RS_ORC "Diagnostic-Response";
CM_ SG_ 1223 D_RS_ESC "Diagnostic-Response";
CM_ SG_ 1225 D_RS_ESM "Diagnostic-Response";
CM_ SG_ 1235 D_RS_DASM "Diagnostic-Response";
CM_ SG_ 1250 D_RS_PTS "Diagnostic-Response";
CM_ SG_ 1251 D_RS_SCCM "Diagnostic-Response";
CM_ SG_ 1284 D_RS_CBC "Diagnostic-Response";
CM_ SG_ 1408 ECU_APPL_RF_HUB "ECU to External Application";
CM_ SG_ 1409 ECU_APPL_CBC "ECU to External Application";
CM_ SG_ 1410 ECU_APPL_IC "ECU to External Application";
CM_ SG_ 1412 ECU_APPL_ORC "ECU to External Application";
CM_ SG_ 1415 ECU_APPL_ESC "ECU to External Application";
CM_ SG_ 1417 ECU_APPL_ESM "ECU to External Application";
CM_ SG_ 1427 ECU_APPL_DASM "ECU to External Application";
CM_ SG_ 1442 ECU_APPL_PTS "ECU to External Application";
CM_ SG_ 1443 ECU_APPL_SCCM "ECU to External Application";
CM_ SG_ 1464 ECU_APPL_ECM "ECU to External Application";
CM_ SG_ 1465 ECU_APPL_TCM "ECU to External Application";
CM_ SG_ 1536 SD_RS_RF_HUB "Response on Event - light";
CM_ SG_ 1537 SD_RS_CBC "Response on Event - light";
CM_ SG_ 1538 SD_RS_IC "Response on Event - light";
CM_ SG_ 1540 SD_RS_ORC "Response on Event - light";
CM_ SG_ 1543 SD_RS_ESC "Response on Event - light";
CM_ SG_ 1545 SD_RS_ESM "Response on Event - light";
CM_ SG_ 1555 SD_RS_DASM "Response on Event - light";
CM_ SG_ 1568 D_RQ_CBC "Diagnostic-Request";
CM_ SG_ 1570 SD_RS_PTS "Response on Event - light";
CM_ SG_ 1571 SD_RS_SCCM "Response on Event - light";
CM_ SG_ 1592 SD_RS_ECM "Response on Event - light";
CM_ SG_ 1593 SD_RS_TCM "Response on Event - light";
CM_ SG_ 1728 APPL_ECU_RF_HUB "External Application to ECU";
CM_ SG_ 1729 APPL_ECU_CBC "External Application to ECU";
CM_ SG_ 1730 APPL_ECU_IC "External Application to ECU";
CM_ SG_ 1732 APPL_ECU_ORC "External Application to ECU";
CM_ SG_ 1735 APPL_ECU_ESC "External Application to ECU";
CM_ SG_ 1737 APPL_ECU_ESM "External Application to ECU";
CM_ SG_ 1747 APPL_ECU_DASM "External Application to ECU";
CM_ SG_ 1762 APPL_ECU_PTS "External Application to ECU";
CM_ SG_ 1763 APPL_ECU_SCCM "External Application to ECU";
CM_ SG_ 1784 APPL_ECU_ECM "External Application to ECU";
CM_ SG_ 1785 APPL_ECU_TCM "External Application to ECU";
CM_ SG_ 1856 D_RQ_RF_HUB "Diagnostic-Request";
CM_ SG_ 1858 D_RQ_IC "Diagnostic-Request";
CM_ SG_ 1860 D_RQ_ORC "Diagnostic-Request";
CM_ SG_ 1863 D_RQ_ESC "Diagnostic-Request";
CM_ SG_ 1865 D_RQ_ESM "Diagnostic-Request";
CM_ SG_ 1875 D_RQ_DASM "Diagnostic-Request";
CM_ SG_ 1890 D_RQ_PTS "Diagnostic-Request";
CM_ SG_ 1891 D_RQ_SCCM "Diagnostic-Request";
CM_ SG_ 2015 DG_RQ_GLOBAL "Diagnostic-Request";
CM_ SG_ 2016 D_RQ_ECM "Diagnostic-Request";
CM_ SG_ 2017 D_RQ_TCM "Diagnostic-Request";
CM_ SG_ 2024 D_RS_ECM "Diagnostic-Response";
CM_ SG_ 2025 D_RS_TCM "Diagnostic-Response";
CM_ SG_ 362 CRC_DTCM_A2 "CRC-checksum byte 1 to 7 according to SAE J1850";
CM_ SG_ 362 DrvLnMinTrqMd "Drive line engine torque request: min.-mode";
CM_ SG_ 362 DrvLnTrqRq "Drive line requested engine torque";
CM_ SG_ 362 MC_DTCM_A2 "Message counter";
CM_ SG_ 640 Mem_D_Pos_Rq "Memory driver - position request";
CM_ SG_ 640 Mem_D_Rc_Rq "Memory driver - recall position";
CM_ SG_ 640 Mem_D_Sv_Rq "Memory driver - save position";
CM_ SG_ 752 MEM_RC_STAT "Memory recall status";
CM_ SG_ 752 MSMD_PDL_LKOUT "Adjustable pedal lockout";
CM_ SG_ 752 EASY_EXIT "Easy exit seat state";
CM_ SG_ 752 RKE_MEM "Remote linked to memory; [0] = NO, [1] = YES";
CM_ SG_ 847 RF_FobNum "FOB number making the request";
CM_ SG_ 847 RFMemRq "RF memory request; [1] = True";
CM_ SG_ 916 AudioMuteRq "Audio mute request; Audio mute = [1]";
CM_ SG_ 916 FtWigWagRq "Front wig wag request";
CM_ SG_ 916 RrWigWagRq "Rear wig wag request";
CM_ SG_ 916 SupHrnRq "Suppress horn request";
CM_ SG_ 916 SprtRearLtg "Separate rear lighting";
CM_ SG_ 916 R_AC_Enable "Rear A/C enable request; On = [1]";
CM_ SG_ 916 DsblTurnLmpFlt "Disable rear turn lamp fault";
CM_ SG_ 916 DoorUnlkAllRq "Request to unlock all doors; No request active = 0, Request active = 1";
CM_ SG_ 916 DoorLkAllRq "Request to lock all doors; No request active = 0, Request active = 1";
CM_ SG_ 1227 D_RS_DTCM "Diagnostic-Response";
CM_ SG_ 1265 D_RS_VSIM "Diagnostic-Response";
CM_ SG_ 1419 ECU_APPL_DTCM "ECU to External Application";
CM_ SG_ 1457 ECU_APPL_VSIM "ECU to External Application";
CM_ SG_ 1547 SD_RS_DTCM "Response on Event - light";
CM_ SG_ 1585 SD_RS_VSIM "Response on Event - light";
CM_ SG_ 1739 APPL_ECU_DTCM "External Application to ECU";
CM_ SG_ 1777 APPL_ECU_VSIM "External Application to ECU";
CM_ SG_ 1867 D_RQ_DTCM "Diagnostic-Request";
CM_ SG_ 1905 D_RQ_VSIM "Diagnostic-Request";
CM_ SG_ 806 AFLS_ENBL "Advanced lighting enabled; [0] = no, [1] = yes";
CM_ SG_ 806 AFLS_Stat "AFLS fault status";
CM_ SG_ 1256 D_RS_AFLS "Diagnostic-Response";
CM_ SG_ 1448 ECU_APPL_AFLS "ECU to External Application";
CM_ SG_ 1768 APPL_ECU_AFLS "External Application to ECU";
CM_ SG_ 1896 D_RQ_AFLS "Diagnostic-Request";
CM_ SG_ 530 Adblue_FL_LVL "Adblue fluid level";
CM_ SG_ 530 Adblue_Stat "Adblue status";
CM_ SG_ 530 AdblueRemainDist "Adblue remaining distance";
CM_ SG_ 530 DEF_LOW "DEF Low Indicator request";
CM_ SG_ 530 ECM_HMI_Timer_RQ "DEF and DPF warning re-launch timer request";
CM_ SG_ 530 EngChmRq "Engine chime request";
CM_ SG_ 530 PFW_Stat "Particulate filter warning status";
CM_ SG_ 530 PrcntCplt "Percent complete";
CM_ SG_ 530 PreHtIndLmp_On_Rq "Request glow-plug (wait to start) lamp";
CM_ SG_ 530 PTC_REL1_RQ "Activate PTC Relay # 1 (diesel only)";
CM_ SG_ 530 PTC_REL2_RQ "Activate PTC Relay # 2 (diesel only)";
CM_ SG_ 530 PTC_REL3_RQ "Activate PTC Relay # 3 (diesel only)";
CM_ SG_ 530 RemainDistUnt "Adblue distance counter unit; miles = [0], km = [1]";
CM_ SG_ 530 WtrFuelIndLmp_On_Rq "Request water in fuel lamp (diesel only)";
CM_ SG_ 625 DsrSpeed_KPH "Desired speed in kilometers per hour";
CM_ SG_ 625 FCWSetting "Forward collision warning sensitivity setting";
CM_ SG_ 625 FCWState "FCW system operating state; On = [1]";
CM_ SG_ 671 CRC_29Fh "CRC-checksum byte 1 to 7 according to SAE J1850";
CM_ SG_ 671 MC_29Fh "Message counter";
CM_ SG_ 684 INV_CARGO_OnState "01 =cargo outlet is disabledt, 10 = cargo outlet is enabled";
CM_ SG_ 684 SM_Rear_Guidance_Lgt "Side Mirror Rear Guidance Light On/ Off , ON = 1";
CM_ SG_ 684 Snow_Plow_Presence "Snowplow is present; True = [1]";
CM_ SG_ 684 RR_DR_UNLKD "Rear door hatch / lift gate is unlocked";
CM_ SG_ 705 VEH_INT_TEMP "Vehicle interior temperature";
CM_ SG_ 705 SwayBarBtnRq "Sway bar disconnect switch request";
CM_ SG_ 709 EC_AudTel3B "Audio and telematics ecu configuration 3B";
CM_ SG_ 709 EC_ECUCfg16_Stat "ECU Configuration messages status 16";
CM_ SG_ 709 EC_AudTel3A "Audio and telematics ecu configuration 3A";
CM_ SG_ 710 EC_ECUCfg17_Stat "ECU Configuration messages status 17";
CM_ SG_ 710 EC_PTS "Park assist ecu configuration";
CM_ SG_ 710 EC_SeatsB "Heated seats ecu configuration - B";
CM_ SG_ 710 EC_SeatsA "Heated seats ecu configuration - A";
CM_ SG_ 710 EC_HVAC2 "HVAC ECU Configurations - 2";
CM_ SG_ 710 EC_HVAC1 "HVAC ECU Configurations - 1";
CM_ SG_ 710 EC_CBC17 "CBC ECU Config 17";
CM_ SG_ 714 EC_BU_AudTel3B "Backup for audio and telematics ecu configuration 3B";
CM_ SG_ 714 EC_BU_ECUCfg16_Stat "Backup for ECU Configuration messages status 16";
CM_ SG_ 714 EC_BU_AudTel3A "Backup for audio and telematics ecu configuration 3A";
CM_ SG_ 715 EC_BU_ECUCfg17_Stat "Backup for ECU Configuration messages status 17";
CM_ SG_ 715 EC_BU_PTS "Backup for park assist ecu configuration";
CM_ SG_ 715 EC_BU_SeatsB "Backup for heated seats ecu configuration";
CM_ SG_ 715 EC_BU_SeatsA "Backup for heated seats ecu configuration";
CM_ SG_ 715 EC_BU_HVAC2 "Backup for HVAC ECU Configurations - 2";
CM_ SG_ 715 EC_BU_HVAC1 "Backup for HVAC ECU Configurations - 1";
CM_ SG_ 715 EC_BU_CBC17 "CBC ECU Config 17 Backup";
CM_ SG_ 773 Tire_FL "Tire front left";
CM_ SG_ 773 Tire_FR "Tire front right";
CM_ SG_ 773 Tire_RL "Tire rear left";
CM_ SG_ 773 Tire_RR "Tire rear right";
CM_ SG_ 773 Tire_Spr "Spare tire";
CM_ SG_ 773 TirePrssFL "Tire pressure front left";
CM_ SG_ 773 TirePrssFR "Tire pressure front right";
CM_ SG_ 773 TirePrssRL "Tire pressure rear left";
CM_ SG_ 773 TirePrssRR "Tire pressure rear right";
CM_ SG_ 773 TirePrssSpr "Tire pressure spare tire";
CM_ SG_ 773 TPM_ChimeRq "TPM chime request";
CM_ SG_ 773 TPM_IndLmpOnRq "Tire pressure indication request";
CM_ SG_ 773 TPM_SysStat "TPM system localization status";
CM_ SG_ 773 TPMHornChirp "TPM horn chirp";
CM_ SG_ 773 TPMHazardFlash "TPM hazard flash;  true = [1]";
CM_ SG_ 778 TrboBstPress "Turbo boost pressure";
CM_ SG_ 778 EngBrkStat "Engine braking status";
CM_ SG_ 778 WTS_CntDnTmr "Wait to start count down timer (sec)";
CM_ SG_ 778 Man_PFW_Stat "Manual Regen Particulate filter warning status";
CM_ SG_ 778 IdleShutDwnAppl "Idle Shut down applied";
CM_ SG_ 778 EngDerate "Engine derate mode";
CM_ SG_ 778 EB_Stat3 "Exhaust brake status - 3 bit";
CM_ SG_ 778 EB_Pwr "Exhaust brake Power";
CM_ SG_ 778 EB_ACC_AVLBL "If the ACC is engaged, exhaust brake can be used to decelerate the vehicle;1='In Range'";
CM_ SG_ 778 DPF_Man_Stat "Manual Regeneration status";
CM_ SG_ 778 SRV_AIR_FLTR "Service air Filter";
CM_ SG_ 778 SRV_CCV_FLTR "Service CCV Filter";
CM_ SG_ 778 DrtdTrqMd "Derated torque mode";
CM_ SG_ 778 Rapid_Cabin_Warmup_Stat "EB is aiding in cabin warmup.  TRUE = [1].";
CM_ SG_ 831 FL_Lvl_Adj "Front left level adjust (1=adjusting)";
CM_ SG_ 831 FR_Lvl_Adj "Front right level adjust (1=adjusting)";
CM_ SG_ 831 LvlCalCmplt "Level calibration complete";
CM_ SG_ 831 RL_Lvl "Rear left level";
CM_ SG_ 831 RL_Lvl_Adj "Rear left level adjust (1=adjusting)";
CM_ SG_ 831 RR_Lvl "Rear right level";
CM_ SG_ 831 RR_Lvl_Adj "Rear right level adjust (1=adjusting)";
CM_ SG_ 844 ASCM_Exit_Rq "Request for exit (Trailer_ HD) indicator";
CM_ SG_ 844 ASCM_HMI_Stat "ASCM HMI status";
CM_ SG_ 844 ASCM_Srv "Service air suspension; 1 = True";
CM_ SG_ 844 ASCM_Stat "Air suspension status";
CM_ SG_ 844 ASCM_StatDisp "Air suspension status for display";
CM_ SG_ 844 ASCM_SysFail "Loss of function - system fault; 1 = True";
CM_ SG_ 844 ASCM_TJM "Tire jack mode; 1 = True";
CM_ SG_ 844 ASCM_WarnOnly "ASCM warning messages only; 1 = True";
CM_ SG_ 844 Loading_Lv "Loading level";
CM_ SG_ 844 LvlAdjStat "Level adjustment status";
CM_ SG_ 844 Tgt_Level "Target Level";
CM_ SG_ 844 TM_Enbl "Transport mode enabled; 1 = True";
CM_ SG_ 844 WAL_Enbl "Wheel alignment level enabled; 1 = True";
CM_ SG_ 1062 NM_Mode "Network management mode";
CM_ SG_ 1062 NM_Successor "Network management logical successor";
CM_ SG_ 1062 NM_Ud_Launch "Network management userdata launch type";
CM_ SG_ 1062 NM_Sleep_Ack "Network management sleep acknowledge; True = [1]";
CM_ SG_ 1062 NM_Sleep_Ind "Network management sleep indication; True = [1]";
CM_ SG_ 1062 Nw_Id "Network identification no.";
CM_ SG_ 1254 D_RS_ASCM "Diagnostic-Response";
CM_ SG_ 1446 ECU_APPL_ASCM "ECU to External Application";
CM_ SG_ 1574 SD_RS_ASCM "Response on Event - light";
CM_ SG_ 1576 SD_RS_AFLS "Response on Event - light";
CM_ SG_ 1766 APPL_ECU_ASCM "External Application to ECU";
CM_ SG_ 1894 D_RQ_ASCM "Diagnostic-Request";
CM_ SG_ 294 LatAcceleration "Raw lateral acceleration";
CM_ SG_ 294 AXSStat "Longitudinal signal status";
CM_ SG_ 294 AYSStat "Latitudinal signal status";
CM_ SG_ 294 LongAcceleration "Raw longitudinal acceleration";
CM_ SG_ 294 YRSStat "Yaw rate signal status";
CM_ SG_ 294 InternalError "ORC ESC internal error; True = [1]";
CM_ SG_ 294 VoltageError "ORC ESC voltage error; True = [1]";
CM_ SG_ 294 YawRate "Raw yaw acceleration";
CM_ SG_ 294 MC_ORC_YRS_DATA "Message counter";
CM_ SG_ 294 CRC_ORC_YRS_DATA "CRC-checksum byte 1 to 7 according to SAE J1850";
CM_ SG_ 516 ControlEncodingRsp "Control encoding - response";
CM_ SG_ 516 MKKey1org21 "Mini kript key 1 or G2_1";
CM_ SG_ 516 MKKey2org22 "Mini kript key 2 or G2_2";
CM_ SG_ 516 MKKey_3 "Mini kript key 3";
CM_ SG_ 516 MKKey_4 "Mini kript key 4";
CM_ SG_ 516 MKKey_5 "Mini kript key 5";
CM_ SG_ 516 MKKey_6 "Mini kript key 6";
CM_ SG_ 517 ControlEncodingRq "Control encoding - request";
CM_ SG_ 517 rnd_1 "Random number 1";
CM_ SG_ 517 rnd_2 "Random number 2";
CM_ SG_ 517 rnd_3 "Random number 3";
CM_ SG_ 517 rnd_4 "Random number 4";
CM_ SG_ 517 f1_1 "F code 1_1";
CM_ SG_ 517 f1_2 "F code 1_2";
CM_ SG_ 524 ControlEncodingBCM "Fob authentication or presence query";
CM_ SG_ 524 MiniCryptFCode "MiniCrypt 'F' code output";
CM_ SG_ 524 MiniCrypt_Rnd "MiniCrypt input random number";
CM_ SG_ 524 TxpReadRequest "Transponder reading request; Request = [0]";
CM_ SG_ 524 TxpAuthRequest "Transponder authentication request; Request = [0]";
CM_ SG_ 525 MinicryptReceptionSts "Acknowledge message reception; Received = [1]";
CM_ SG_ 526 MiniCryptGCode "MiniCrypt 'G' code output";
CM_ SG_ 526 ControlEncoding "Response type UC/TEN/PVA";
CM_ SG_ 526 CodeCheckSts "Code check status";
CM_ SG_ 526 ProgrammedSts "TRM programmed status; Programmed = [1]";
CM_ SG_ 526 TxpID "Transponder authentication";
CM_ SG_ 526 TxpFound "Transponder found; Absent = [1]";
CM_ SG_ 527 FrameNumber "MiniCrypt key frame number";
CM_ SG_ 527 TotalFrameNumber "MiniCrypt key total number of frames";
CM_ SG_ 527 DATA1 "MiniCrypt key data byte 1";
CM_ SG_ 527 DATA2 "MiniCrypt key data byte 2";
CM_ SG_ 527 DATA3 "MiniCrypt key data byte 3";
CM_ SG_ 527 DATA4 "MiniCrypt key data byte 4";
CM_ SG_ 527 DATA5 "MiniCrypt key data byte 5";
CM_ SG_ 527 DATA6 "MiniCrypt key data byte 6";
CM_ SG_ 527 DATA7 "MiniCrypt key data byte 7";
CM_ SG_ 542 BlockOffset "Part number block offset";
CM_ SG_ 542 PTRInfo "Part number PTR information";
CM_ SG_ 542 CLUType "Part number CLU type";
CM_ SG_ 542 Character5 "Part number character 5";
CM_ SG_ 542 Character4 "Part number character 4";
CM_ SG_ 542 Character3 "Part number character 3";
CM_ SG_ 542 Character2 "Part number character 2";
CM_ SG_ 542 Character1 "Part number character 1";
CM_ SG_ 542 Character0 "Part number character 0";
CM_ SG_ 669 MC_EPB_A1 "Message counter";
CM_ SG_ 669 CRC_EPB_A1 "CRC-checksum byte 1 to 2 according to SAE J1850";
CM_ SG_ 770 MC_EPB_1 "Message counter";
CM_ SG_ 770 CRC_EPB_1 "CRC-checksum byte 1 to 7 according to SAE J1850";
CM_ SG_ 782 Gas_Range "Gas range or DTE";
CM_ SG_ 782 EngHour "Total Engine Hours";
CM_ SG_ 782 CFG_Manual_DPF "Manual DPF initiation by driver";
CM_ SG_ 938 A_MPG "Trip A Combined fuel economy in US MPG";
CM_ SG_ 939 A_KMpL "Trip A Combined fuel economy in Km/L";
CM_ SG_ 940 A_Total_Dist_Miles "Trip A total distance in US miles";
CM_ SG_ 940 A_Total_Dist_Kilometers "Trip A total distance in kilometers";
CM_ SG_ 941 B_MPG "Trip B Combined fuel economy in US MPG";
CM_ SG_ 942 B_KMpL "Trip B Combined fuel economy in Km/L";
CM_ SG_ 943 B_Total_Dist_Miles "Trip B total distance in US miles";
CM_ SG_ 943 B_Total_Dist_Kilometers "Trip B total distance in kilometers";
CM_ SG_ 55 CRC_TCM_EngTrq2_2 "CRC-checksum byte 1 to 7 according to SAE J1850";
CM_ SG_ 55 EngTrqRq_2 "Requested engine torque";
CM_ SG_ 55 MaxTrqDes_2 "Maximum engine torque desired";
CM_ SG_ 55 MC_TCM_EngTrq2_2 "Message counter";
CM_ SG_ 55 TrnsTrqReqSlow_2 "Slow path desired engine torque request from the trans";
CM_ SG_ 55 TrqCtrlModeRq_2 "Torque control mode request";
CM_ SG_ 1073 NM_Mode "Network management mode";
CM_ SG_ 1073 NM_Successor "Network management logical successor";
CM_ SG_ 1073 NM_Ud_Launch "Network management userdata launch type";
CM_ SG_ 1073 NM_Sleep_Ack "Network management sleep acknowledge; True = [1]";
CM_ SG_ 1073 NM_Sleep_Ind "Network management sleep indication; True = [1]";
CM_ SG_ 1073 Nw_Id "Network identification no.";
CM_ SG_ 973 WATER_IN_FUEL_STAT "Water in fuel indicator status";
CM_ SG_ 973 TIRE_PRESSURE_STAT "Tire pressure indicator status";
CM_ SG_ 973 STOP_START_STAT "Stop start indicator status";
CM_ SG_ 973 SERVICE_STAT "Service indicator status";
CM_ SG_ 973 SERVICE_ACC_STAT "Service ACC indicator status";
CM_ SG_ 973 OVER_TEMP_STAT "Over temperature indicator status";
CM_ SG_ 973 OIL_TEMP_STAT "Oil temperature indicator status";
CM_ SG_ 973 OIL_PRESSURE_STAT "Oil pressure indicator status";
CM_ SG_ 973 LANE_SENSE_STAT "Lane sense indicator status";
CM_ SG_ 973 FOUR_WD_SERVICE_STAT "Service indicator status";
CM_ SG_ 973 FCW_SYSTEM_STAT "FCW system indicator status";
CM_ SG_ 973 ETC_CONTROL_STAT "ETC control indicator status";
CM_ SG_ 973 EPS_STAT "EPS indicator status";
CM_ SG_ 973 EPB_WARN_STAT "EPB warn indicator status";
CM_ SG_ 973 ENGINE_TEMP_STAT "Engine temperature indicator status";
CM_ SG_ 973 ENGINE_MIL_STAT "Engine MIL indicator status";
CM_ SG_ 973 ELEC_STAB_STAT "Electronic stability indicator status";
CM_ SG_ 973 DEF_STAT "DEF indicator status";
CM_ SG_ 973 DAMPING_SYSTEM_STAT "Damping system indicator status";
CM_ SG_ 973 BRK_IND_STAT "Brake indicator status";
CM_ SG_ 973 BRAKE_PAD_STAT "Brake pad indicator status";
CM_ SG_ 973 BATTERY_CHARGE_STAT "Battery charge indicator status";
CM_ SG_ 973 AWD_SERVICE_STAT "AWD service indicator status";
CM_ SG_ 973 ABS_IND_STAT "ABS indicator status";
CM_ SG_ 973 WINDSHIELD_FLUID_STAT "Windshield Water Fluid";
CM_ SG_ 973 OIL_LEVEL_STAT "Oil Level";
CM_ SG_ 973 FUEL_CAP_STAT "Fuel Cap Unfastened";
CM_ SG_ 973 COOLENT_LEVEL_STAT "Low Coolent Level";
CM_ SG_ 973 TORQUE_STAT "Torque Limited";
CM_ SG_ 973 ELECTRIC_WRENCH_STAT "Electric Wrench";
CM_ SG_ 973 CATALYST_TEMP_STAT "Catalyst Overtemp";
CM_ SG_ 754 Inst_Fuel_Econ "Instantaneous fuel economy";
CM_ SG_ 754 Avg_Fuel_Econ "Average fuel economy";
CM_ SG_ 910 IBS3_TempFailStatus "Failure of ASIC Temperature meas. (internal defect)";
CM_ SG_ 910 IBS3_T_BATT "Battery temperature";
CM_ SG_ 910 IBS3_SOH_Q_Accuracy "SOH_Q accuracy status";
CM_ SG_ 910 IBS3_SOH_Q "State of health related to capacity (energy)";
CM_ SG_ 910 IBS3_SOF_VC "Predicted initial battery voltage dip during cranking (old CG spec)";
CM_ SG_ 910 IBS3_SOF_V_Accuracy "SOF_V accuracy; Data reliable = [0], unreliable = [1]";
CM_ SG_ 910 IBS3_SOF_Q_Accuracy "SOF_Q accuracy status";
CM_ SG_ 910 IBS3_SOF_Q "Residual battery charge in Ah";
CM_ SG_ 910 IBS3_SOC_Accuracy "SOC accuracy status";
CM_ SG_ 910 IBS3_SOC "State of charge";
CM_ SG_ 910 IBS3_FLAG_DISCONNECT "Battery disconnection flag";
CM_ SG_ 910 Ft_RrAxleLckr_Rq "Front and Rear axle locker request";
CM_ SG_ 579 AxleLckrOFF_SW "Axle locker deactivation switch";
CM_ SG_ 579 TGW_AUD_MD2_CAB_DR "TGW additional audio modes for Cabin/Driver";
CM_ SG_ 579 Phone_Popup_setting_active "Phone call status popup active or not, Active=1";
CM_ SG_ 1151 D_RS_SGW "Diagnostic-Response";
CM_ SG_ 1150 D_RQ_SGW "Diagnostic-Request";
CM_ SG_ 683 VoltBattFailStatus "Failure Status of Voltage meas. (internal defect)";
CM_ SG_ 683 RsErrIBS3 "Response Error IBS; Error=[1]";
CM_ SG_ 683 IBS3_Vbatt "Battery voltage measured at the terminals";
CM_ SG_ 683 IBS3_Ibatt "Battery current";
CM_ SG_ 683 IBS3_Error_Internal "Error in IBS calibration data; No Error = [0], Error = [1]";
CM_ SG_ 683 CurrBattFailStatus "Failure Status of Current meas. (internal defect)";
CM_ SG_ 685 Cfg_Aux_PTO "AUX Switches Configuration";
CM_ SG_ 685 CBC_AUX4_Type "Aux switch 4 behavior; Latching = [0], Momentary = [1]";
CM_ SG_ 685 CBC_AUX4_PWRMD "Aux switch 4 power mode; ignition = [0], battery = [1]";
CM_ SG_ 685 CBC_AUX4_HLEnbl "Aux switch 4 enable holding last state; enabled = [1]";
CM_ SG_ 685 CBC_AUX3_Type "Aux switch 3 behavior; Latching = [0], Momentary = [1]";
CM_ SG_ 685 CBC_AUX3_PWRMD "Aux switch 3 power mode; ignition = [0], battery = [1]";
CM_ SG_ 685 CBC_AUX3_HLEnbl "Aux switch 3 enable holding last state; enabled = [1]";
CM_ SG_ 685 CBC_AUX2_Type "Aux switch 2 behavior; Latching = [0], Momentary = [1]";
CM_ SG_ 685 CBC_AUX2_PWRMD "Aux switch 2 power mode; ignition = [0], battery = [1]";
CM_ SG_ 685 CBC_AUX2_HLEnbl "Aux switch 2 enable holding last state; enabled = [1]";
CM_ SG_ 685 CBC_AUX1_Type "Aux switch 1 behavior; Latching = [0], Momentary = [1]";
CM_ SG_ 685 CBC_AUX1_PWRMD "Aux switch 1 power mode; ignition = [0], battery = [1]";
CM_ SG_ 685 CBC_AUX1_HLEnbl "Aux switch 1 enable holding last state; enabled = [1]";
CM_ SG_ 685 CBC_AUX5_Type "Aux switch 5 behavior; Latching = [0], Momentary = [1]";
CM_ SG_ 685 CBC_AUX5_PWRMD "Aux switch 5 power mode; ignition = [0], battery = [1]";
CM_ SG_ 685 CBC_AUX5_HLEnbl "Aux switch 5 enable holding last state; enabled = [1]";
CM_ SG_ 685 CBC_AUX6_Type "Aux switch 6 behavior; Latching = [0], Momentary = [1]";
CM_ SG_ 685 CBC_AUX6_PWRMD "Aux switch 6 power mode; ignition = [0], battery = [1]";
CM_ SG_ 685 CBC_AUX6_HLEnbl "Aux switch 6 enable holding last state; enabled = [1]";
CM_ SG_ 881 SwayBarEVICDisplay "Sway Bar HMI display request";
CM_ SG_ 881 SwayBar_Sts "Swaybar status";
CM_ SG_ 881 SwayBar_LEDRq "Sway Bar disconnect switch LED request";
CM_ SG_ 739 CNG_GaLvl "CNG gauge level";
CM_ SG_ 739 CNG_LO "CNG is low";
CM_ SG_ 739 EngRunFuelTyp "Engine running fuel type";
CM_ SG_ 570 AUS "Cruise Switch: Cancel Pressed";
CM_ SG_ 570 WA "Cruise Switch: distance / launch mode pressed";
CM_ SG_ 570 S_PLUS_B "Cruise Switch: Resume/Accel Pressed";
CM_ SG_ 570 S_MINUS_B "Cruise Switch: Coast or Set/Decel Pressed";
CM_ SG_ 570 WH_UP "Cruise Switch: Implausible State=1";
CM_ SG_ 570 CRUISE_TGL "Cruise Switch: On/Off  Pressed";
CM_ SG_ 570 ACC_MODE "Cruise Switch: ACC or ESC mode pressed";
CM_ SG_ 570 MC_SCCM_CRS_CTRL "Message counter";
CM_ SG_ 570 CRC_SCCM_CRS_CTRL "CRC-checksum byte 1 to 2 according to SAE J1850";
CM_ SG_ 914 PTO_IdleSpd1 "Power takeoff idle speed 1 selected";
CM_ SG_ 914 PTO_IdleSpd2 "Power takeoff idle speed 2 selected";
CM_ SG_ 914 PTO_IdleSpd3 "Power takeoff idle speed 3 selected";
CM_ SG_ 914 PosEngdSwStat "Positive engagement switch status; On = [1]";
CM_ SG_ 914 MC_VSIM_C1 "Message counter";
CM_ SG_ 914 CRC_VSIM_C1 "CRC-checksum byte 1 to 7 according to SAE J1850";
CM_ SG_ 914 IdleShutDown_Disable "5 Minute Idle shut down feature disabled signal ;True =1";
CM_ SG_ 914 VSIMEngineOffRequest "This signal informs the RF_HUB that VSIM Emergency Stop wire is activated; ACTIVE= 1";
CM_ SG_ 914 J1939_RPM_RQ "Engine RPM requested through J1939";
CM_ SG_ 676 MAP_4_Bar "Engine manifold pressure (4 bar range)";
CM_ SG_ 676 ECM_WARN_EXT "HMI extended warnings";
CM_ SG_ 676 TransWarmup_Min_RPM "Minimal engine rpm request for transmission warm up feature";
CM_ SG_ 676 TransWarmup_Enbl_Rq "Enable and disable flag for transmission warm up feature, 0h = WarmUp_NOT_Enabled 1h = WarmUp_Enabled";
CM_ SG_ 676 MC_ECM_B11 "Message counter";
CM_ SG_ 676 CRC_ECM_B11 "CRC-Checksum Byte 1 - 7 according to SAE J1850";
CM_ SG_ 2047 WAKE_SGW_Signal "This signal is used to wakeup networks";
CM_ SG_ 963 VC_BU_VehCfgCSO3_Stat "Backup for Configuration message CSO3 status";
CM_ SG_ 963 VC_BU_TIRE_FILL_ALERT_CSO "Tire Fill Alert Enable/Disable customer settings menu. 1 - Present";
CM_ SG_ 963 VC_BU_POWER_SIDE_STEP_CSO "Power Side Step Enable/Disable customer settings menu, 1 - Present.";
CM_ SG_ 963 VC_BU_TRAILER_LENGTH_BLIND_SPOT_ "Backup for Trailer Length Blind Spot Enable/Disable customer settings menu. 1 - Present";
CM_ SG_ 963 VC_BU_TSI_CSO "Traffic Sign Information Enable/Disable customer settings menu";
CM_ SG_ 963 VC_BU_TRUNK_UNLOCK_ENABLE_CSO "Trunk Unlock Enable/Disable customer settings menu";
CM_ SG_ 963 VC_BU_SPEED_THRESHOLD_CSO "Vehicle Speed Threshold Enable/Disable customer settings menu";
CM_ SG_ 963 VC_BU_SEIU_RPM_CSO "Back up for SEIU RPM Enable/Disable customer settings menu;Present=1";
CM_ SG_ 963 VC_BU_SEIU_INPUT_WIRE_CSO "Back up fpr SEIU Input Wire Enable/Disable customer settings menu;Present=1";
CM_ SG_ 963 VC_BU_RVC_CVPM_SGRID_CSO "Backup for Rear CVPM Camera Static Gridlines, Present = 1";
CM_ SG_ 963 VC_BU_RVC_CVPM_DGRID_CSO "Backup for Rear CVPM Camera Dynamic Gridlines, Present = 1";
CM_ SG_ 963 VC_BU_RR_CARGO_GUIDE_LGT_CSO "Back up for Rear Cargo Guidance Lights Enable/Disable customer settings menu;Present=1";
CM_ SG_ 963 VC_BU_PEB_CSO "Pedestrian Emergency Brake Enable/Disable customer settings menu";
CM_ SG_ 963 VC_BU_LKA_WARNING_CSO "Lane Keep Assist Warning Mode customer settings menu";
CM_ SG_ 963 VC_BU_LKA_STRN_CSO "Lane Keep Assist Strength customer settings menu";
CM_ SG_ 963 VC_BU_FFC_GRIDLINES_CSO "Backup for Forward Facing Camera Gridlines, Present = 1";
CM_ SG_ 963 VC_BU_EXTERNAL_LIGHT_SENSOR_CSO "External Light Sensor Enable/Disable customer settings menu";
CM_ SG_ 963 VC_BU_BUZZER_VOLUME_LEVEL_CSO "Buzzer Volume Level Enable/Disable customer settings menu";
CM_ SG_ 963 VC_BU_BACKUP_ALARM_CSO "Backup for Back Up Alarm Enable/Disable customer settings menu;Present=1";
CM_ SG_ 963 VC_BU_AUTO_STOP_START_CSO "Auto Stop Start Enable/Disable customer settings menu";
CM_ SG_ 963 VC_BU_AL_OR_PLUS_CSO "BACKUP Auto Launch Off Road Plus customer settings menu";
CM_ SG_ 963 VC_BU_AL_FFC_OR_PLUS_CSO "BACKUP Auto Launch Forward Facing Camera Off Road Plus customer settings menu";
CM_ SG_ 963 VC_BU_TSR_WARNING_MODE_CSO "Backup TSR Warning Mode customer setting menu, Present = 1";
CM_ SG_ 963 VC_BU_RR_PK_LOOSE_SHIP_CSO "Back up for Rear Park Sense Loose Ship Enable/Disable customer settings menu;0 - Absent 1 - Present";
CM_ SG_ 963 VC_BU_HWRSS_CSO "Back up for HWRSS Enable/Disable customer settings menu;Present=1";
CM_ SG_ 963 VC_BU_FT_PK_LOOSE_SHIP_CSO "Back up for Front Park Sense Loose Ship Enable/Disable customer settings menu;0 - Absent 1 - Present";
CM_ SG_ 963 VC_BU_CHMSL_DYN_CNTR_CSO "BACKUP CHMSL Dynamic Centerline Enable/Disable customer settings menu";
CM_ SG_ 963 VC_BU_TSR_WARNING_MODE_OFFSET_CS "Backup TSR Warning Mode Offset customer setting menu, Present = 1";
CM_ SG_ 962 VC_VehCfgCSO3_Stat "Configuration message CSO3 status";
CM_ SG_ 962 VC_TRAILER_LENGTH_BLIND_SPOT_CSO "Trailer Length Blind Spot Enable/Disable customer settings menu. 1 - Present";
CM_ SG_ 962 VC_TIRE_FILL_ALERT_CSO "Tire Fill Alert Enable/Disable customer settings menu";
CM_ SG_ 962 VC_POWER_SIDE_STEP_CSO "Power Side Step Enable/Disable customer settings menu, 1 - Present.";
CM_ SG_ 962 VC_TSI_CSO "Traffic Sign Information Enable/Disable customer settings menu";
CM_ SG_ 962 VC_TRUNK_UNLOCK_ENABLE_CSO "Trunk Unlock Enable/Disable customer settings menu";
CM_ SG_ 962 VC_SPEED_THRESHOLD_CSO "Vehicle Speed Threshold Enable/Disable customer settings menu";
CM_ SG_ 962 VC_SEIU_RPM_CSO "SEIU RPM Enable/Disable customer settings menu,Present =1 ";
CM_ SG_ 962 VC_SEIU_INPUT_WIRE_CSO "SEIU Input Wire Enable/Disable customer settings menu,Present =1 ";
CM_ SG_ 962 VC_RVC_CVPM_SGRID_CSO "Rear CVPM Camera Static Gridlines, Present = 1";
CM_ SG_ 962 VC_RVC_CVPM_DGRID_CSO "Rear CVPM Camera Dynamic Gridlines, Present = 1";
CM_ SG_ 962 VC_RR_CARGO_GUIDE_LGT_CSO "Rear Cargo Guidance Lights Enable/Disable customer settings menu, Present = 1";
CM_ SG_ 962 VC_PEB_CSO "Pedestrian Emergency Brake Enable/Disable customer settings menu";
CM_ SG_ 962 VC_LKA_WARNING_CSO "Lane Keep Assist Warning Mode customer settings menu";
CM_ SG_ 962 VC_LKA_STRN_CSO "Lane Keep Assist Strength customer settings menu";
CM_ SG_ 962 VC_LKA_SENS_CSO "Lane Keep Assist Sensitivity customer settings menu";
CM_ SG_ 962 VC_FFC_GRIDLINES_CSO "Forward Facing Camera Gridlines, Present = 1";
CM_ SG_ 962 VC_EXTERNAL_LIGHT_SENSOR_CSO "External Light Sensor Enable/Disable customer settings menu";
CM_ SG_ 962 VC_BUZZER_VOLUME_LEVEL_CSO "Buzzer Volume Level Enable/Disable customer settings menu";
CM_ SG_ 962 VC_BACKUP_ALARM_CSO "Backup Alarm Enable/Disable customer settings menu, Present = 1";
CM_ SG_ 962 VC_AUTO_STOP_START_CSO "Auto Stop Start Enable/Disable customer settings menu";
CM_ SG_ 962 VC_AL_OR_PLUS_CSO "Auto Launch Off Road Plus customer settings menu";
CM_ SG_ 962 VC_AL_FFC_OR_PLUS_CSO "Auto Launch Forward Facing Camera Off Road Plus customer settings menu";
CM_ SG_ 962 VC_TSR_WARNING_MODE_OFFSET_CSO "TSR Warning Mode Offset customer setting menu, Present = 1";
CM_ SG_ 962 VC_TSR_WARNING_MODE_CSO "TSR Warning Mode customer setting menu, Present = 1";
CM_ SG_ 962 VC_RR_PK_LOOSE_SHIP_CSO "Rear Park Sense Loose Ship Enable/Disable customer settings menu;0 - Absent 1 - Present";
CM_ SG_ 962 VC_HWRSS_CSO "HWRSS Enable/Disable customer settings menu,Present =1";
CM_ SG_ 962 VC_FT_PK_LOOSE_SHIP_CSO "Front Park Sense Loose Ship Enable/Disable customer settings menu;0 - Absent 1 - Present";
CM_ SG_ 962 VC_CHMSL_DYN_CNTR_CSO "CHMSL Dynamic Centerline Enable/Disable customer settings menu";
CM_ SG_ 907 VC_BU_VehCfg8_Stat "Backup for Configuration messages status 8";
CM_ SG_ 907 VC_BU_Steering_Cfactor "Backup for Steering Cfactor feature";
CM_ SG_ 907 VC_BU_Trans_Brake_PRSNT "Backup for Transmission Brake feature present; True = [1]";
CM_ SG_ 907 VC_BU_LineLock_PRSNT "Backup for Line Lock feature present; True = [1]";
CM_ SG_ 907 VC_BU_HighOctane_PRSNT "Backup for High Octane feature present; True = [1]";
CM_ SG_ 907 VC_BU_CHILLER_PRSNT "Backup for Chiller present; True = [1]";
CM_ SG_ 907 VC_BU_ARC_PRSNT "Backup for After Run Cooling (Race Cool Down) feature present; True = [1]";
CM_ SG_ 907 VC_BU_Speedometer_Tolerance "Backup for Speedometer Tolerance Percentage (Gain for Speedometer Biasing)";
CM_ SG_ 907 VC_BU_Increasing_Speed_Constant "Backup for Increasing Speed Constant (Offset for Speedometer Biasing)";
CM_ SG_ 907 VC_BU_WHL_BASE_LENGTH "Back up Wheel Base Length";
CM_ SG_ 907 VC_BU_SBL_FBL_CORNERING_PRSNT "Configuration messages status 8";
CM_ SG_ 907 VC_BU_PPPAHardBtn "PPPA Hard button present; Present = [1]";
CM_ SG_ 907 VC_BU_PEB_PRSNT "Vehicle config to learn the presence of PEB";
CM_ SG_ 907 VC_BU_OFFroad_Camera "OFF Road Camera Present, Present = 1";
CM_ SG_ 907 VC_BU_OFFRoadModePrsnt "OFF ROAD MODE Present BackUp Configuration, Present = 1";
CM_ SG_ 907 VC_BU_DBL_PRSNT "Present = 1";
CM_ SG_ 907 VC_BU_BEAM_SHAPING_PRSNT "Present = 1";
CM_ SG_ 907 VC_BU_AVAC_PRSNT "Present = 1";
CM_ SG_ 907 VC_BU_OvertakingBan "Backup for Overtaking Ban present; present = [1]";
CM_ SG_ 907 VC_BU_TrailerTPM_Prsnt "Back up for Trailer TPM Present; True = [1] ";
CM_ SG_ 907 VC_BU_TFA_Prsnt "Back up for Tire Fill Alert Present; True = [1] ";
CM_ SG_ 907 VC_BU_TACHO_TYPE "Backup Vehicle Configuration 8 Packet";
CM_ SG_ 907 VC_BU_STFA_Prsnt "Back up for Selectable Tire Fill Alert Present; True = [1] ";
CM_ SG_ 907 VC_BU_MARKET_HEADLAMP "Headlamp led intensity configuration referred to market homologation";
CM_ SG_ 907 VC_BU_Dgtl_CHMSL_Cam_Prsnt "Digital CHMSL Camera Present Backup;Present = 1";
CM_ SG_ 907 VC_BU_WRSS_Prsnt "Wired Remote Start Stop Feature Backup;0 = Not Set, 1 = Set";
CM_ SG_ 907 VC_BU_Trlr_Rev_Guidance_Prsnt "Back up for Trailer Reverse Guidance Present; 0 = Not Set, 1 = Set";
CM_ SG_ 907 VC_BU_Box_Delete "Pickup Box Delete Backup;0 = Not Set, 1 = Set";
CM_ SG_ 907 VC_BU_Aux_Trailer_Cam_Prsnt "Back up for Auxiliary Trailer Camera Present; 0 = Not Set, 1 = Set";
CM_ SG_ 906 VC_VehCfg8_Stat "Configuration messages status 8";
CM_ SG_ 906 VC_Steering_Cfactor "Steering Cfactor feature";
CM_ SG_ 906 VC_Trans_Brake_PRSNT "Transmission Brake feature present; True = [1]";
CM_ SG_ 906 VC_LineLock_PRSNT "Line Lock feature present; True = [1]";
CM_ SG_ 906 VC_HighOctane_PRSNT "High Octane feature present; True = [1]";
CM_ SG_ 906 VC_CHILLER_PRSNT "Chiller present; True = [1]";
CM_ SG_ 906 VC_ARC_PRSNT "After Run Cooling (Race Cool Down) feature present; True = [1]";
CM_ SG_ 906 VC_Speedometer_Tolerance "Speedometer Tolerance Percentage (Gain for Speedometer Biasing)";
CM_ SG_ 906 VC_Increasing_Speed_Constant "Increasing Speed Constant (Offset for Speedometer Biasing)";
CM_ SG_ 906 VC_WHL_BASE_LENGTH "Wheel Base Length";
CM_ SG_ 906 VC_OHC_TYPE "Type of OHC";
CM_ SG_ 906 VC_SBL_FBL_CORNERING_PRSNT "Configuration messages status 8";
CM_ SG_ 906 VC_PPPAHardBtn "PPPA Hard button present, Present = 1";
CM_ SG_ 906 VC_PEB_PRSNT "Vehicle config to learn the presence of PEB";
CM_ SG_ 906 VC_OvertakingBan "Overtaking Ban present; present = [1]";
CM_ SG_ 906 VC_OFFroad_Camera "OFF Road Camera Present, Present = 1";
CM_ SG_ 906 VC_OFFRoadModePrsnt "OFF ROAD MODE Present, Present = 1";
CM_ SG_ 906 VC_DBL_PRSNT "Present = 1";
CM_ SG_ 906 VC_BEAM_SHAPING_PRSNT "Present = 1";
CM_ SG_ 906 VC_AVAC_PRSNT "Present = 1";
CM_ SG_ 906 VC_TrailerTPM_Prsnt "Trailer TPM Present; True = [1] ";
CM_ SG_ 906 VC_TFA_Prsnt "Tire Fill Alert Present; True = [1] ";
CM_ SG_ 906 VC_TACHO_TYPE "CBC VC Config of Tachometer Type";
CM_ SG_ 906 VC_STFA_Prsnt "Selectable Tire Fill Alert Present; True = [1] ";
CM_ SG_ 906 VC_MARKET_HEADLAMP "Headlamp led intensity configuration referred to market homologation";
CM_ SG_ 906 VC_Dgtl_CHMSL_Cam_Prsnt "Digital CHMSL Camera Present;Present = 1";
CM_ SG_ 906 VC_WRSS_Prsnt "Wired Remote Start Stop Feature Present;0 = Not Set, 1 = Set";
CM_ SG_ 906 VC_Trlr_Rev_Guidance_Prsnt "Trailer Reverse Guidance Present; 0 = Not Set, 1 = Set";
CM_ SG_ 906 VC_Box_Delete "Pickup Box Delete;0 = Not Set, 1 = Set";
CM_ SG_ 906 VC_Aux_Trailer_Cam_Prsnt "Auxiliary Trailer Camera Present; 0 = Not Set, 1 = Set";
CM_ SG_ 1556 SD_RS_ITBM "Response on Event - light";
CM_ SG_ 1590 SD_RS_ATMM "Response on Event - light";
CM_ SG_ 687 TrlrTripDist "Trip distance of the curent Trailer";
CM_ SG_ 687 TrlrStyle_4 "Trailer 4 style";
CM_ SG_ 687 TrlrStyle_3 "Trailer 3 style";
CM_ SG_ 687 TrlrStyle_2 "Trailer 2 style";
CM_ SG_ 687 TrlrStyle_1 "Trailer 1 style";
CM_ SG_ 687 SelTrlrStyle "Selected trailer style";
CM_ SG_ 687 SelTrlrNum "Selected trailer number";
CM_ SG_ 1428 ECU_APPL_ITBM "ECU to External Application";
CM_ SG_ 1462 ECU_APPL_ATMM "ECU to External Application";
CM_ SG_ 629 IRCM_AHB_On "Auto high beam on request from the IRCM ECU";
CM_ SG_ 1236 D_RS_ITBM "Diagnostic-Response";
CM_ SG_ 1270 D_RS_ATMM "Diagnostic-Response";
CM_ SG_ 1876 D_RQ_ITBM "Diagnostic-Request";
CM_ SG_ 1910 D_RQ_ATMM "Diagnostic-Request";
CM_ SG_ 875 ATMM_PopUpRqst "ATMM HMI Display Request";
CM_ SG_ 1748 APPL_ECU_ITBM "External Application to ECU";
CM_ SG_ 1782 APPL_ECU_ATMM "External Application to ECU";
CM_ SG_ 924 MsgFobBattLow "Indicates battery low on FOBIK last used for RKE purposes";
CM_ SG_ 924 MsgFobNotFnd "FOB Not Detected.";
CM_ SG_ 924 MsgNotInPark "Vehicle was not in Park.";
CM_ SG_ 924 MsgKG1 "Place holder for future.";
CM_ SG_ 924 FOB_SrchRslt "FOB search result";
CM_ SG_ 924 FOB_SrchFLT "FOB search fault";
CM_ SG_ 924 FOBinTRUNK "FOB is in zone trunk";
CM_ SG_ 924 FOBinINT "FOB is in zone interior";
CM_ SG_ 924 FOB_ExtRT "FOB is in zone exterior right";
CM_ SG_ 924 FOB_ExtLT "FOB is in zone exterior left";
CM_ SG_ 924 FOB_ExtRR "FOB is in zone exterior rear";
CM_ SG_ 924 MsgKG2 "Place holder for future.";
CM_ SG_ 818 A2D_DRV_TEMP_DR_POS "Transmit raw A/D driver temp door position to ECM to make OBD model more robust";
CM_ SG_ 818 Blower_Speed "Frequency Feedback received from the Blower";
CM_ SG_ 818 Blower_Diagnostics "Duty cycle Feedback received from the Blower";
CM_ SG_ 650 Radio_Theme "Radio Theme";
CM_ SG_ 650 CSOPSSAutoStowSts "Power side step Auto/Stow status; Auto = [0], Stow = [1]";
CM_ SG_ 181 TrqRq_SlowFast "Final torque between fast path and slow path calculated for Speed Control";
CM_ SG_ 181 EngRPM_Tach "Engine revolutions per minute for indication";
CM_ SG_ 181 CRC_ECM_ENG_TRQ2 "CRC-checksum byte 1 to 7 according to SAE J1850";
CM_ SG_ 181 MC_ECM_ENG_TRQ2 "Message counter";
CM_ SG_ 179 TargetTime "Time to achieve Trans Target Speed";
CM_ SG_ 179 MC_TCM_ENG_SPD "Message counter   TCM_ENG_SPD";
CM_ SG_ 179 CRC_TCM_ENG_SPD "CRC-checksum byte 1 to 7 according to SAE J1850";
CM_ SG_ 179 TransLosses "Transmission Drag torques";
CM_ SG_ 179 OutputSpeed_2 "Output Shaft Speed from 0 - 65534 RPM with 1 RPM resolution.  ";
CM_ SG_ 774 Tire_RR2 "Tire rear right inside on dually";
CM_ SG_ 774 Tire_RL2 "Tire rear left inside on dually";
CM_ SG_ 774 TirePrssRR2 "Tire pressure rear right inside on dually";
CM_ SG_ 774 TirePrssRL2 "Tire pressure rear left inside on dually";
CM_ SG_ 960 TrqC_Temp "Filtered torque converter temperature";
CM_ SG_ 1548 SD_RS_FDCM "Response on Event - light";
CM_ SG_ 302 STFARrAlertPress "Selectable Tire Fill Alert Rear Alert Pressure";
CM_ SG_ 302 STFAFtAlertPress "Selectable Tire Fill Alert Front Alert Pressure";
CM_ SG_ 302 TrlTPMSetPress "Trailer TPM set pressure";
CM_ SG_ 302 Stop_TPM_Programming "Stop the TPM sensor ID programming;Stop would be set to '1' to stop programming";
CM_ SG_ 302 Start_TPM_Programming "Start the TPM sensor ID programming;Start would be set to '1' to start programming";
CM_ SG_ 302 SelectedTPMTrailer_Number "TPM Trailer Number Selected";
CM_ SG_ 302 Program_Single_TPM "Program a single TPM sensor ID";
CM_ SG_ 302 Number_of_Trl_Tires "Number of Trailer Tires";
CM_ SG_ 302 Number_of_Trl_Axles "Number of Trailer Axles";
CM_ SG_ 302 Clear_Trailer_TPM_Settings "Clear trailer TPM settings";
CM_ SG_ 903 ITBM_WarnRq "ITBM warning request";
CM_ SG_ 903 ITBM_TrlrStat "Trailer connection status";
CM_ SG_ 903 ITBM_OP_PWR "ITBM brake output value (PWM)";
CM_ SG_ 903 ITBM_GAIN_STAT "Set gain";
CM_ SG_ 903 ITBM_DSP_RQ "ITBM display request";
CM_ SG_ 903 ITBM_BrkStyle "Trailer brake style";
CM_ SG_ 903 ITBM_BRK_SW "Brake light activation";
CM_ SG_ 903 ITBM_CHM_RQ "ITBM fault chime request";
CM_ SG_ 1420 ECU_APPL_FDCM "ECU to External Application";
CM_ SG_ 341 SEIU_Sts "SEIU Status";
CM_ SG_ 341 SEIU_RPM "PTO SEIU RPM ";
CM_ SG_ 341 SEIU_Enbl "SEIU feature enable bit: enabled=[1]";
CM_ SG_ 341 PTO_Target_Gear "PTO Target Gear";
CM_ SG_ 341 PTO_Remote_RPM_Method "Remote RPM method selection signal";
CM_ SG_ 341 PTO_Ramp_Rate "PTO RPM Ramp rate";
CM_ SG_ 341 PTO_Park_Brk_Required "Park brake is required to enable PTO: YES=[1]";
CM_ SG_ 341 PTO_High_Idle_RPM "PTO High Idle Set RPM";
CM_ SG_ 341 PTO_High_Idle_Enable "PTO High Idle feature enable bit: enabled=[1]";
CM_ SG_ 341 PTO_Active "PTO indication for ASBM: Default is OFF";
CM_ SG_ 341 PTO_Acc_Intlk "PTO Accelerator Interlock feature enable: enabled=[1]";
CM_ SG_ 1271 D_RS_VGT "Diagnostic-Response";
CM_ SG_ 1228 D_RS_FDCM "Diagnostic-Response";
CM_ SG_ 1911 D_RQ_VGT "Diagnostic-Request";
CM_ SG_ 1868 D_RQ_FDCM "Diagnostic-Request";
CM_ SG_ 564 AM_ECM_Trace "Aftermarket ECM trace";
CM_ SG_ 664 BDL_Enbl "Bed Lowering Mode enabled; 1 = True";
CM_ SG_ 664 ASCM_HMI_Stat2 "ASCM HMI status2";
CM_ SG_ 1740 APPL_ECU_FDCM "External Application to ECU";
CM_ SG_ 703 DrvAway_Alert "Drive Away Alert; True = [1]";
CM_ SG_ 703 DrvAway_Inhibit "Drive Away Inhibit; True = [1]";
CM_ SG_ 811 AxlLckrSts "Axle locker status";
CM_ SG_ 811 AxleLockerEVICDisplay "Axle locker HMI display request";
CM_ SG_ 811 RrAxleLockerIndRq "Rear Axle Locker Indication Request";
CM_ SG_ 811 Ft_RrAxleLockerIndRq "Front and Rear Axle Locker Indication Request";
CM_ SG_ 811 AxleUnlockIndRq "Axle Unlock Indication Request";
CM_ SG_ 811 AXLE_LCKR_SRV_RQ "Axle locker service indicator request";
CM_ SG_ 560 AC_RQ "A/C clutch request; [1] = A/C Clutch requested; 0 = A/C Clutch not requested";
CM_ SG_ 560 AC_SEL "Customer has selected A/C; [1] = A/C selected; 0 = A/C not selected";
CM_ SG_ 560 DEFROST_SEL "Defrost select switch";
CM_ SG_ 560 AC_PT_Demand "Maximum A/C demand to powertrain";
CM_ SG_ 560 EVAP_TEMP "AC evaporator temperature";
CM_ SG_ 560 EvapTempTar "Evaporator temperature target";
CM_ SG_ 560 PTC_Enbl "PTC heater enable; [1] = enable";
CM_ SG_ 821 TrlTPM_ServiceReq "Trailer TPM Service Required ; FALSE =0 ,TRUE =1";
CM_ SG_ 821 TrlTPMSetPress_TTPM "Trailer TPM set pressure";
CM_ SG_ 821 Trailer_Sensor_Mismatch "TPM sensor IDs mismatched to trailer number";
CM_ SG_ 821 Trailer_Not_Configured "Trailer Not Configured;FALSE =0 ,TRUE =1";
CM_ SG_ 821 Trailer_Configured "Trailer Configured;FALSE =0 ,TRUE =1";
CM_ SG_ 821 TPM_Programming_Complete "TPM Programming Complete; FALSE =0 ,TRUE =1";
CM_ SG_ 821 TPM_Prog_Not_Complete "Trailer programming not complete; FALSE =0 ,TRUE =1";
CM_ SG_ 821 TPMTrailer_Number "Trailer Number Selected";
CM_ SG_ 821 TPMSensor_Programmed "TPM sensor programmed";
CM_ SG_ 821 TPMLearnHornChirp "TPM sensor learn horn chirp";
CM_ SG_ 821 Number_of_Trl_Tires_TTPM "Number of Trailer Tires";
CM_ SG_ 821 Number_of_Trl_Axles_TTPM "Number of Trailer Axles";
CM_ SG_ 813 TrlTire9_Stat "Trailer Tire 9 Status";
CM_ SG_ 813 TrlTire8_Stat "Trailer Tire 8 Status";
CM_ SG_ 813 TrlTire7_Stat "Trailer Tire 7 Status";
CM_ SG_ 813 TrlTire12_Stat "Trailer Tire 12 Status";
CM_ SG_ 813 TrlTire11_Stat "Trailer Tire 11 Status";
CM_ SG_ 813 TrlTire10_Stat "Trailer Tire 10 Status";
CM_ SG_ 813 TrailerTirePress9 "Trailer Tire Pressure 9";
CM_ SG_ 813 TrailerTirePress8 "Trailer Tire Pressure 8";
CM_ SG_ 813 TrailerTirePress7 "Trailer Tire Pressure 7";
CM_ SG_ 813 TrailerTirePress12 "Trailer Tire Pressure 12";
CM_ SG_ 813 TrailerTirePress11 "Trailer Tire Pressure 11";
CM_ SG_ 813 TrailerTirePress10 "Trailer Tire Pressure 10";
CM_ SG_ 812 TrlTire6_Stat "Trailer Tire 6 Status";
CM_ SG_ 812 TrlTire5_Stat "Trailer Tire 5 Status";
CM_ SG_ 812 TrlTire4_Stat "Trailer Tire 4 Status";
CM_ SG_ 812 TrlTire3_Stat "Trailer Tire 3 Status";
CM_ SG_ 812 TrlTire2_Stat "Trailer Tire 2 Status";
CM_ SG_ 812 TrlTire1_Stat "Trailer Tire 1 Status";
CM_ SG_ 812 TrailerTirePress6 "Trailer Tire Pressure 6";
CM_ SG_ 812 TrailerTirePress5 "Trailer Tire Pressure 5";
CM_ SG_ 812 TrailerTirePress4 "Trailer Tire Pressure 4";
CM_ SG_ 812 TrailerTirePress3 "Trailer Tire Pressure 3";
CM_ SG_ 812 TrailerTirePress2 "Trailer Tire Pressure 2";
CM_ SG_ 812 TrailerTirePress1 "Trailer Tire Pressure 1";
CM_ SG_ 1560 SD_RS_TTPM "Response on Event - light";
CM_ SG_ 388 CustKeyInIgn "Driver's request, key-in-ignition";
CM_ SG_ 388 IgnPos "Drivers request, ignition position";
CM_ SG_ 388 ValImmKey "Drivers request, immobilizer results";
CM_ SG_ 388 WRSS_ENABLE "Passive entry feature enabled; [1] = True";
CM_ SG_ 388 RFHUBEngineOffRequest "This signal informs the CBC that RF_HUB is requesting an Emergency Stop; ACTIVE= 1";
CM_ SG_ 388 MC_RFHUB_A1 "Message Counter";
CM_ SG_ 388 CRC_RFHUB_A1 "CRC-Checksum Byte 1 - 7 according to SAE J1850";
CM_ SG_ 1048 NM_Mode "Network management mode";
CM_ SG_ 1048 NM_Successor "Network management logical successor";
CM_ SG_ 1048 NM_Ud_Launch "Network management userdata launch type";
CM_ SG_ 1048 NM_Sleep_Ack "Network management sleep acknowledge; True = [1]";
CM_ SG_ 1048 NM_Sleep_Ind "Network management sleep indication; True = [1]";
CM_ SG_ 1048 Nw_Id "Network identification no.";
CM_ SG_ 1432 ECU_APPL_TTPM "ECU to External Application";
CM_ SG_ 1240 D_RS_TTPM "Diagnostic-Response";
CM_ SG_ 1880 D_RQ_TTPM "Diagnostic-Request";
CM_ SG_ 1874 D_RQ_DCU "Diagnostic-Request";
CM_ SG_ 274 CmdIgnStat "Commanded ignition switch status";
CM_ SG_ 274 StTyp "Type of start being requested";
CM_ SG_ 274 RemStActv "Ignition run active for remote start (0=not active, 1=active)";
CM_ SG_ 274 KeyInIgn "Key in ignition status";
CM_ SG_ 274 StartRelayBCMSts "CBC starter relay status; [1] = ON";
CM_ SG_ 274 StartRelayBCMFault "CBC starter relay fault detected";
CM_ SG_ 274 OD_SW_PSD "Overdrive Switch Pressed; [0] = not pressed, [1] = pressed";
CM_ SG_ 1752 APPL_ECU_TTPM "External Application to ECU";
VAL_ 999 BU_NET_CFG_STAT_PT 0 "NA" 1 "PROGAMMED" 2 "NA1" 3 "SNA" ;
VAL_ 999 BU_NetCfg_BSMO 0 "Not_Present" 1 "Present" ;
VAL_ 999 BU_NetCfg_SGW 0 "Not_Present" 1 "Present" ;
VAL_ 999 BU_NetCfg_DPDM 0 "Not_Present" 1 "Present" ;
VAL_ 999 BU_NetCfg_ASBS 0 "Not_Present" 1 "Present" ;
VAL_ 999 BU_NetCfg_SWSM 0 "Not_Present" 1 "Present" ;
VAL_ 999 BU_NetCfg_MSBD 0 "Not_Present" 1 "Present" ;
VAL_ 1000 VC_VehCfg1_Stat 0 "NA" 1 "PROGAMMED" 2 "REQUEST_DATA" 3 "SNA" ;
VAL_ 1000 VC_MODEL_YEAR 63 "SNA" ;
VAL_ 1000 VC_VEH_LINE 0 "VEH_NONE" 1 "VEH_WK" 2 "VEH_LX" 22 "VEH_JC" 29 "VEH_DS" 31 "VEH_D2" 32 "VEH_DD" 33 "VEH_DP" 34 "VEH_DJ" 35 "VEH_WD" 39 "VEH_DX" 41 "VEH_LD" 42 "VEH_M156" 43 "VEH_ZD" 44 "VEH_LA" 45 "VEH_RU" 46 "VEH_M161" 47 "VEH_WS" 48 "VEH_DF" 49 "VEH_JL" 50 "VEH_M157" 51 "VEH_RA" 52 "VEH_WL" 53 "VEH_DT" 54 "VEH_DU" 55 "VEH_JT" 80 "VEH_PF" 81 "VEH_KL" 82 "VEH_UF" 83 "VEH_UT" 84 "VEH_M145" 85 "VEH_M145BD" 86 "VEH_K8" 87 "VEH_FF" 255 "SNA" ;
VAL_ 1000 VC_COUNTRY 0 "ROW" 2 "USA" 3 "EU" 4 "CND" 5 "GB" 6 "JPN" 7 "GER" 8 "SWISS" 9 "MLY" 10 "AUS" 11 "IND" 12 "GULF" 13 "VEN" 14 "MEX" 15 "BRZ" 16 "CHINA" 17 "EGYPT" 20 "S_KOR" 21 "ECE" 31 "COUNTRY_SNA" ;
VAL_ 1000 VC_LHD_RHD 0 "NA" 1 "LHD" 2 "RHD" 3 "SNA" ;
VAL_ 1000 VC_XWD 0 "2FT" 1 "2RR" 2 "ALLWD" 3 "4WD" ;
VAL_ 1000 VC_BODY_STYLE 0 "BODY_NONE" 1 "BODY_4DS" 2 "BODY_2DS" 3 "BODY_CONV" 4 "BODY_WAGON" 5 "BODY_4DH" 6 "BODY_2DP" 7 "BODY_4DP" 8 "BODY_4DMP" 15 "BODY_SNA" ;
VAL_ 1000 VC_MAX_VEH_SPD 255 "SNA" ;
VAL_ 1000 VC_ShftrTyp 0 "TYPE_NA" 1 "TYPE_ERS4" 2 "TYPE_AS4" 3 "TYPE_ERS5" 4 "TYPE_AS5" 5 "TYPE_RS5M" 6 "TYPE_RS5S" 7 "TYPE_RS5L" 8 "TYPE_ERS4ESW" 9 "TYPE_MS7D" 10 "TYPE_MS7M156" 11 "TYPE_RS4" 12 "TYPE_MS7S" 13 "TYPE_MS7" 14 "TYPE_PS5" 15 "SNA" ;
VAL_ 1000 VC_PTS_DispTyp 0 "HEAD_DISP" 1 "CCN_DISP" 2 "AUDIO_DISP" 7 "SNA" ;
VAL_ 1000 VC_SpecialPKG 0 "NONE" 255 "SNA" ;
VAL_ 1000 VC_PTS_Config 0 "REAR" 1 "FRT_REAR" 3 "SEMI" ;
VAL_ 1001 VC_VehCfg2_Stat 0 "NA" 1 "PROGAMMED" 2 "REQUEST_DATA" 3 "SNA" ;
VAL_ 1001 VC_PwrIvtrTyp 0 "NoPwrIvtr" 1 "MtrySw" 2 "LchSw" ;
VAL_ 1001 VC_MaseratiMd 0 "NORMAL" 1 "GTS" 2 "RACE" 3 "SNA" ;
VAL_ 1001 VC_SpecialPKG_IC 0 "NONE" 1 "PKG_70JP" 2 "PKG_300S" 3 "PKG_BEATS" 4 "PKG_SUPERBEE" 5 "MOPAR" 6 "Hellcat" 7 "Shaker" 8 "Scat" 9 "ADR" 10 "Scat_Drag" 11 "High_Output" 16 "LARAMIE" 17 "BIGHORN" 18 "LONGHORN" 19 "LONESTAR" 20 "LIMITED" 21 "MOSSY_OAK" 22 "ORT" 23 "POWERWAGON" 24 "HD_DX" 25 "SPORT" 26 "PWGN_Laramie" 27 "RAM_1500" 28 "PWGN_GOODYEAR" 29 "LONGHORN_BLACK" 30 "LONGHORN_BROWN" 31 "RAM_2500" 32 "RAM_3500" 33 "RAM_4500" 34 "RAM_5500" 100 "WRANGLER_SPORT" 101 "WRANGLER_SAHARA" 102 "WRANGLER_RUBICON" 150 "TRAILHAWK_SUPERCHARGED" 246 "DODGE_100" 247 "VARVATOS" 255 "SNA" ;
VAL_ 1001 VC_ShftInd_Prsnt 0 "NONE" 1 "GSI" 2 "PSI" 3 "PGSI" ;
VAL_ 1001 VC_MaxLdPressRrTr 255 "SNA" ;
VAL_ 1001 VC_MaxLdPressFtTr 255 "SNA" ;
VAL_ 1001 VC_LgtLdPressRrTr 255 "SNA" ;
VAL_ 1001 VC_LgtLdPressFtTr 255 "SNA" ;
VAL_ 1002 VC_VehCfg3_Stat 0 "NA" 1 "PROGAMMED" 2 "REQUEST_DATA" 3 "SNA" ;
VAL_ 1002 VC_TcaseTyp 0 "NOT_PRSNT" 1 "TCASE_143_144" 2 "BW4445_46_48_WS" 3 "Tcase_253_1522" 4 "Tcase_BW4444" 5 "Tcase_BW4446" 6 "Tcase_MPT3025C" 7 "Tcase_241_MPT1222C" 8 "BW4447_WOS" 9 "Tcase_243" 10 "BW4447_49_WS" 11 "Tcase_273" 12 "Tcase_MAS_ATC" 13 "Tcase_BW4440" 14 "Tcase_156" 15 "Tcase_256_3022" ;
VAL_ 1002 VC_WHL_BASE 0 "SHORT" 1 "LONG" 2 "XLONG" 3 "SNA" ;
VAL_ 1002 VC_FUEL_CAP 255 "SNA" ;
VAL_ 1002 VC_WIN_EXPR_FEAT 0 "WIN_EXPR_DRV" 1 "WIN_EXPR_FT" 2 "WIN_EXPR_ALL" 3 "WIN_EXPR_NN" ;
VAL_ 1002 VC_ChassisType 127 "SNA" ;
VAL_ 1002 VC_HVAC_Config 0 "1_ZN_MTC" 1 "1_ZN_MTC_p_RR" 2 "1_ZN_ATC" 3 "2_ZN_MTC" 4 "2_ZN_ATC" 5 "2_ZN_ATC_p_RR" 6 "2_ZN_MTC_p_RR" 15 "SNA" ;
VAL_ 1002 VC_VEH_BRAND 1 "CHRYSLER" 2 "DODGE" 3 "JEEP" 4 "MERCEDES_BENZ" 5 "MITSUBISHI" 6 "VOLKSWAGEN" 7 "FREIGHTLINER" 8 "ALPHA" 9 "FIAT" 10 "LANCIA" 11 "MASERATI" 12 "RAM" 15 "SNA" ;
VAL_ 1002 VC_Liftgate_Trunk 0 "TRUNK" 1 "PLG" 2 "MANUAL_LG" 3 "SNA" ;
VAL_ 1003 VC_TCASE_HI_RATIO 16383 "SNA" ;
VAL_ 1003 VC_VehCfg4_Stat 0 "NA" 1 "PROGAMMED" 2 "REQUEST_DATA" 3 "SNA" ;
VAL_ 1003 VC_AXLE_RATIO 65535 "SNA" ;
VAL_ 1003 VC_TCASE_LO_RATIO 65535 "SNA" ;
VAL_ 1003 VC_TIRE_CIRCUMF 65535 "SNA" ;
VAL_ 1004 VC_BU_VehCfg1_Stat 0 "NA" 1 "PROGAMMED" 2 "NA1" 3 "SNA" ;
VAL_ 1004 VC_BU_MODEL_YEAR 63 "SNA" ;
VAL_ 1004 VC_BU_VEH_LINE 0 "VEH_NONE" 1 "VEH_WK" 2 "VEH_LX" 22 "VEH_JC" 29 "VEH_DS" 31 "VEH_D2" 32 "VEH_DD" 33 "VEH_DP" 34 "VEH_DJ" 35 "VEH_WD" 39 "VEH_DX" 41 "VEH_LD" 42 "VEH_M156" 43 "VEH_ZD" 44 "VEH_LA" 45 "VEH_RU" 46 "VEH_M161" 47 "VEH_WS" 48 "VEH_DF" 49 "VEH_JL" 50 "VEH_M157" 51 "VEH_RA" 52 "VEH_WL" 53 "VEH_DT" 54 "VEH_DU" 55 "VEH_JT" 80 "VEH_PF" 81 "VEH_KL" 82 "VEH_UF" 83 "VEH_UT" 84 "VEH_M145" 85 "VEH_M145BD" 86 "VEH_K8" 87 "VEH_FF" 255 "SNA" ;
VAL_ 1004 VC_BU_COUNTRY 0 "ROW" 2 "USA" 3 "EU" 4 "CND" 5 "GB" 6 "JPN" 7 "GER" 8 "SWISS" 9 "MLY" 10 "AUS" 11 "IND" 12 "GULF" 13 "VEN" 14 "MEX" 15 "BRZ" 16 "CHINA" 17 "EGYPT" 20 "S_KOR" 21 "ECE" 31 "COUNTRY_SNA" ;
VAL_ 1004 VC_BU_LHD_RHD 0 "NA" 1 "LHD" 2 "RHD" 3 "SNA" ;
VAL_ 1004 VC_BU_RemStPrsnt 0 "SNA" ;
VAL_ 1004 VC_BU_XWD 0 "2FT" 1 "2RR" 2 "ALLWD" 3 "4WD" ;
VAL_ 1004 VC_BU_BODY_STYLE 0 "BODY_NONE" 1 "BODY_4DS" 2 "BODY_2DS" 3 "BODY_CONV" 4 "BODY_WAGON" 5 "BODY_4DH" 6 "BODY_2DP" 7 "BODY_4DP" 8 "BODY_4DMP" 15 "BODY_SNA" ;
VAL_ 1004 VC_BU_MAX_VEH_SPD 255 "SNA" ;
VAL_ 1004 VC_BU_ShftrTyp 0 "TYPE_NA" 1 "TYPE_ERS4" 2 "TYPE_AS4" 3 "TYPE_ERS5" 4 "TYPE_AS5" 5 "TYPE_RS5M" 6 "TYPE_RS5S" 7 "TYPE_RS5L" 8 "TYPE_ERS4ESW" 9 "TYPE_MS7D" 10 "TYPE_MS7M156" 11 "TYPE_RS4" 12 "TYPE_MS7S" 13 "TYPE_MS7" 14 "TYPE_PS5" 15 "SNA" ;
VAL_ 1004 VC_BU_PTS_DispTyp 0 "HEAD_DISP" 1 "CCN_DISP" 2 "AUDIO_DISP" 7 "SNA" ;
VAL_ 1004 VC_BU_SpecialPKG 0 "NONE" 255 "SNA" ;
VAL_ 1004 VC_BU_PTS_Config 0 "REAR" 1 "FRT_REAR" 3 "SEMI" ;
VAL_ 1005 VC_BU_VehCfg2_Stat 0 "NA" 1 "PROGAMMED" 2 "NA1" 3 "SNA" ;
VAL_ 1005 VC_BU_PwrIvtrTyp 0 "NoPwrIvtr" 1 "MtrySw" 2 "LchSw" ;
VAL_ 1005 VC_BU_MaseratiMd 0 "NORMAL" 1 "GTS" 2 "RACE" 3 "SNA" ;
VAL_ 1005 VC_BU_SpecialPKG_IC 0 "NONE" 1 "PKG_70JP" 2 "PKG_300S" 3 "PKG_BEATS" 4 "PKG_SUPERBEE" 5 "MOPAR" 6 "Hellcat" 7 "Shaker" 8 "Scat" 9 "ADR" 10 "Scat_Drag" 11 "High_Output" 16 "LARAMIE" 17 "BIGHORN" 18 "LONGHORN" 19 "LONESTAR" 20 "LIMITED" 21 "MOSSY_OAK" 22 "ORT" 23 "POWERWAGON" 24 "HD_DX" 25 "SPORT" 26 "PWGN_Laramie" 27 "RAM_1500" 28 "PWGN_GOODYEAR" 29 "LONGHORN_BLACK" 30 "LONGHORN_BROWN" 31 "RAM_2500" 32 "RAM_3500" 33 "RAM_4500" 34 "RAM_5500" 100 "WRANGLER_SPORT" 101 "WRANGLER_SAHARA" 102 "WRANGLER_RUBICON" 150 "TRAILHAWK_SUPERCHARGED" 246 "DODGE_100" 247 "VARVATOS" 255 "SNA" ;
VAL_ 1005 VC_BU_ShftInd_Prsnt 0 "NONE" 1 "GSI" 2 "PSI" 3 "PGSI" ;
VAL_ 1005 VC_BU_MaxLdPressRrTr 255 "SNA" ;
VAL_ 1005 VC_BU_MaxLdPressFtTr 255 "SNA" ;
VAL_ 1005 VC_BU_LgtLdPressRrTr 255 "SNA" ;
VAL_ 1005 VC_BU_LgtLdPressFtTr 255 "SNA" ;
VAL_ 1006 VC_BU_VehCfg3_Stat 0 "NA" 1 "PROGAMMED" 2 "NA1" 3 "SNA" ;
VAL_ 1006 VC_BU_TcaseTyp 0 "NOT_PRSNT" 1 "TCASE_143_144" 2 "BW4445_46_48_WS" 3 "Tcase_253_1522" 4 "Tcase_BW4444" 5 "Tcase_BW4446" 6 "Tcase_MPT3025C" 7 "Tcase_241_MPT1222C" 8 "BW4447_WOS" 9 "Tcase_243" 10 "BW4447_49_WS" 11 "Tcase_273" 12 "Tcase_MAS_ATC" 13 "Tcase_BW4440" 14 "Tcase_156" 15 "Tcase_256_3022" ;
VAL_ 1006 VC_BU_WHL_BASE 0 "SHORT" 1 "LONG" 2 "XLONG" 3 "SNA" ;
VAL_ 1006 VC_BU_ELV_PRSNT 0 "SNA" ;
VAL_ 1006 VC_BU_FUEL_CAP 255 "SNA" ;
VAL_ 1006 VC_BU_WIN_EXPR_FEAT 0 "WIN_EXPR_DRV" 1 "WIN_EXPR_FT" 2 "WIN_EXPR_ALL" 3 "WIN_EXPR_NN" ;
VAL_ 1006 VC_BU_ChassisType 127 "SNA" ;
VAL_ 1006 VC_BU_HVAC_Config 0 "1_ZN_MTC" 1 "1_ZN_MTC_p_RR" 2 "1_ZN_ATC" 3 "2_ZN_MTC" 4 "2_ZN_ATC" 5 "2_ZN_ATC_p_RR" 6 "2_ZN_MTC_p_RR" 15 "SNA" ;
VAL_ 1006 VC_BU_VEH_BRAND 1 "CHRYSLER" 2 "DODGE" 3 "JEEP" 4 "MERCEDES_BENZ" 5 "MITSUBISHI" 6 "VOLKSWAGEN" 7 "FREIGHTLINER" 8 "ALPHA" 9 "FIAT" 10 "LANCIA" 11 "MASERATI" 12 "RAM" 15 "SNA" ;
VAL_ 1006 VC_BU_Liftgate_Trunk 0 "TRUNK" 1 "PLG" 2 "MANUAL_LG" 3 "SNA" ;
VAL_ 1007 VC_BU_TCASE_HI_RATIO 16383 "SNA" ;
VAL_ 1007 VC_BU_VehCfg4_Stat 0 "NA" 1 "PROGAMMED" 2 "NA1" 3 "SNA" ;
VAL_ 1007 VC_BU_AXLE_RATIO 65535 "SNA" ;
VAL_ 1007 VC_BU_TCASE_LO_RATIO 65535 "SNA" ;
VAL_ 1007 VC_BU_TIRE_CIRCUMF 65535 "SNA" ;
VAL_ 1008 EC_ECUCfg1_Stat 0 "NA" 1 "PROGAMMED" 2 "REQUEST_DATA" 3 "SNA" ;
VAL_ 1009 EC_ECUCfg2_Stat 0 "NA" 1 "PROGAMMED" 2 "REQUEST_DATA" 3 "SNA" ;
VAL_ 1010 EC_ECUCfg3_Stat 0 "NA" 1 "PROGAMMED" 2 "REQUEST_DATA" 3 "SNA" ;
VAL_ 1011 EC_ECUCfg4_Stat 0 "NA" 1 "PROGAMMED" 2 "REQUEST_DATA" 3 "SNA" ;
VAL_ 1012 EC_ECUCfg5_Stat 0 "NA" 1 "PROGAMMED" 2 "REQUEST_DATA" 3 "SNA" ;
VAL_ 1013 EC_ECUCfg6_Stat 0 "NA" 1 "PROGAMMED" 2 "REQUEST_DATA" 3 "SNA" ;
VAL_ 1014 EC_ECUCfg7_Stat 0 "NA" 1 "PROGAMMED" 2 "REQUEST_DATA" 3 "SNA" ;
VAL_ 1015 EC_ECUCfg8_Stat 0 "NA" 1 "PROGAMMED" 2 "REQUEST_DATA" 3 "SNA" ;
VAL_ 1016 EC_BU_ECUCfg1_Stat 0 "NA" 1 "PROGAMMED" 2 "NA1" 3 "SNA" ;
VAL_ 1017 EC_BU_ECUCfg2_Stat 0 "NA" 1 "PROGAMMED" 2 "NA1" 3 "SNA" ;
VAL_ 1018 EC_BU_ECUCfg3_Stat 0 "NA" 1 "PROGAMMED" 2 "NA1" 3 "SNA" ;
VAL_ 1019 EC_BU_ECUCfg4_Stat 0 "NA" 1 "PROGAMMED" 2 "NA1" 3 "SNA" ;
VAL_ 1020 EC_BU_ECUCfg5_Stat 0 "NA" 1 "PROGAMMED" 2 "NA1" 3 "SNA" ;
VAL_ 1021 EC_BU_ECUCfg6_Stat 0 "NA" 1 "PROGAMMED" 2 "NA1" 3 "SNA" ;
VAL_ 1022 EC_BU_ECUCfg7_Stat 0 "NA" 1 "PROGAMMED" 2 "NA1" 3 "SNA" ;
VAL_ 1023 EC_BU_ECUCfg8_Stat 0 "NA" 1 "PROGAMMED" 2 "NA1" 3 "SNA" ;
VAL_ 1024 NM_Mode 252 "LHOM" 253 "RING" 254 "ALIVE" 255 "SNA" ;
VAL_ 1024 NM_Successor 255 "SNA" ;
VAL_ 1024 NM_Ud_Launch 4 "BROADCAST" 63 "SNA" ;
VAL_ 1024 Nw_Id 0 "POWERTRAIN" 1 "BODY" 2 "AUDIO_TELE" 255 "SNA" ;
VAL_ 1025 NM_Mode 252 "LHOM" 253 "RING" 254 "ALIVE" 255 "SNA" ;
VAL_ 1025 NM_Successor 255 "SNA" ;
VAL_ 1025 NM_Ud_Launch 4 "BROADCAST" 63 "SNA" ;
VAL_ 1025 Nw_Id 0 "POWERTRAIN" 1 "BODY" 2 "AUDIO_TELE" 255 "SNA" ;
VAL_ 1026 NM_Mode 252 "LHOM" 253 "RING" 254 "ALIVE" 255 "SNA" ;
VAL_ 1026 NM_Successor 255 "SNA" ;
VAL_ 1026 NM_Ud_Launch 4 "BROADCAST" 63 "SNA" ;
VAL_ 1026 Nw_Id 0 "POWERTRAIN" 1 "BODY" 2 "AUDIO_TELE" 255 "SNA" ;
VAL_ 1031 NM_Mode 252 "LHOM" 253 "RING" 254 "ALIVE" 255 "SNA" ;
VAL_ 1031 NM_Successor 255 "SNA" ;
VAL_ 1031 NM_Ud_Launch 4 "BROADCAST" 63 "SNA" ;
VAL_ 1031 Nw_Id 0 "POWERTRAIN" 1 "BODY" 2 "AUDIO_TELE" 255 "SNA" ;
VAL_ 1033 NM_Mode 252 "LHOM" 253 "RING" 254 "ALIVE" 255 "SNA" ;
VAL_ 1033 NM_Successor 255 "SNA" ;
VAL_ 1033 NM_Ud_Launch 4 "BROADCAST" 63 "SNA" ;
VAL_ 1033 Nw_Id 0 "POWERTRAIN" 1 "BODY" 2 "AUDIO_TELE" 255 "SNA" ;
VAL_ 1059 NM_Mode 252 "LHOM" 253 "RING" 254 "ALIVE" 255 "SNA" ;
VAL_ 1059 NM_Successor 255 "SNA" ;
VAL_ 1059 NM_Ud_Launch 4 "BROADCAST" 63 "SNA" ;
VAL_ 1059 Nw_Id 0 "POWERTRAIN" 1 "BODY" 2 "AUDIO_TELE" 255 "SNA" ;
VAL_ 1098 VC_VehCfg5_Stat 0 "NA" 1 "PROGAMMED" 2 "REQUEST_DATA" 3 "SNA" ;
VAL_ 1098 VC_AmbTempLct 0 "CBC" 1 "DCM" 3 "SNA" ;
VAL_ 1098 VC_Strng_Rt_0 255 "SNA" ;
VAL_ 1098 VC_Strng_Rt_pls1 255 "SNA" ;
VAL_ 1098 VC_Strng_Rt_pls2 255 "SNA" ;
VAL_ 1098 VC_Strng_Rt_pls3 255 "SNA" ;
VAL_ 1098 VC_Strng_Rt_pls4 255 "SNA" ;
VAL_ 1098 VC_Strng_Rt_pls5 255 "SNA" ;
VAL_ 1099 VC_BU_VehCfg5_Stat 0 "NA" 1 "PROGAMMED" 2 "NA1" 3 "SNA" ;
VAL_ 1099 VC_BU_AmbTempLct 0 "CBC" 1 "DCM" 3 "SNA" ;
VAL_ 1099 VC_BU_Strng_Rt_0 255 "SNA" ;
VAL_ 1099 VC_BU_Strng_Rt_pls1 255 "SNA" ;
VAL_ 1099 VC_BU_Strng_Rt_pls2 255 "SNA" ;
VAL_ 1099 VC_BU_Strng_Rt_pls3 255 "SNA" ;
VAL_ 1099 VC_BU_Strng_Rt_pls4 255 "SNA" ;
VAL_ 1099 VC_BU_Strng_Rt_pls5 255 "SNA" ;
VAL_ 1100 VC_VehCfg6_Stat 0 "NA" 1 "PROGAMMED" 2 "REQUEST_DATA" 3 "SNA" ;
VAL_ 1100 VC_AnlgDrSnsr 0 "NONE" 1 "DRV" 2 "FT" 3 "ALL" ;
VAL_ 1100 VC_BrkTyp 0 "SMALL" 1 "PB" 2 "CB" 3 "MB" 7 "SNA" ;
VAL_ 1100 VC_Strng_Rt_Mns1 255 "SNA" ;
VAL_ 1100 VC_Strng_Rt_Mns2 255 "SNA" ;
VAL_ 1100 VC_Strng_Rt_Mns3 255 "SNA" ;
VAL_ 1100 VC_Strng_Rt_Mns4 255 "SNA" ;
VAL_ 1100 VC_Strng_Rt_Mns5 255 "SNA" ;
VAL_ 1100 VC_TireCircumfFT 65535 "SNA" ;
VAL_ 1101 VC_BU_VehCfg6_Stat 0 "NA" 1 "PROGAMMED" 2 "NA1" 3 "SNA" ;
VAL_ 1101 VC_BU_AnlgDrSnsr 0 "NONE" 1 "DRV" 2 "FT" 3 "ALL" ;
VAL_ 1101 VC_BU_BrkTyp 0 "SMALL" 1 "PB" 2 "CB" 3 "MB" 7 "SNA" ;
VAL_ 1101 VC_BU_Strng_Rt_Mns1 255 "SNA" ;
VAL_ 1101 VC_BU_Strng_Rt_Mns2 255 "SNA" ;
VAL_ 1101 VC_BU_Strng_Rt_Mns3 255 "SNA" ;
VAL_ 1101 VC_BU_Strng_Rt_Mns4 255 "SNA" ;
VAL_ 1101 VC_BU_Strng_Rt_Mns5 255 "SNA" ;
VAL_ 1101 VC_BU_TireCircumfFT 65535 "SNA" ;
VAL_ 362 DrvLnTrqRq 511 "SNA" ;
VAL_ 640 Mem_D_Pos_Rq 0 "IDLE" 1 "MEMPOS1" 2 "MEMPOS2" ;
VAL_ 752 MEM_RC_STAT 0 "MEM_ENBL" 1 "SB_BUCKLED" 2 "VEH_NOT_PARK" 3 "VEH_IN_MOT" 7 "SNA" ;
VAL_ 752 MSMD_PDL_LKOUT 0 "LKOUT_NONE" 1 "LKOUT_CRUISE" 2 "LKOUT_TX_REV" 3 "AP_DSBL" 7 "SNA" ;
VAL_ 752 EASY_EXIT 0 "OFF" 1 "ON" 2 "NDEF2" 3 "SNA" ;
VAL_ 847 RF_FobNum 0 "FOB_DEFAULT" 1 "FOB_1" 2 "FOB_2" 3 "FOB_3" 4 "FOB_4" 5 "FOB_5" 6 "FOB_6" 7 "FOB_7" 8 "FOB_8" 15 "SNA" ;
VAL_ 806 AFLS_Stat 0 "DISABLED" 1 "ENABLED" 2 "F_HL" 3 "F_HS" ;
VAL_ 530 Adblue_FL_LVL 255 "SNA" ;
VAL_ 530 Adblue_Stat 0 "OK" 1 "DEFLW1" 2 "DEFLW2" 3 "DEFLW3" 4 "DEFLW4" 5 "DEFLW5" 6 "DEFLW6" 7 "DEFLW7" 8 "DEFLW8" 9 "DEFLW9" 10 "DEFLW10" 11 "DEFLW11" 12 "DEFLW12" 13 "DEFLW13" 14 "DEFLW14" 15 "DEFLW15" 16 "DEFQW1" 17 "DEFQW2" 18 "DEFQW3" 19 "DEFQW4" 20 "DEFQW5" 21 "DEFQW6" 22 "DEFQW7" 23 "DEFQW8" 24 "DEFQW9" 25 "DEFQW10" 33 "DEFLW1_RL" 34 "DEFLW2_RL" 35 "DEFLW3_RL" 36 "DEFLW4_RL" 37 "DEFLW5_RL" 38 "DEFLW6_RL" 39 "DEFLW7_RL" 40 "DEFLW8_RL" 41 "DEFLW9_RL" 42 "DEFLW10_RL" 43 "DEFLW11_RL" 44 "DEFLW12_RL" 45 "DEFLW13_RL" 46 "DEFLW14_RL" 47 "DEFLW15_RL" 48 "DEFQW1_RL" 49 "DEFQW2_RL" 50 "DEFQW3_RL" 51 "DEFQW4_RL" 52 "DEFQW5_RL" 53 "DEFQW6_RL" 54 "DEFQW7_RL" 55 "DEFQW8_RL" 56 "DEFQW9_RL" 57 "DEFQW10_RL" 63 "SNA" ;
VAL_ 530 AdblueRemainDist 65535 "SNA" ;
VAL_ 530 DEF_LOW 0 "OFF" 1 "CONT" 2 "BLINK" 3 "SNA" ;
VAL_ 530 ECM_HMI_Timer_RQ 0 "TMR120" 1 "TMR60" 2 "TMR30" 7 "SNA" ;
VAL_ 530 PFW_Stat 0 "PFW_MN" 1 "RegRqPFW_Stat" 2 "SerRqPFW_Stat" 3 "SER_REQ" 4 "REG_CMPL" 5 "RegActPFW_Stat" 6 "PWR_RED" 9 "RegRqPFW_StatRL" 10 "SerRqPFW_StatRL" 11 "SER_REQ_RL" 12 "REG_CMPL_RL" 13 "RegActPFW_StatRL" 14 "PWR_RED_RL" 15 "SNA" ;
VAL_ 530 PrcntCplt 15 "SNA" ;
VAL_ 530 PreHtIndLmp_On_Rq 0 "SNA" ;
VAL_ 530 WtrFuelIndLmp_On_Rq 0 "SNA" ;
VAL_ 625 DsrSpeed_KPH 255 "SNA" ;
VAL_ 625 FCWSetting 0 "OFF" 1 "NEAR" 2 "MEDIUM" 3 "FAR" ;
VAL_ 684 INV_CARGO_OnState 0 "None" 1 "Disable" 2 "Enable" 3 "SNA" ;
VAL_ 684 GateOnOffSts 0 "DOOR_ON" 1 "DOOR_OFF" 2 "FLT" 3 "SNA" ;
VAL_ 705 VEH_INT_TEMP 65535 "SNA" ;
VAL_ 705 SwayBarBtnRq 0 "NOT_PRESSED" 1 "PRESSED" 2 "STUCK" 3 "SNA" ;
VAL_ 709 EC_ECUCfg16_Stat 0 "NA" 1 "PROGAMMED" 2 "REQUEST_DATA" 3 "SNA" ;
VAL_ 710 EC_ECUCfg17_Stat 0 "NA" 1 "PROGAMMED" 2 "REQUEST_DATA" 3 "SNA" ;
VAL_ 714 EC_BU_ECUCfg16_Stat 0 "NA" 1 "PROGAMMED" 2 "NA1" 3 "SNA" ;
VAL_ 715 EC_BU_ECUCfg17_Stat 0 "NA" 1 "PROGAMMED" 2 "REQUEST_DATA" 3 "SNA" ;
VAL_ 773 Tire_FL 0 "NORMAL" 1 "LOW" 2 "HIGH" 3 "SNA" ;
VAL_ 773 Tire_FR 0 "NORMAL" 1 "LOW" 2 "HIGH" 3 "SNA" ;
VAL_ 773 Tire_RL 0 "NORMAL" 1 "LOW" 2 "HIGH" 3 "SNA" ;
VAL_ 773 Tire_RR 0 "NORMAL" 1 "LOW" 2 "HIGH" 3 "SNA" ;
VAL_ 773 Tire_Spr 0 "NORMAL" 1 "LOW" 2 "HIGH" 3 "SNA" ;
VAL_ 773 TirePrssFL 255 "SNA" ;
VAL_ 773 TirePrssFR 255 "SNA" ;
VAL_ 773 TirePrssRL 255 "SNA" ;
VAL_ 773 TirePrssRR 255 "SNA" ;
VAL_ 773 TirePrssSpr 255 "SNA" ;
VAL_ 773 TPM_IndLmpOnRq 0 "IND_LMP_OFF" 1 "IND_LMP_ON" 2 "IND_LMP_FLASH" 3 "SNA" ;
VAL_ 773 TPM_SysStat 0 "NON_LOCALIZED" 1 "PERF_LOCALIZATION" 2 "LOCALIZATION_CMPLT" 3 "TPM_NA" 4 "LOCALIZATION_NOT_CMPLT" 7 "SNA" ;
VAL_ 773 TPMHornChirp 0 "HORN_CHIRP_OFF" 1 "SINGLE_HORN_CHIRP" 2 "MULTIPLE_HORN_CHIRP" 3 "SNA" ;
VAL_ 773 TPMHazardFlash 0 "FALSE" 1 "TRUE" ;
VAL_ 778 TrboBstPress 255 "SNA" ;
VAL_ 778 EngBrkStat 0 "EB_OFF" 1 "EB_ENBL" 2 "EB_RQ" 3 "SNA" ;
VAL_ 778 WTS_CntDnTmr 255 "SNA" ;
VAL_ 778 Man_PFW_Stat 0 "Man_Default" 1 "Man_FilterNotFull" 2 "Man_InsufficientFuel" 3 "Man_InsufficientTime" 4 "Man_EngNotOn" 5 "Man_NoPark" 6 "Man_PedalPrsd" 7 "Man_SerRqd" 8 "Man_Res1" 9 "Man_Res2" 10 "Man_Res3" 11 "Man_Res4" 12 "Man_Others" 13 "Man_LowOil" 14 "Man_PTOAct" 15 "SNA" ;
VAL_ 778 EB_Stat3 0 "EB_OFF" 1 "EB_ON" 2 "EB_LT" 3 "EB_MED" 4 "EB_HVY" 5 "EB_SMART" 7 "SNA" ;
VAL_ 778 EB_Pwr 255 "SNA" ;
VAL_ 778 DPF_Man_Stat 0 "Man_Regen_Disabld" 1 "Man_Regen_Enbld" 2 "Man_Regen_InProcess" 3 "Man_Regen_Res1" 4 "Man_Regen_Completed" 5 "Man_Regen_Res2" 6 "Man_Regen_Cancelled" 7 "SNA" ;
VAL_ 778 DrtdTrqMd 0 "NM" 1 "MESS1" 2 "MESS2" 3 "MESS3" ;
VAL_ 831 RL_Lvl 254 "NOT_INIT" 255 "SNA" ;
VAL_ 831 RR_Lvl 254 "NOT_INIT" 255 "SNA" ;
VAL_ 844 ASCM_Exit_Rq 0 "OFF" 1 "CONT" 2 "BLINK" 3 "SNA" ;
VAL_ 844 ASCM_HMI_Stat 0 "NONE" 1 "ASCM_RedSpd" 2 "ASCM_LvlnPrmt" 3 "ASCM_Cooldn" 4 "ASCM_Dr" 5 "ASCM_Srv" 6 "ASCM_SysFail" 7 "ASCM_VLSt" 8 "ASCM_TJM_Disp" 9 "ASCM_LowClr" 10 "ASCM_Highlr" 11 "TM_Enbl" 12 "ALM_Enbl" 13 "ASCM_WarnONly" 14 "ASCM_AeroDslb" 15 "SNA" ;
VAL_ 844 ASCM_Stat 0 "NO_MESS" 1 "DUMP" 2 "PARK" 3 "AERO" 4 "NVL" 5 "OR1" 6 "ORL2" 7 "EEHNA" 8 "RAISE" 9 "LOWER" 10 "RL_INT" 11 "SRVS" 12 "AERO2" 15 "SNA" ;
VAL_ 844 ASCM_StatDisp 0 "NO_MESS" 1 "DUMP" 2 "PARK" 3 "AERO" 4 "NVL" 5 "OR1" 6 "ORL2" 7 "EEHNA" 8 "LMR" 9 "LML" 10 "RL_INT" 11 "LNA_OL" 12 "ASCM_LNP_SPEED" 13 "ASCM_LNP_PAYLOAD" 14 "ASCM_LNP_MINLoad" 15 "SNA" ;
VAL_ 844 Loading_Lv 0 "LND" 1 "LIGHT" 2 "MEDIUM" 3 "FULL" 4 "OVERLOAD_1" 5 "OVERLOAD_2" 6 "MIP" 7 "SNA" ;
VAL_ 844 LvlAdjStat 0 "STATIC" 1 "RAISE" 2 "LOWER" 3 "RL_INT" ;
VAL_ 844 Tgt_Level 0 "TR_Dump" 1 "Park" 2 "AERO" 3 "STD" 4 "OR1" 5 "ORL2" 6 "AERO2" 7 "SNA" ;
VAL_ 1062 NM_Mode 252 "LHOM" 253 "RING" 254 "ALIVE" 255 "SNA" ;
VAL_ 1062 NM_Successor 255 "SNA" ;
VAL_ 1062 NM_Ud_Launch 4 "BROADCAST" 63 "SNA" ;
VAL_ 1062 Nw_Id 0 "POWERTRAIN" 1 "BODY" 2 "AUDIO_TELE" 255 "SNA" ;
VAL_ 294 LatAcceleration 4095 "SNA" ;
VAL_ 294 AXSStat 0 "SISL" 1 "TSE" 2 "PSE" 3 "SEII" ;
VAL_ 294 AYSStat 0 "SISL" 1 "TSE" 2 "PSE" 3 "SEII" ;
VAL_ 294 LongAcceleration 4095 "SNA" ;
VAL_ 294 YRSStat 0 "SISL" 1 "TSE" 2 "PSE" 3 "SEII" ;
VAL_ 294 YawRate 4095 "SNA" ;
VAL_ 516 ControlEncodingRsp 16 "ControlEncoding_TEN" 153 "ControlEncoding_UC" 170 "ControlEncoding_PRA" 171 "ControlEncoding_PVA" ;
VAL_ 517 ControlEncodingRq 5 "ControlEncoding_ENQ" 6 "ControlEncoding_ACK" 21 "ControlEncoding_NACK" 129 "ControlEncoding_NACKp" 132 "ControlEncoding_EOTp" 133 "ControlEncoding_ENQp" 134 "ControlEncoding_ACK1p" 135 "ControlEncoding_ACK2p" ;
VAL_ 526 CodeCheckSts 0 "No_Code" 1 "CodeCheck_OK" 2 "CodeCheck_Fault" ;
VAL_ 526 TxpID 0 "Transponder_Not_Authenticated" 1 "Transponder_1_Authenticated" 2 "Transponder_2_Authenticated" 3 "Transponder_3_Authenticated" 4 "Transponder_4_Authenticated" 5 "Transponder_5_Authenticated" 6 "Transponder_6_Authenticated" 7 "Transponder_7_Authenticated" 8 "Transponder_8_Authenticated" 9 "Transponder_9_Authenticated" 10 "Transponder_10_Authenticated" 11 "Transponder_11_Authenticated" 12 "Transponder_12_Authenticated" 13 "Transponder_13_Authenticated" 14 "Transponder_14_Authenticated" 15 "Transponder_15_Authenticated" ;
VAL_ 527 FrameNumber 0 "Frame_1" 1 "Frame_2" 2 "Frame_3" 3 "Frame_4" 4 "Frame_5" 5 "Frame_6" 6 "Frame_7" 7 "Frame_8" 8 "Frame_9" 9 "Frame_10" 10 "Frame_11" 11 "Frame_12" 12 "Frame_13" 13 "Frame_14" 14 "Frame_15" 15 "Frame_16" ;
VAL_ 527 TotalFrameNumber 0 "One_Frame" 1 "Two_Frames" 2 "Three_Frames" 3 "Four_Frames" 4 "Five_Frames" 5 "Six_Frames" 6 "Seven_Frames" 7 "Eight_Frame" 8 "Nine_Frames" 9 "Ten_Frames" 10 "Eleven_Frames" 11 "Twelve_Frames" 12 "Thirteen_Frames" 13 "Fourteen_Frames" 14 "Fifteen_Frames" 15 "Sixteen_Frames" ;
VAL_ 542 PTRInfo 0 "SN" 1 "CPN" 3 "SUPPLIER" ;
VAL_ 782 Gas_Range 1023 "SNA" ;
VAL_ 782 CFG_Manual_DPF 0 "CFG_DEF" 1 "CFG_START" 2 "CFG_RESERVED" 3 "SNA" ;
VAL_ 938 A_MPG 1023 "SNA" ;
VAL_ 939 A_KMpL 1023 "SNA" ;
VAL_ 940 A_Total_Dist_Miles 16777215 "SNA" ;
VAL_ 940 A_Total_Dist_Kilometers 16777215 "SNA" ;
VAL_ 941 B_MPG 1023 "SNA" ;
VAL_ 942 B_KMpL 1023 "SNA" ;
VAL_ 943 B_Total_Dist_Miles 16777215 "SNA" ;
VAL_ 943 B_Total_Dist_Kilometers 16777215 "SNA" ;
VAL_ 55 EngTrqRq_2 8191 "SNA" ;
VAL_ 55 MaxTrqDes_2 8191 "SNA" ;
VAL_ 55 TrnsTrqReqSlow_2 8191 "SNA" ;
VAL_ 55 TrqCtrlModeRq_2 0 "NONE" 1 "TRQ_INC_Fast" 2 "TRQ_DEC_Fast" 7 "SNA" ;
VAL_ 1073 NM_Mode 252 "LHOM" 253 "RING" 254 "ALIVE" 255 "SNA" ;
VAL_ 1073 NM_Successor 255 "SNA" ;
VAL_ 1073 NM_Ud_Launch 4 "BROADCAST" 63 "SNA" ;
VAL_ 1073 Nw_Id 0 "POWERTRAIN" 1 "BODY" 2 "AUDIO_TELE" 255 "SNA" ;
VAL_ 973 WATER_IN_FUEL_STAT 0 "OFF" 1 "CONT" 2 "BLINK" 3 "SNA" ;
VAL_ 973 TIRE_PRESSURE_STAT 0 "OFF" 1 "CONT" 2 "BLINK" 3 "SNA" ;
VAL_ 973 STOP_START_STAT 0 "OFF" 1 "CONT" 2 "BLINK" 3 "SNA" ;
VAL_ 973 SERVICE_STAT 0 "OFF" 1 "CONT" 2 "BLINK" 3 "SNA" ;
VAL_ 973 SERVICE_ACC_STAT 0 "OFF" 1 "CONT" 2 "BLINK" 3 "SNA" ;
VAL_ 973 OVER_TEMP_STAT 0 "OFF" 1 "CONT" 2 "BLINK" 3 "SNA" ;
VAL_ 973 OIL_TEMP_STAT 0 "OFF" 1 "CONT" 2 "BLINK" 3 "SNA" ;
VAL_ 973 OIL_PRESSURE_STAT 0 "OFF" 1 "CONT" 2 "BLINK" 3 "SNA" ;
VAL_ 973 LANE_SENSE_STAT 0 "OFF" 1 "CONT" 2 "BLINK" 3 "SNA" ;
VAL_ 973 FOUR_WD_SERVICE_STAT 0 "OFF" 1 "CONT" 2 "BLINK" 3 "SNA" ;
VAL_ 973 FCW_SYSTEM_STAT 0 "OFF" 1 "CONT" 2 "BLINK" 3 "SNA" ;
VAL_ 973 ETC_CONTROL_STAT 0 "OFF" 1 "CONT" 2 "BLINK" 3 "SNA" ;
VAL_ 973 EPS_STAT 0 "OFF" 1 "CONT" 2 "BLINK" 3 "SNA" ;
VAL_ 973 EPB_WARN_STAT 0 "OFF" 1 "CONT" 2 "BLINK" 3 "SNA" ;
VAL_ 973 ENGINE_TEMP_STAT 0 "OFF" 1 "CONT" 2 "BLINK" 3 "SNA" ;
VAL_ 973 ENGINE_MIL_STAT 0 "OFF" 1 "CONT" 2 "BLINK" 3 "SNA" ;
VAL_ 973 ELEC_STAB_STAT 0 "OFF" 1 "CONT" 2 "BLINK" 3 "SNA" ;
VAL_ 973 DEF_STAT 0 "OFF" 1 "CONT" 2 "BLINK" 3 "SNA" ;
VAL_ 973 DAMPING_SYSTEM_STAT 0 "OFF" 1 "CONT" 2 "BLINK" 3 "SNA" ;
VAL_ 973 BRK_IND_STAT 0 "OFF" 1 "CONT" 2 "BLINK" 3 "SNA" ;
VAL_ 973 BRAKE_PAD_STAT 0 "OFF" 1 "CONT" 2 "BLINK" 3 "SNA" ;
VAL_ 973 BATTERY_CHARGE_STAT 0 "OFF" 1 "CONT" 2 "BLINK" 3 "SNA" ;
VAL_ 973 AWD_SERVICE_STAT 0 "OFF" 1 "CONT" 2 "BLINK" 3 "SNA" ;
VAL_ 973 ABS_IND_STAT 0 "OFF" 1 "CONT" 2 "BLINK" 3 "SNA" ;
VAL_ 973 WINDSHIELD_FLUID_STAT 0 "OFF" 1 "CONT" 2 "BLINK" 3 "SNA" ;
VAL_ 973 OIL_LEVEL_STAT 0 "OFF" 1 "CONT" 2 "BLINK" 3 "SNA" ;
VAL_ 973 FUEL_CAP_STAT 0 "OFF" 1 "CONT" 2 "BLINK" 3 "SNA" ;
VAL_ 973 COOLENT_LEVEL_STAT 0 "OFF" 1 "CONT" 2 "BLINK" 3 "SNA" ;
VAL_ 973 TORQUE_STAT 0 "OFF" 1 "CONT" 2 "BLINK" 3 "SNA" ;
VAL_ 973 ELECTRIC_WRENCH_STAT 0 "OFF" 1 "CONT" 2 "BLINK" 3 "SNA" ;
VAL_ 973 CATALYST_TEMP_STAT 0 "OFF" 1 "CONT" 2 "BLINK" 3 "SNA" ;
VAL_ 754 Inst_Fuel_Econ 1023 "SNA" ;
VAL_ 754 Avg_Fuel_Econ 1023 "SNA" ;
VAL_ 910 IBS3_TempFailStatus 0 "Fail_not_present" 1 "Fail_present" ;
VAL_ 910 IBS3_T_BATT 255 "SNA" ;
VAL_ 910 IBS3_SOH_Q_Accuracy 0 "Inaccurate" 1 "Accurate" ;
VAL_ 910 IBS3_SOH_Q 127 "SNA" ;
VAL_ 910 IBS3_SOF_VC 127 "SNA" ;
VAL_ 910 IBS3_SOF_V_Accuracy 0 "Inaccurate" 1 "Accurate" ;
VAL_ 910 IBS3_SOF_Q_Accuracy 0 "Inaccurate" 1 "Accurate" ;
VAL_ 910 IBS3_SOF_Q 255 "SNA" ;
VAL_ 910 IBS3_SOC_Accuracy 0 "Inaccurate" 1 "Accurate" ;
VAL_ 910 IBS3_SOC 127 "SNA" ;
VAL_ 910 IBS3_FLAG_DISCONNECT 0 "No_Disconnect" 1 "Disconnect" ;
VAL_ 910 Ft_RrAxleLckr_Rq 0 "NPSD" 1 "PSD" 2 "NDEF2" 3 "SNA" ;
VAL_ 579 AxleLckrOFF_SW 0 "NOT_PSD" 1 "PSD" 3 "SNA" ;
VAL_ 579 TGW_AUD_MD2_CAB_DR 0 "NONE" 1 "Android_Auto" 2 "Apple_CarPlay" 3 "Music_Muted" 4 "Baidu_CarLife" ;
VAL_ 683 VoltBattFailStatus 0 "Fail_not_present" 1 "Fail_present" ;
VAL_ 683 RsErrIBS3 0 "NO_ERROR" 1 "ERROR" ;
VAL_ 683 IBS3_Vbatt 511 "SNA" ;
VAL_ 683 IBS3_Ibatt 65535 "SNA" ;
VAL_ 683 IBS3_Error_Internal 0 "NO_ERROR" 1 "ERROR" ;
VAL_ 683 CurrBattFailStatus 0 "Fail_not_present" 1 "Fail_present" ;
VAL_ 685 Cfg_Aux_PTO 0 "NONE" 3 "FOUR_CUTOFF" 4 "FOUR" 5 "FIVE" 6 "SIX" 7 "SNA" ;
VAL_ 881 SwayBarEVICDisplay 0 "TM0" 1 "TM1" 2 "TM2" 3 "TM3" 4 "TM4" 5 "TM5" 6 "TM6" 7 "TM7" 8 "TM8" 9 "TM9" 10 "TM10" 11 "TM11" 12 "TM12" 13 "TM13" 14 "TM14" 15 "SNA" ;
VAL_ 881 SwayBar_Sts 0 "UNLOCKED" 1 "LOCKED" 2 "S_I_P" 3 "SNA" ;
VAL_ 881 SwayBar_LEDRq 0 "OFF" 1 "CONT" 2 "BLINK" 3 "SNA" ;
VAL_ 739 CNG_GaLvl 255 "SNA" ;
VAL_ 739 EngRunFuelTyp 0 "IND_GCLMPS_OFF" 1 "IND_GLMP_OFF" 2 "IND_GLMP_ON" 3 "IND_GLMP_FLASH" 4 "IND_CLMP_OFF" 5 "IND_CLMP_ON" 6 "IND_CLMP_FLASH" 7 "SNA" ;
VAL_ 676 MAP_4_Bar 511 "SNA" ;
VAL_ 676 ECM_WARN_EXT 0 "NONE" 1 "WARN_EXT_1" 2 "WARN_EXT_2" 3 "WARN_EXT_3" 4 "WARN_EXT_4" 5 "WARN_EXT_5" 6 "WARN_EXT_6" 7 "WARN_EXT_7" 8 "WARN_EXT_8" 9 "WARN_EXT_9" 10 "WARN_EXT_10" 12 "WARN_EXT_12" 13 "WARN_EXT_13" 14 "WARN_EXT_14" 15 "WARN_EXT_15" 16 "WARN_EXT_16" 17 "WARN_EXT_17" 18 "WARN_EXT_18" 19 "WARN_EXT_19" 20 "WARN_EXT_20" 21 "WARN_EXT_21" 22 "WARN_EXT_22" 23 "WARN_EXT_23" 24 "WARN_EXT_24" 25 "WARN_EXT_25" ;
VAL_ 676 TransWarmup_Min_RPM 255 "SNA" ;
VAL_ 963 VC_BU_VehCfgCSO3_Stat 0 "NA" 1 "PROGAMMED" 2 "REQUEST_DATA" 3 "SNA" ;
VAL_ 963 VC_BU_TRUNK_UNLOCK_ENABLE_CSO 0 "Absent" 1 "Present" ;
VAL_ 963 VC_BU_SPEED_THRESHOLD_CSO 0 "Absent" 1 "Present" ;
VAL_ 963 VC_BU_PEB_CSO 0 "Absent" 1 "Present" ;
VAL_ 963 VC_BU_EXTERNAL_LIGHT_SENSOR_CSO 0 "Absent" 1 "Present" ;
VAL_ 963 VC_BU_BUZZER_VOLUME_LEVEL_CSO 0 "Absent" 1 "Present" ;
VAL_ 963 VC_BU_AUTO_STOP_START_CSO 0 "Absent" 1 "Present" ;
VAL_ 963 VC_BU_AL_OR_PLUS_CSO 0 "Absent" 1 "Present" ;
VAL_ 963 VC_BU_AL_FFC_OR_PLUS_CSO 0 "Absent" 1 "Present" ;
VAL_ 963 VC_BU_CHMSL_DYN_CNTR_CSO 0 "Absent" 1 "Present" ;
VAL_ 962 VC_VehCfgCSO3_Stat 0 "NA" 1 "PROGAMMED" 2 "REQUEST_DATA" 3 "SNA" ;
VAL_ 962 VC_TRUNK_UNLOCK_ENABLE_CSO 0 "Absent" 1 "Present" ;
VAL_ 962 VC_SPEED_THRESHOLD_CSO 0 "Absent" 1 "Present" ;
VAL_ 962 VC_PEB_CSO 0 "Absent" 1 "Present" ;
VAL_ 962 VC_EXTERNAL_LIGHT_SENSOR_CSO 0 "Absent" 1 "Present" ;
VAL_ 962 VC_BUZZER_VOLUME_LEVEL_CSO 0 "Absent" 1 "Present" ;
VAL_ 962 VC_AUTO_STOP_START_CSO 0 "Absent" 1 "Present" ;
VAL_ 962 VC_AL_OR_PLUS_CSO 0 "Absent" 1 "Present" ;
VAL_ 962 VC_AL_FFC_OR_PLUS_CSO 0 "Absent" 1 "Present" ;
VAL_ 962 VC_CHMSL_DYN_CNTR_CSO 0 "Absent" 1 "Present" ;
VAL_ 907 VC_BU_VehCfg8_Stat 0 "NA" 1 "PROGAMMED" 2 "NA1" 3 "SNA" ;
VAL_ 907 VC_BU_Steering_Cfactor 0 "TYPE_1" 1 "TYPE_2" 2 "TYPE_3" 3 "TYPE_4" ;
VAL_ 907 VC_BU_Speedometer_Tolerance 0 "Tolerance_0" 1 "Tolerance_1" 2 "Tolerance_2" 3 "Tolerance_3" 4 "Tolerance_4" 5 "Tolerance_5" 6 "Tolerance_6" 7 "Tolerance_7" 8 "Tolerance_8" 9 "Tolerance_9" 10 "Tolerance_10" 11 "Tolerance_Neg1" 12 "Tolerance_Neg2" 13 "Tolerance_Neg3" 14 "Tolerance_Neg4" 15 "Tolerance_Neg5" ;
VAL_ 907 VC_BU_Increasing_Speed_Constant 0 "Increasing_0" 1 "Increasing_1" 2 "Increasing_2" 3 "Increasing_3" 4 "Increasing_4" 5 "Increasing_5" 6 "Increasing_6" 7 "Increasing_7" ;
VAL_ 907 VC_BU_WHL_BASE_LENGTH 0 "Not_Used" 1 "Length_1" 2 "Length_2" 3 "Length_3" 4 "Length_4" 5 "Length_5" 6 "Length_6" 7 "Length_7" 8 "Length_8" 9 "Length_9" 10 "Length_10" 11 "Length_11" 12 "Length_12" 13 "Length_13" 14 "Length_14" 15 "Length_15" ;
VAL_ 907 VC_BU_OHC_TYPE 0 "Not_Present" 1 "Base_OHC" 2 "Premium_OHC" 3 "SNA" ;
VAL_ 907 VC_BU_SBL_FBL_CORNERING_PRSNT 0 "Not_Present" 1 "SBL_FBL_Present" 2 "Cornering_Present" ;
VAL_ 907 VC_BU_PPPAHardBtn 0 "Not_Present" 1 "Present" ;
VAL_ 907 VC_BU_PEB_PRSNT 0 "Not_Present" 1 "Present" ;
VAL_ 907 VC_BU_DBL_PRSNT 0 "Not_Present" 1 "Present" ;
VAL_ 907 VC_BU_BEAM_SHAPING_PRSNT 0 "Not_Present" 1 "Present" ;
VAL_ 907 VC_BU_AVAC_PRSNT 0 "Not_Present" 1 "Present" ;
VAL_ 907 VC_BU_TACHO_TYPE 0 "DISABLED" 1 "TYP_1" 2 "TYP_2" 3 "TYP_3" ;
VAL_ 907 VC_BU_MARKET_HEADLAMP 0 "CONF_SNA" 1 "ECE" 2 "SAE" 3 "APAC" ;
VAL_ 906 VC_VehCfg8_Stat 0 "NA" 1 "PROGAMMED" 2 "REQUEST_DATA" 3 "SNA" ;
VAL_ 906 VC_Steering_Cfactor 0 "TYPE_1" 1 "TYPE_2" 2 "TYPE_3" 3 "TYPE_4" ;
VAL_ 906 VC_Speedometer_Tolerance 0 "Tolerance_0" 1 "Tolerance_1" 2 "Tolerance_2" 3 "Tolerance_3" 4 "Tolerance_4" 5 "Tolerance_5" 6 "Tolerance_6" 7 "Tolerance_7" 8 "Tolerance_8" 9 "Tolerance_9" 10 "Tolerance_10" 11 "Tolerance_Neg1" 12 "Tolerance_Neg2" 13 "Tolerance_Neg3" 14 "Tolerance_Neg4" 15 "Tolerance_Neg5" ;
VAL_ 906 VC_Increasing_Speed_Constant 0 "Increasing_0" 1 "Increasing_1" 2 "Increasing_2" 3 "Increasing_3" 4 "Increasing_4" 5 "Increasing_5" 6 "Increasing_6" 7 "Increasing_7" ;
VAL_ 906 VC_WHL_BASE_LENGTH 0 "Not_Used" 1 "Length_1" 2 "Length_2" 3 "Length_3" 4 "Length_4" 5 "Length_5" 6 "Length_6" 7 "Length_7" 8 "Length_8" 9 "Length_9" 10 "Length_10" 11 "Length_11" 12 "Length_12" 13 "Length_13" 14 "Length_14" 15 "Length_15" ;
VAL_ 906 VC_OHC_TYPE 0 "Not_Present" 1 "Base_OHC" 2 "Premium_OHC" 3 "SNA" ;
VAL_ 906 VC_SBL_FBL_CORNERING_PRSNT 0 "Not_Present" 1 "SBL_FBL_Present" 2 "Cornering_Present" ;
VAL_ 906 VC_PPPAHardBtn 0 "Not_Present" 1 "Present" ;
VAL_ 906 VC_PEB_PRSNT 0 "Not_Present" 1 "Present" ;
VAL_ 906 VC_DBL_PRSNT 0 "Not_Present" 1 "Present" ;
VAL_ 906 VC_BEAM_SHAPING_PRSNT 0 "Not_Present" 1 "Present" ;
VAL_ 906 VC_AVAC_PRSNT 0 "Not_Present" 1 "Present" ;
VAL_ 906 VC_TACHO_TYPE 0 "DISABLED" 1 "TYP_1" 2 "TYP_2" 3 "TYP_3" ;
VAL_ 906 VC_MARKET_HEADLAMP 0 "CONF_SNA" 1 "ECE" 2 "SAE" 3 "APAC" ;
VAL_ 687 TrlrTripDist 16777215 "SNA" ;
VAL_ 687 TrlrStyle_4 0 "NONE" 1 "TRAILER" 2 "BOAT" 3 "CAR" 4 "CARGO" 5 "DUMP" 6 "EQUIPMENT" 7 "FLAT" 8 "GOOSE" 9 "LIVESTOCK" 10 "HORSE" 11 "MOTORCYCLE" 12 "SNOWMOBILE" 13 "TRAVEL" 14 "UTILITY" 15 "FIFTH" 31 "SNA" ;
VAL_ 687 TrlrStyle_3 0 "NONE" 1 "TRAILER" 2 "BOAT" 3 "CAR" 4 "CARGO" 5 "DUMP" 6 "EQUIPMENT" 7 "FLAT" 8 "GOOSE" 9 "LIVESTOCK" 10 "HORSE" 11 "MOTORCYCLE" 12 "SNOWMOBILE" 13 "TRAVEL" 14 "UTILITY" 15 "FIFTH" 31 "SNA" ;
VAL_ 687 TrlrStyle_2 0 "NONE" 1 "TRAILER" 2 "BOAT" 3 "CAR" 4 "CARGO" 5 "DUMP" 6 "EQUIPMENT" 7 "FLAT" 8 "GOOSE" 9 "LIVESTOCK" 10 "HORSE" 11 "MOTORCYCLE" 12 "SNOWMOBILE" 13 "TRAVEL" 14 "UTILITY" 15 "FIFTH" 31 "SNA" ;
VAL_ 687 TrlrStyle_1 0 "NONE" 1 "TRAILER" 2 "BOAT" 3 "CAR" 4 "CARGO" 5 "DUMP" 6 "EQUIPMENT" 7 "FLAT" 8 "GOOSE" 9 "LIVESTOCK" 10 "HORSE" 11 "MOTORCYCLE" 12 "SNOWMOBILE" 13 "TRAVEL" 14 "UTILITY" 15 "FIFTH" 31 "SNA" ;
VAL_ 687 SelTrlrStyle 0 "NONE" 1 "TRAILER" 2 "BOAT" 3 "CAR" 4 "CARGO" 5 "DUMP" 6 "EQUIPMENT" 7 "FLAT" 8 "GOOSE" 9 "LIVESTOCK" 10 "HORSE" 11 "MOTORCYCLE" 12 "SNOWMOBILE" 13 "TRAVEL" 14 "UTILITY" 15 "FIFTH" 31 "SNA" ;
VAL_ 687 SelTrlrNum 0 "NONE" 1 "T1" 2 "T2" 3 "T3" 4 "T4" 7 "SNA" ;
VAL_ 629 IRCM_AHB_On 0 "OFF" 1 "ON" ;
VAL_ 875 ATMM_PopUpRqst 0 "TM0" 1 "TM1" 2 "TM2" 3 "SNA" ;
VAL_ 924 MsgFobBattLow 0 "MSG_DEFAULT" 1 "MSG_ACTIVE" 3 "SNA" ;
VAL_ 924 MsgFobNotFnd 0 "MSG_DEFAULT" 1 "MSG_ACTIVE" 3 "SNA" ;
VAL_ 924 MsgNotInPark 0 "MSG_DEFAULT" 1 "MSG_ACTIVE" 3 "SNA" ;
VAL_ 924 MsgKG1 0 "MSG_DEFAULT" 1 "MSG_ACTIVE" 3 "SNA" ;
VAL_ 924 FOB_SrchRslt 0 "NO_ACT" 1 "SIP" 2 "COMPLETE" 3 "TIMEOUT" ;
VAL_ 924 MsgKG2 0 "MSG_DEFAULT" 1 "MSG_ACTIVE" 3 "SNA" ;
VAL_ 818 A2D_DRV_TEMP_DR_POS 1023 "SNA" ;
VAL_ 818 Blower_Speed 511 "SNA" ;
VAL_ 818 Blower_Diagnostics 1023 "SNA" ;
VAL_ 181 TrqRq_SlowFast 2047 "SNA" ;
VAL_ 181 EngRPM_Tach 65535 "SNA" ;
VAL_ 179 TransLosses 1023 "SNA" ;
VAL_ 774 Tire_RR2 0 "NORMAL" 1 "LOW" 2 "HIGH" 3 "SNA" ;
VAL_ 774 Tire_RL2 0 "NORMAL" 1 "LOW" 2 "HIGH" 3 "SNA" ;
VAL_ 774 TirePrssRR2 255 "SNA" ;
VAL_ 774 TirePrssRL2 255 "SNA" ;
VAL_ 960 TrqC_Temp 255 "SNA" ;
VAL_ 302 STFARrAlertPress 255 "SNA" ;
VAL_ 302 STFAFtAlertPress 255 "SNA" ;
VAL_ 302 SelectedTPMTrailer_Number 0 "TRAILER_NOT_SELECTED" 1 "TRAILER_1" 2 "TRAILER_2" 3 "TRAILER_3" 4 "TRAILER_4" 7 "SNA" ;
VAL_ 302 Program_Single_TPM 0 "TIRE_NOT_SELECTED" 1 "TIRE1" 2 "TIRE2" 3 "TIRE3" 4 "TIRE4" 5 "TIRE5" 6 "TIRE6" 7 "TIRE7" 8 "TIRE8" 9 "TIRE9" 10 "TIRE10" 11 "TIRE11" 12 "TIRE12" 15 "SNA" ;
VAL_ 302 Number_of_Trl_Tires 0 "TRL_TIRE_NOT_SELECTED" 1 "TWO_TIRES" 2 "FOUR_TIRES" 3 "SIX_TIRES" 4 "EIGHT_TIRES" 5 "TWELVE_TIRES" 7 "SNA" ;
VAL_ 302 Number_of_Trl_Axles 0 "TRL_AXLE_NOT_SELECTED" 1 "ONE_AXLE" 2 "TWO_AXLES" 3 "THREE_AXLES" 7 "SNA" ;
VAL_ 302 Clear_Trailer_TPM_Settings 0 "TRAILER_NOT_SELECTED" 1 "TRAILER_1" 2 "TRAILER_2" 3 "TRAILER_3" 4 "TRAILER_4" 7 "SNA" ;
VAL_ 903 ITBM_TrlrStat 0 "NO_TRLR" 1 "TRLR_PRSNT" 2 "TRLR_DCONN" 3 "SNA" ;
VAL_ 903 ITBM_OP_PWR 255 "SNA" ;
VAL_ 903 ITBM_GAIN_STAT 31 "SNA" ;
VAL_ 903 ITBM_DSP_RQ 0 "NO_DISP_RQ" 1 "FLT_TRLR_WIRE" 2 "FLT_ITBM" 3 "FLT_TRLR_DCONN" 4 "GAIN_ADJ" 5 "FLT_CONN" 6 "TLR_NOT_CONN" 7 "MANUAL" 8 "SAFE" 15 "SNA" ;
VAL_ 903 ITBM_BrkStyle 0 "LT_ELECT" 1 "HV_ELECT" 2 "LT_EOH" 3 "HV_EOH" ;
VAL_ 903 ITBM_BRK_SW 0 "BRAKE_OFF" 1 "BRAKE_ON" 3 "SNA" ;
VAL_ 341 SEIU_Sts 0 "SEIU_On" 1 "SEIU_Off" 2 "SPEED_LT2" 3 "PARK" 4 "REL_CLUTCH" 5 "REL_BRAKE" 6 "ECT_HIGH" 7 "EOT_HIGH" 8 "FAULT" 9 "RPM_HIGH" 10 "RPM_MIN" 11 "REL_ACC" 12 "COLD" 13 "MESS1" 15 "SNA" ;
VAL_ 341 SEIU_RPM 255 "SNA" ;
VAL_ 341 PTO_Target_Gear 0 "Gear_4" 1 "Gear_5" 2 "Gear_6" 7 "SNA" ;
VAL_ 341 PTO_Remote_RPM_Method 0 "Set_Speed" 1 "Throttle" 2 "J1939_Command" 3 "SNA" ;
VAL_ 341 PTO_Ramp_Rate 0 "FIFTY" 1 "SEVENTY_FIVE" 2 "HUNDRED" 3 "ONE_HUNDRED_TWENTY_FIVE" 4 "ONE_HUNDRED_FIFTY" 5 "ONE_HUNDRED_SEVENTY_FIVE" 6 "TWO_HUNDRED" 7 "TWO_HUNDRED_TWENTY_FIVE" 8 "TWO_HUNDRED_FIFTY" 9 "TWO_HUNDRED_SEVENTY_FIVE" 10 "THREE_HUNDRED" 11 "THREE_HUNDRED_TWENTY_FIVE" 12 "THREE_HUNDRED_FIFTY" 13 "THREE_HUNDRED_SEVENTY_FIVE" 14 "FOUR_HUNDRED" 15 "FOUR_HUNDRED_TWENTY_FIVE" 16 "FOUR_HUNDRED_FIFTY" 17 "FOUR_HUNDRED_SEVENTY_FIVE" 18 "FIVE_HUNDRED" 31 "SNA" ;
VAL_ 341 PTO_High_Idle_RPM 255 "SNA" ;
VAL_ 341 PTO_Active 0 "OFF" 1 "Blinking" 2 "Solid_ON" 3 "SNA" ;
VAL_ 564 AM_ECM_Trace 0 "DEFAULT" 2 "AM_ECM_TRACE" 3 "SNA" ;
VAL_ 664 ASCM_HMI_Stat2 0 "NONE" 1 "BDL_Enbl" 2 "BDL_Complete" 3 "BDL_Unsucc" 15 "SNA" ;
VAL_ 811 AxlLckrSts 0 "UNLOCKED" 1 "RR_LKD" 2 "FR_RR_LKD" 3 "SNA" ;
VAL_ 811 AxleLockerEVICDisplay 0 "NONE" 1 "SCREEN_1" 2 "SCREEN_2" 3 "SCREEN_3" 4 "SCREEN_4" 5 "SCREEN_5" 6 "SCREEN_6" 7 "SCREEN_7" 8 "SCREEN_8" 9 "SCREEN_9" 15 "SNA" ;
VAL_ 811 RrAxleLockerIndRq 0 "OFF" 1 "ON" 2 "BLINK" 3 "SNA" ;
VAL_ 811 Ft_RrAxleLockerIndRq 0 "OFF" 1 "ON" 2 "BLINK" 3 "SNA" ;
VAL_ 811 AxleUnlockIndRq 0 "OFF" 1 "ON" 2 "BLINK" 3 "SNA" ;
VAL_ 811 AXLE_LCKR_SRV_RQ 0 "OFF" 1 "ON" 2 "BLINK" 3 "SNA" ;
VAL_ 560 EVAP_TEMP 255 "SNA" ;
VAL_ 560 EvapTempTar 255 "SNA" ;
VAL_ 560 PTC_Enbl 1 "SNA" ;
VAL_ 821 TrlTPMSetPress_TTPM 255 "SNA" ;
VAL_ 821 Trailer_Sensor_Mismatch 0 "TRAILER_NOT_SELECTED" 1 "TRAILER_1" 2 "TRAILER_2" 3 "TRAILER_3" 4 "TRAILER_4" ;
VAL_ 821 TPMTrailer_Number 0 "TRAILER_NOT_SELECTED" 1 "TRAILER_1" 2 "TRAILER_2" 3 "TRAILER_3" 4 "TRAILER_4" ;
VAL_ 821 TPMSensor_Programmed 0 "TIRE_NOT_SELECTED" 1 "TIRE1" 2 "TIRE2" 3 "TIRE3" 4 "TIRE4" 5 "TIRE5" 6 "TIRE6" 7 "TIRE7" 8 "TIRE8" 9 "TIRE9" 10 "TIRE10" 11 "TIRE11" 12 "TIRE12" ;
VAL_ 821 TPMLearnHornChirp 0 "HORN_CHIRP_OFF" 1 "SINGLE_HORN_CHIRP" 2 "MULTIPLE_HORN_CHIRP" ;
VAL_ 821 Number_of_Trl_Tires_TTPM 0 "TRL_TIRE_NOT_SELECTED" 1 "TWO_TIRES" 2 "FOUR_TIRES" 3 "SIX_TIRES" 4 "EIGHT_TIRES" 5 "TWELVE_TIRES" ;
VAL_ 821 Number_of_Trl_Axles_TTPM 0 "TRL_AXLE_NOT_SELECTED" 1 "ONE_AXLE" 2 "TWO_AXLES" 3 "THREE_AXLES" ;
VAL_ 813 TrlTire9_Stat 0 "NORMAL" 1 "LOW" 2 "HIGH" 3 "SNA" ;
VAL_ 813 TrlTire8_Stat 0 "NORMAL" 1 "LOW" 2 "HIGH" 3 "SNA" ;
VAL_ 813 TrlTire7_Stat 0 "NORMAL" 1 "LOW" 2 "HIGH" 3 "SNA" ;
VAL_ 813 TrlTire12_Stat 0 "NORMAL" 1 "LOW" 2 "HIGH" 3 "SNA" ;
VAL_ 813 TrlTire11_Stat 0 "NORMAL" 1 "LOW" 2 "HIGH" 3 "SNA" ;
VAL_ 813 TrlTire10_Stat 0 "NORMAL" 1 "LOW" 2 "HIGH" 3 "SNA" ;
VAL_ 813 TrailerTirePress9 255 "SNA" ;
VAL_ 813 TrailerTirePress8 255 "SNA" ;
VAL_ 813 TrailerTirePress7 255 "SNA" ;
VAL_ 813 TrailerTirePress12 255 "SNA" ;
VAL_ 813 TrailerTirePress11 255 "SNA" ;
VAL_ 813 TrailerTirePress10 255 "SNA" ;
VAL_ 812 TrlTire6_Stat 0 "NORMAL" 1 "LOW" 2 "HIGH" 3 "SNA" ;
VAL_ 812 TrlTire5_Stat 0 "NORMAL" 1 "LOW" 2 "HIGH" 3 "SNA" ;
VAL_ 812 TrlTire4_Stat 0 "NORMAL" 1 "LOW" 2 "HIGH" 3 "SNA" ;
VAL_ 812 TrlTire3_Stat 0 "NORMAL" 1 "LOW" 2 "HIGH" 3 "SNA" ;
VAL_ 812 TrlTire2_Stat 0 "NORMAL" 1 "LOW" 2 "HIGH" 3 "SNA" ;
VAL_ 812 TrlTire1_Stat 0 "NORMAL" 1 "LOW" 2 "HIGH" 3 "SNA" ;
VAL_ 812 TrailerTirePress6 255 "SNA" ;
VAL_ 812 TrailerTirePress5 255 "SNA" ;
VAL_ 812 TrailerTirePress4 255 "SNA" ;
VAL_ 812 TrailerTirePress3 255 "SNA" ;
VAL_ 812 TrailerTirePress2 255 "SNA" ;
VAL_ 812 TrailerTirePress1 255 "SNA" ;
VAL_ 388 CustKeyInIgn 0 "CUST_KEY_DEFAULT" 1 "CUST_KEY_NOT_IN_IGNITION" 2 "CUST_KEY_IN_IGNITION" 3 "SNA" ;
VAL_ 388 IgnPos 0 "IGN_LK" 3 "IGN_OFF_ACC" 4 "IGN_RUN" 5 "IGN_START" 7 "SNA" ;
VAL_ 388 ValImmKey 0 "CUST_IMMOB_KEY_DEFAULT" 1 "CUST_IMMOB_KEY_VALID" 3 "SNA" ;
VAL_ 1048 NM_Mode 252 "LHOM" 253 "RING" 254 "ALIVE" 255 "SNA" ;
VAL_ 1048 NM_Successor 255 "SNA" ;
VAL_ 1048 NM_Ud_Launch 4 "BROADCAST" 63 "SNA" ;
VAL_ 1048 Nw_Id 0 "POWERTRAIN" 1 "BODY" 2 "AUDIO_TELE" 255 "SNA" ;
VAL_ 274 CmdIgnStat 0 "IGN_LK" 3 "IGN_OFF_ACC" 4 "IGN_RUN" 5 "IGN_START" 7 "SNA" ;
VAL_ 274 StTyp 0 "ST_NOT_ACT" 1 "NOR_ST" 2 "TIP_ST" 3 "REM_ST" 7 "SNA" ;
VAL_ 274 KeyInIgn 0 "KEY_DEF" 1 "KEY_NOT_IN_IGN" 2 "KEY_IN_IGN" 3 "SNA" ;
